VERSION ""

NS_ :

BS_:

BU_: AHLM ASBS CADM CBC DIAGNOST DPDM DTCM ECM EHPS ESC ESL ESM ETM EVCU2 GPF IC IRCM LTM OCM ORC PTS RF_HUB SCCM SGW TBM TCM

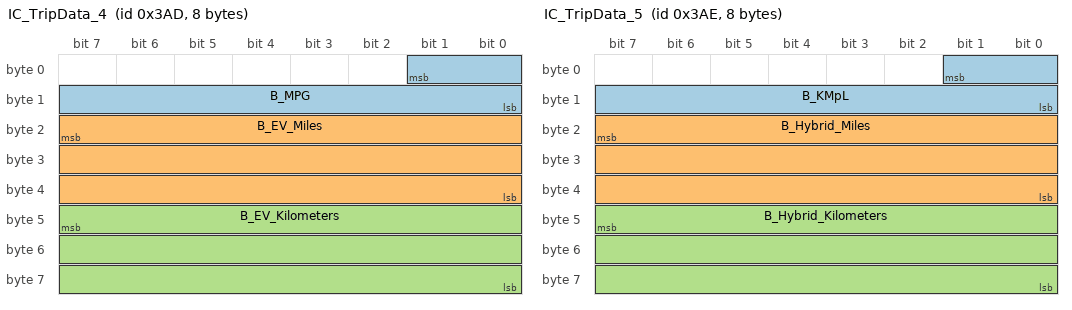
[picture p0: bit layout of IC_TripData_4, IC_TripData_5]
BO_ 941 IC_TripData_4: 8 IC
 SG_ B_MPG : 1|10@0+ (0.1,0) [0|99.9] "MPG"  ETM,SGW,TBM
 SG_ B_EV_Miles : 23|24@0+ (0.1,0) [0|9999.9] "Mile"  ETM,SGW,TBM
 SG_ B_EV_Kilometers : 47|24@0+ (0.1,0) [0|16093.3] "km"  ETM,SGW,TBM

BO_ 942 IC_TripData_5: 8 IC
 SG_ B_KMpL : 1|10@0+ (0.1,0) [0|99.9] "kmpl"  ETM,SGW,TBM
 SG_ B_Hybrid_Miles : 23|24@0+ (0.1,0) [0|9999.9] "Mile"  ETM,SGW,TBM
 SG_ B_Hybrid_Kilometers : 47|24@0+ (0.1,0) [0|16093.3] "km"  ETM,SGW,TBM

BO_ 943 IC_TripData_6: 8 IC
 SG_ B_Total_Dist_Miles : 23|24@0+ (0.1,0) [0|9999.9] "Mile"  ETM,SGW,TBM
 SG_ B_Total_Dist_Kilometers : 47|24@0+ (0.1,0) [0|16093.3] "km"  ETM,SGW,TBM

BO_ 944 TCM_APPL2: 8 DIAGNOST
 SG_ TCM_APPL2 : 7|64@0+ (1,0) [0|0] ""  TCM

BO_ 945 TCM_APPL1: 8 TCM
 SG_ TCM_APPL1 : 7|64@0+ (1,0) [0|0] ""  DIAGNOST,SGW

BO_ 946 TCM_APPL3: 8 TCM
 SG_ TCM_APPL3 : 7|64@0+ (1,0) [0|0] ""  DIAGNOST,SGW

BO_ 947 VehCfgCSM1: 8 CBC
 SG_ VC_PRK_AST_CSO : 2|2@1+ (1,0) [0|0] ""  RF_HUB,SGW
 SG_ VC_PRK_AST_BRK_CSO : 4|1@1+ (1,0) [0|0] ""  RF_HUB,SGW
 SG_ VC_PRK_FT_VOL_CSO : 5|1@1+ (1,0) [0|0] ""  RF_HUB,SGW
 SG_ VC_PRK_RR_VOL_CSO : 6|1@1+ (1,0) [0|0] ""  RF_HUB,SGW
 SG_ VC_EPS_CSO : 7|1@1+ (1,0) [0|0] ""  RF_HUB,SGW
 SG_ VC_FCW_CSO : 8|2@1+ (1,0) [0|0] ""  RF_HUB,SGW
 SG_ VC_FCW_BRK_CSO : 10|1@1+ (1,0) [0|0] ""  RF_HUB,SGW
 SG_ VC_HRN_RMT_LK_CSO : 11|2@1+ (1,0) [0|0] ""  RF_HUB,SGW
 SG_ VC_HRN_RMT_ST_CSO : 13|1@1+ (1,0) [0|0] ""  RF_HUB,SGW
 SG_ VC_HRN_RMT_LWR_CSO : 14|1@1+ (1,0) [0|0] ""  RF_HUB,SGW
 SG_ VC_CHMSL_LINE_CSO : 15|1@1+ (1,0) [0|0] ""  RF_HUB,SGW
 SG_ VC_DCS_CSO : 16|2@1+ (1,0) [0|0] ""  RF_HUB,SGW
 SG_ VC_AUX_SWS_CSO : 18|2@1+ (1,0) [0|0] ""  RF_HUB,SGW
 SG_ VC_CMRA_GRDLNS_CSO : 20|2@1+ (1,0) [0|0] ""  RF_HUB,SGW
 SG_ VC_UNIT_SET_CSO : 22|1@1+ (1,0) [0|0] ""  RF_HUB,SGW
 SG_ VC_POLICE_PE_CSO : 23|1@1+ (1,0) [0|0] ""  RF_HUB,SGW
 SG_ VC_ACC_DLY_CSO : 24|1@1+ (1,0) [0|0] ""  RF_HUB,SGW
 SG_ VC_AFLS_CSO : 25|1@1+ (1,0) [0|0] ""  RF_HUB,SGW
 SG_ VC_AMB_DMR_CSO : 26|1@1+ (1,0) [0|0] ""  RF_HUB,SGW
 SG_ VC_ASCM_TJ_CSO : 27|1@1+ (1,0) [0|0] ""  RF_HUB,SGW
 SG_ VC_ASCM_WRN_CSO : 28|1@1+ (1,0) [0|0] ""  RF_HUB,SGW
 SG_ VC_AUTO_AERO_CSO : 29|1@1+ (1,0) [0|0] ""  RF_HUB,SGW
 SG_ VC_AUTO_HB_CSO : 30|1@1+ (1,0) [0|0] ""  RF_HUB,SGW
 SG_ VC_AUTO_PRK_CSO : 31|1@1+ (1,0) [0|0] ""  RF_HUB,SGW
 SG_ VC_BLIND_SPOT_CSO : 32|1@1+ (1,0) [0|0] ""  RF_HUB,SGW
 SG_ VC_CAPACITY_CSO : 33|1@1+ (1,0) [0|0] ""  RF_HUB,SGW
 SG_ VC_CLK_DSP_CSO : 34|1@1+ (1,0) [0|0] ""  RF_HUB,SGW
 SG_ VC_CMP_CAL_CSO : 35|1@1+ (1,0) [0|0] ""  RF_HUB,SGW
 SG_ VC_CMP_VAR_CSO : 36|1@1+ (1,0) [0|0] ""  RF_HUB,SGW
 SG_ VC_CONS_CSO : 37|1@1+ (1,0) [0|0] ""  RF_HUB,SGW
 SG_ VC_DISTANCE_CSO : 38|1@1+ (1,0) [0|0] ""  RF_HUB,SGW
 SG_ VC_DR_LK_CSO : 39|1@1+ (1,0) [0|0] ""  RF_HUB,SGW
 SG_ VC_DR_UNLK_CSO : 40|1@1+ (1,0) [0|0] ""  RF_HUB,SGW
 SG_ VC_DRL_CSO : 41|1@1+ (1,0) [0|0] ""  RF_HUB,SGW
 SG_ VC_EASY_EXIT_CSO : 42|1@1+ (1,0) [0|0] ""  RF_HUB,SGW
 SG_ VC_ENTRY_EXIT_CSO : 43|1@1+ (1,0) [0|0] ""  RF_HUB,SGW
 SG_ VC_EPB_SERV_CSO : 44|1@1+ (1,0) [0|0] ""  RF_HUB,SGW
 SG_ VC_FLSH_LMP_LK_CSO : 45|1@1+ (1,0) [0|0] ""  RF_HUB,SGW
 SG_ VC_HL_DRP_CSO : 46|1@1+ (1,0) [0|0] ""  RF_HUB,SGW
 SG_ VC_HL_OFF_DLY_CSO : 47|1@1+ (1,0) [0|0] ""  RF_HUB,SGW
 SG_ VC_HL_WPR_CSO : 48|1@1+ (1,0) [0|0] ""  RF_HUB,SGW
 SG_ VC_HSA_CSO : 49|1@1+ (1,0) [0|0] ""  RF_HUB,SGW
 SG_ VC_ILL_APPRCH_CSO : 50|1@1+ (1,0) [0|0] ""  RF_HUB,SGW
 SG_ VC_LDW_TRQ_CSO : 51|1@1+ (1,0) [0|0] ""  RF_HUB,SGW
 SG_ VC_LDW_WRN_CSO : 52|1@1+ (1,0) [0|0] ""  RF_HUB,SGW
 SG_ VC_LGHT_RMT_LWR_CSO : 53|1@1+ (1,0) [0|0] ""  RF_HUB,SGW
 SG_ VC_NAV_TRN_CSO : 54|1@1+ (1,0) [0|0] ""  RF_HUB,SGW
 SG_ VC_PE_CSO : 55|1@1+ (1,0) [0|0] ""  RF_HUB,SGW
 SG_ VC_PER_SHFT_ENBL_CSO : 56|1@1+ (1,0) [0|0] ""  RF_HUB,SGW
 SG_ VC_PER_SHFT_RPM_CSO : 57|1@1+ (1,0) [0|0] ""  RF_HUB,SGW
 SG_ VC_PLG_CHM_CSO : 58|1@1+ (1,0) [0|0] ""  RF_HUB,SGW
 SG_ VC_POWER_CSO : 59|1@1+ (1,0) [0|0] ""  RF_HUB,SGW
 SG_ VC_PRESSURE_CSO : 60|1@1+ (1,0) [0|0] ""  RF_HUB,SGW
 SG_ VC_PTO_CSO : 61|1@1+ (1,0) [0|0] ""  RF_HUB,SGW
 SG_ VC_RAIN_WPR_CSO : 62|1@1+ (1,0) [0|0] ""  RF_HUB,SGW
 SG_ VC_REAR_CMRA_CSO : 63|1@1+ (1,0) [0|0] ""  RF_HUB,SGW
 SG_ VC_VehCfgCSO1_Stat : 0|2@1+ (1,0) [0|0] ""  EVCU2,IC,RF_HUB,SGW

BO_ 948 VehCfgCSM2: 8 CBC
 SG_ VC_TEEN_BLIND_SPOT_CSO : 31|1@1+ (1,0) [0|0] ""  RF_HUB,SGW
 SG_ VC_TEEN_RAIN_WPR_CSO : 32|1@1+ (1,0) [0|0] ""  RF_HUB,SGW
 SG_ VC_TEEN_AUTO_HB_CSO : 33|1@1+ (1,0) [0|0] ""  RF_HUB,SGW
 SG_ VC_TEEN_LGHT_WPR_CSO : 34|1@1+ (1,0) [0|0] ""  RF_HUB,SGW
 SG_ VC_TEEN_SLD_DR_ALRT_CSO : 35|1@1+ (1,0) [0|0] ""  RF_HUB,SGW
 SG_ VC_TEEN_PLG_CHIME_CSO : 36|1@1+ (1,0) [0|0] ""  RF_HUB,SGW
 SG_ VC_SLD_DR_CHM_CSO : 37|1@1+ (1,0) [0|0] ""  RF_HUB,SGW
 SG_ VC_TEEN_SLD_DR_CHM_CSO : 38|1@1+ (1,0) [0|0] ""  RF_HUB,SGW
 SG_ VC_PADDLE_SHIFT_CSO : 39|1@1+ (1,0) [0|0] ""  RF_HUB,SGW
 SG_ VC_FLSH_LMP_SLDR_CSO : 40|1@1+ (1,0) [0|0] ""  RF_HUB,SGW
 SG_ VC_SPEED_WARNING_CSO : 41|2@1+ (1,0) [0|0] ""  RF_HUB,SGW
 SG_ VC_LDW_ON_CSO : 43|1@1+ (1,0) [0|0] ""  RF_HUB,SGW
 SG_ VC_PRK_ASST_TYPE_CSO : 44|1@1+ (1,0) [0|0] ""  RF_HUB,SGW
 SG_ VC_SPEED_CSO : 5|1@1+ (1,0) [0|0] ""  RF_HUB,SGW
 SG_ VC_TLT_MRR_CSO : 6|1@1+ (1,0) [0|0] ""  RF_HUB,SGW
 SG_ VC_TORQUE_CSO : 7|1@1+ (1,0) [0|0] ""  RF_HUB,SGW
 SG_ VC_TRLR_CSO : 8|1@1+ (1,0) [0|0] ""  RF_HUB,SGW
 SG_ VC_TRLR_NAME_CSO : 9|1@1+ (1,0) [0|0] ""  RF_HUB,SGW
 SG_ VC_TRLR_TYPE_CSO : 10|1@1+ (1,0) [0|0] ""  RF_HUB,SGW
 SG_ VC_TRNS_MD_CSO : 11|1@1+ (1,0) [0|0] ""  RF_HUB,SGW
 SG_ VC_US_METRIC_CSO : 12|1@1+ (1,0) [0|0] ""  RF_HUB,SGW
 SG_ VC_EPB_ON_CSO : 45|1@1+ (1,0) [0|0] ""  RF_HUB,SGW
 SG_ VC_AIRBAG_ON_CSO : 46|1@1+ (1,0) [0|0] ""  IC,RF_HUB,SGW
 SG_ VC_FCW_SW_CSO : 47|1@1+ (1,0) [0|0] ""  RF_HUB,SGW
 SG_ VC_FCW_WARN_BRK_CSO : 49|1@1+ (1,0) [0|0] ""  RF_HUB,SGW
 SG_ VC_DOORS_OFF_ACC_DLY_CSO : 50|1@1+ (1,0) [0|0] ""  RF_HUB,SGW
 SG_ VC_TEEN_PRK_ASST_BRK_CSO : 51|1@1+ (1,0) [0|0] ""  RF_HUB,SGW
 SG_ VC_PCS_CSO : 52|1@1+ (1,0) [0|0] ""  RF_HUB,SGW
 SG_ VC_BSM_TRLR_CSO : 53|1@1+ (1,0) [0|0] ""  RF_HUB,SGW
 SG_ VC_AUTO_SS_CSO : 54|1@1+ (1,0) [0|0] ""  RF_HUB,SGW
 SG_ VC_RDY_DRV_CSO : 55|1@1+ (1,0) [0|0] ""  RF_HUB,SGW
 SG_ VC_VehCfgCSO2_Stat : 0|2@1+ (1,0) [0|0] ""  EVCU2,IC,RF_HUB,SGW
 SG_ VC_REAR_CMRA_DLY_CSO : 2|1@1+ (1,0) [0|0] ""  RF_HUB,SGW
 SG_ VC_RKE_MEM_CSO : 3|1@1+ (1,0) [0|0] ""  RF_HUB,SGW
 SG_ VC_RKE_UNLK_CSO : 4|1@1+ (1,0) [0|0] ""  RF_HUB,SGW
 SG_ VC_WHL_ALGN_CSO : 13|1@1+ (1,0) [0|0] ""  RF_HUB,SGW
 SG_ VC_FUEL_SAV_CSO : 14|1@1+ (1,0) [0|0] ""  RF_HUB,SGW
 SG_ VC_TEMP_CSO : 15|1@1+ (1,0) [0|0] ""  RF_HUB,SGW
 SG_ VC_HOLD_N_GO_CSO : 16|1@1+ (1,0) [0|0] ""  RF_HUB,SGW
 SG_ VC_PWR_FLD_MRR_CSO : 17|1@1+ (1,0) [0|0] ""  RF_HUB,SGW
 SG_ VC_HANDS_FREE_LFT_CSO : 18|1@1+ (1,0) [0|0] ""  RF_HUB,SGW
 SG_ VC_HANDS_FREE_SLDR_CSO : 19|1@1+ (1,0) [0|0] ""  RF_HUB,SGW
 SG_ VC_SVC_GRIDLINES_CSO : 20|1@1+ (1,0) [0|0] ""  RF_HUB,SGW
 SG_ VC_SVC_DELAY_CSO : 21|1@1+ (1,0) [0|0] ""  RF_HUB,SGW
 SG_ VC_SLD_DR_ALRT_CSO : 22|1@1+ (1,0) [0|0] ""  RF_HUB,SGW
 SG_ VC_TEEN_FCW_SENS_CSO : 23|1@1+ (1,0) [0|0] ""  RF_HUB,SGW
 SG_ VC_TEEN_FCW_BRK_CSO : 24|1@1+ (1,0) [0|0] ""  RF_HUB,SGW
 SG_ VC_TEEN_PRK_ASST_CSO : 25|1@1+ (1,0) [0|0] ""  RF_HUB,SGW
 SG_ VC_TEEN_FT_PRK_VOL_CSO : 26|1@1+ (1,0) [0|0] ""  RF_HUB,SGW
 SG_ VC_TEEN_RR_PRK_VOL_CSO : 27|1@1+ (1,0) [0|0] ""  RF_HUB,SGW
 SG_ VC_TEEN_MAX_SPEED_CSO : 28|1@1+ (1,0) [0|0] ""  RF_HUB,SGW
 SG_ VC_TEEN_FUEL_WRN_CSO : 29|1@1+ (1,0) [0|0] ""  RF_HUB,SGW
 SG_ VC_TEEN_FUEL_POPUP_CSO : 30|1@1+ (1,0) [0|0] ""  RF_HUB,SGW

BO_ 949 VehCfgCSM1_BU: 8 RF_HUB
 SG_ VC_BU_VehCfgCSO1_Stat : 0|2@1+ (1,0) [0|0] ""  CBC,SGW
 SG_ VC_BU_PRK_AST_CSO : 2|2@1+ (1,0) [0|0] ""  CBC,SGW
 SG_ VC_BU_PRK_AST_BRK_CSO : 4|1@1+ (1,0) [0|0] ""  CBC,SGW
 SG_ VC_BU_PRK_FT_VOL_CSO : 5|1@1+ (1,0) [0|0] ""  CBC,SGW
 SG_ VC_BU_PRK_RR_VOL_CSO : 6|1@1+ (1,0) [0|0] ""  CBC,SGW
 SG_ VC_BU_EPS_CSO : 7|1@1+ (1,0) [0|0] ""  CBC,SGW
 SG_ VC_BU_FCW_CSO : 8|2@1+ (1,0) [0|0] ""  CBC,SGW
 SG_ VC_BU_FCW_BRK_CSO : 10|1@1+ (1,0) [0|0] ""  CBC,SGW
 SG_ VC_BU_HRN_RMT_LK_CSO : 11|2@1+ (1,0) [0|0] ""  CBC,SGW
 SG_ VC_BU_HRN_RMT_ST_CSO : 13|1@1+ (1,0) [0|0] ""  CBC,SGW
 SG_ VC_BU_HRN_RMT_LWR_CSO : 14|1@1+ (1,0) [0|0] ""  CBC,SGW
 SG_ VC_BU_CHMSL_LINE_CSO : 15|1@1+ (1,0) [0|0] ""  CBC,SGW
 SG_ VC_BU_DCS_CSO : 16|2@1+ (1,0) [0|0] ""  CBC,SGW
 SG_ VC_BU_AUX_SWS_CSO : 18|2@1+ (1,0) [0|0] ""  CBC,SGW
 SG_ VC_BU_CMRA_GRDLNS_CSO : 20|2@1+ (1,0) [0|0] ""  CBC,SGW
 SG_ VC_BU_UNIT_SET_CSO : 22|1@1+ (1,0) [0|0] ""  CBC,SGW
 SG_ VC_BU_POLICE_PE_CSO : 23|1@1+ (1,0) [0|0] ""  CBC,SGW
 SG_ VC_BU_ACC_DLY_CSO : 24|1@1+ (1,0) [0|0] ""  CBC,SGW
 SG_ VC_BU_AFLS_CSO : 25|1@1+ (1,0) [0|0] ""  CBC,SGW
 SG_ VC_BU_AMB_DMR_CSO : 26|1@1+ (1,0) [0|0] ""  CBC,SGW
 SG_ VC_BU_ASCM_TJ_CSO : 27|1@1+ (1,0) [0|0] ""  CBC,SGW
 SG_ VC_BU_ASCM_WRN_CSO : 28|1@1+ (1,0) [0|0] ""  CBC,SGW
 SG_ VC_BU_AUTO_AERO_CSO : 29|1@1+ (1,0) [0|0] ""  CBC,SGW
 SG_ VC_BU_AUTO_HB_CSO : 30|1@1+ (1,0) [0|0] ""  CBC,SGW
 SG_ VC_BU_AUTO_PRK_CSO : 31|1@1+ (1,0) [0|0] ""  CBC,SGW
 SG_ VC_BU_BLIND_SPOT_CSO : 32|1@1+ (1,0) [0|0] ""  CBC,SGW
 SG_ VC_BU_CAPACITY_CSO : 33|1@1+ (1,0) [0|0] ""  CBC,SGW
 SG_ VC_BU_CLK_DSP_CSO : 34|1@1+ (1,0) [0|0] ""  CBC,SGW
 SG_ VC_BU_CMP_CAL_CSO : 35|1@1+ (1,0) [0|0] ""  CBC,SGW
 SG_ VC_BU_CMP_VAR_CSO : 36|1@1+ (1,0) [0|0] ""  CBC,SGW
 SG_ VC_BU_CONS_CSO : 37|1@1+ (1,0) [0|0] ""  CBC,SGW
 SG_ VC_BU_DISTANCE_CSO : 38|1@1+ (1,0) [0|0] ""  CBC,SGW
 SG_ VC_BU_DR_LK_CSO : 39|1@1+ (1,0) [0|0] ""  CBC,SGW
 SG_ VC_BU_DR_UNLK_CSO : 40|1@1+ (1,0) [0|0] ""  CBC,SGW
 SG_ VC_BU_DRL_CSO : 41|1@1+ (1,0) [0|0] ""  CBC,SGW
 SG_ VC_BU_EASY_EXIT_CSO : 42|1@1+ (1,0) [0|0] ""  CBC,SGW
 SG_ VC_BU_ENTRY_EXIT_CSO : 43|1@1+ (1,0) [0|0] ""  CBC,SGW
 SG_ VC_BU_EPB_SERV_CSO : 44|1@1+ (1,0) [0|0] ""  CBC,SGW
 SG_ VC_BU_FLSH_LMP_LK_CSO : 45|1@1+ (1,0) [0|0] ""  CBC,SGW
 SG_ VC_BU_HL_DRP_CSO : 46|1@1+ (1,0) [0|0] ""  CBC,SGW
 SG_ VC_BU_HL_OFF_DLY_CSO : 47|1@1+ (1,0) [0|0] ""  CBC,SGW
 SG_ VC_BU_HL_WPR_CSO : 48|1@1+ (1,0) [0|0] ""  CBC,SGW
 SG_ VC_BU_HSA_CSO : 49|1@1+ (1,0) [0|0] ""  CBC,SGW
 SG_ VC_BU_ILL_APPRCH_CSO : 50|1@1+ (1,0) [0|0] ""  CBC,SGW
 SG_ VC_BU_LDW_TRQ_CSO : 51|1@1+ (1,0) [0|0] ""  CBC,SGW
 SG_ VC_BU_LDW_WRN_CSO : 52|1@1+ (1,0) [0|0] ""  CBC,SGW
 SG_ VC_BU_LGHT_RMT_LWR_CSO : 53|1@1+ (1,0) [0|0] ""  CBC,SGW
 SG_ VC_BU_NAV_TRN_CSO : 54|1@1+ (1,0) [0|0] ""  CBC,SGW
 SG_ VC_BU_PE_CSO : 55|1@1+ (1,0) [0|0] ""  CBC,SGW
 SG_ VC_BU_PER_SHFT_ENBL_CSO : 56|1@1+ (1,0) [0|0] ""  CBC,SGW
 SG_ VC_BU_PER_SHFT_RPM_CSO : 57|1@1+ (1,0) [0|0] ""  CBC,SGW
 SG_ VC_BU_PLG_CHM_CSO : 58|1@1+ (1,0) [0|0] ""  CBC,SGW
 SG_ VC_BU_POWER_CSO : 59|1@1+ (1,0) [0|0] ""  CBC,SGW
 SG_ VC_BU_PRESSURE_CSO : 60|1@1+ (1,0) [0|0] ""  CBC,SGW
 SG_ VC_BU_PTO_CSO : 61|1@1+ (1,0) [0|0] ""  CBC,SGW
 SG_ VC_BU_RAIN_WPR_CSO : 62|1@1+ (1,0) [0|0] ""  CBC,SGW
 SG_ VC_BU_REAR_CMRA_CSO : 63|1@1+ (1,0) [0|0] ""  CBC,SGW

BO_ 950 VehCfgCSM2_BU: 8 RF_HUB
 SG_ VC_BU_HOLD_N_GO_CSO : 16|1@1+ (1,0) [0|0] ""  CBC,SGW
 SG_ VC_BU_PADDLE_SHIFT_CSO : 39|1@1+ (1,0) [0|0] ""  CBC,SGW
 SG_ VC_BU_FLSH_LMP_SLDR_CSO : 40|1@1+ (1,0) [0|0] ""  CBC,SGW
 SG_ VC_BU_SPEED_WARNING_CSO : 41|2@1+ (1,0) [0|0] ""  CBC,SGW
 SG_ VC_BU_LDW_ON_CSO : 43|1@1+ (1,0) [0|0] ""  CBC,SGW
 SG_ VC_BU_PRK_ASST_TYPE_CSO : 44|1@1+ (1,0) [0|0] ""  CBC,SGW
 SG_ VC_BU_EPB_ON_CSO : 45|1@1+ (1,0) [0|0] ""  CBC,SGW
 SG_ VC_BU_AIRBAG_ON_CSO : 46|1@1+ (1,0) [0|0] ""  CBC,SGW
 SG_ VC_BU_FCW_SW_CSO : 47|1@1+ (1,0) [0|0] ""  CBC,SGW
 SG_ VC_BU_FCW_WARN_BRK_CSO : 49|1@1+ (1,0) [0|0] ""  CBC,SGW
 SG_ VC_BU_DOORS_OFF_ACC_DLY_CSO : 50|1@1+ (1,0) [0|0] ""  CBC,SGW
 SG_ VC_BU_TEEN_PRK_ASST_BRK_CSO : 51|1@1+ (1,0) [0|0] ""  CBC,SGW
 SG_ VC_BU_PWR_FLD_MRR_CSO : 17|1@1+ (1,0) [0|0] ""  CBC,SGW
 SG_ VC_BU_HANDS_FREE_LFT_CSO : 18|1@1+ (1,0) [0|0] ""  CBC,SGW
 SG_ VC_BU_HANDS_FREE_SLDR_CSO : 19|1@1+ (1,0) [0|0] ""  CBC,SGW
 SG_ VC_BU_SVC_GRIDLINES_CSO : 20|1@1+ (1,0) [0|0] ""  CBC,SGW
 SG_ VC_BU_SVC_DELAY_CSO : 21|1@1+ (1,0) [0|0] ""  CBC,SGW
 SG_ VC_BU_SLD_DR_ALRT_CSO : 22|1@1+ (1,0) [0|0] ""  CBC,SGW
 SG_ VC_BU_TEEN_FCW_SENS_CSO : 23|1@1+ (1,0) [0|0] ""  CBC,SGW
 SG_ VC_BU_TEEN_FCW_BRK_CSO : 24|1@1+ (1,0) [0|0] ""  CBC,SGW
 SG_ VC_BU_TEEN_PRK_ASST_CSO : 25|1@1+ (1,0) [0|0] ""  CBC,SGW
 SG_ VC_BU_TEEN_FT_PRK_VOL_CSO : 26|1@1+ (1,0) [0|0] ""  CBC,SGW
 SG_ VC_BU_TEEN_RR_PRK_VOL_CSO : 27|1@1+ (1,0) [0|0] ""  CBC,SGW
 SG_ VC_BU_TEEN_MAX_SPEED_CSO : 28|1@1+ (1,0) [0|0] ""  CBC,SGW
 SG_ VC_BU_TEEN_FUEL_WRN_CSO : 29|1@1+ (1,0) [0|0] ""  CBC,SGW
 SG_ VC_BU_TEEN_FUEL_POPUP_CSO : 30|1@1+ (1,0) [0|0] ""  CBC,SGW
 SG_ VC_BU_TEEN_BLIND_SPOT_CSO : 31|1@1+ (1,0) [0|0] ""  CBC,SGW
 SG_ VC_BU_TEEN_RAIN_WPR_CSO : 32|1@1+ (1,0) [0|0] ""  CBC,SGW
 SG_ VC_BU_TEEN_AUTO_HB_CSO : 33|1@1+ (1,0) [0|0] ""  CBC,SGW
 SG_ VC_BU_TEEN_LGHT_WPR_CSO : 34|1@1+ (1,0) [0|0] ""  CBC,SGW
 SG_ VC_BU_TEEN_SLD_DR_ALRT_CSO : 35|1@1+ (1,0) [0|0] ""  CBC,SGW
 SG_ VC_BU_TEEN_PLG_CHIME_CSO : 36|1@1+ (1,0) [0|0] ""  CBC,SGW
 SG_ VC_BU_SLD_DR_CHM_CSO : 37|1@1+ (1,0) [0|0] ""  CBC,SGW
 SG_ VC_BU_TEEN_SLD_DR_CHM_CSO : 38|1@1+ (1,0) [0|0] ""  CBC,SGW
 SG_ VC_BU_PCS_CSO : 52|1@1+ (1,0) [0|0] ""  CBC,SGW
 SG_ VC_BU_BSM_TRLR_CSO : 53|1@1+ (1,0) [0|0] ""  CBC,SGW
 SG_ VC_BU_AUTO_SS_CSO : 54|1@1+ (1,0) [0|0] ""  CBC,SGW
 SG_ VC_BU_RDY_DRV_CSO : 55|1@1+ (1,0) [0|0] ""  CBC,SGW
 SG_ VC_BU_VehCfgCSO2_Stat : 0|2@1+ (1,0) [0|0] ""  CBC,SGW
 SG_ VC_BU_REAR_CMRA_DLY_CSO : 2|1@1+ (1,0) [0|0] ""  CBC,SGW
 SG_ VC_BU_RKE_MEM_CSO : 3|1@1+ (1,0) [0|0] ""  CBC,SGW
 SG_ VC_BU_RKE_UNLK_CSO : 4|1@1+ (1,0) [0|0] ""  CBC,SGW
 SG_ VC_BU_SPEED_CSO : 5|1@1+ (1,0) [0|0] ""  CBC,SGW
 SG_ VC_BU_TLT_MRR_CSO : 6|1@1+ (1,0) [0|0] ""  CBC,SGW
 SG_ VC_BU_TORQUE_CSO : 7|1@1+ (1,0) [0|0] ""  CBC,SGW
 SG_ VC_BU_TRLR_CSO : 8|1@1+ (1,0) [0|0] ""  CBC,SGW
 SG_ VC_BU_TRLR_NAME_CSO : 9|1@1+ (1,0) [0|0] ""  CBC,SGW
 SG_ VC_BU_TRLR_TYPE_CSO : 10|1@1+ (1,0) [0|0] ""  CBC,SGW
 SG_ VC_BU_TRNS_MD_CSO : 11|1@1+ (1,0) [0|0] ""  CBC,SGW
 SG_ VC_BU_US_METRIC_CSO : 12|1@1+ (1,0) [0|0] ""  CBC,SGW
 SG_ VC_BU_WHL_ALGN_CSO : 13|1@1+ (1,0) [0|0] ""  CBC,SGW
 SG_ VC_BU_FUEL_SAV_CSO : 14|1@1+ (1,0) [0|0] ""  CBC,SGW
 SG_ VC_BU_TEMP_CSO : 15|1@1+ (1,0) [0|0] ""  CBC,SGW

BO_TX_BU_ 944 : DIAGNOST,SGW;
CM_ SG_ 941 B_MPG "Trip B Combined fuel economy in US MPG";
CM_ SG_ 941 B_EV_Miles "Trip B EV distance in US miles";
CM_ SG_ 941 B_EV_Kilometers "Trip B EV distance in kilometers";
CM_ SG_ 942 B_KMpL "Trip B Combined fuel economy in Km/L";
CM_ SG_ 942 B_Hybrid_Miles "Trip B hybrid distance in US miles";
CM_ SG_ 942 B_Hybrid_Kilometers "Trip B hybrid distance in kilometers";
CM_ SG_ 943 B_Total_Dist_Miles "Trip B total distance in US miles";
CM_ SG_ 943 B_Total_Dist_Kilometers "Trip B total distance in kilometers";
CM_ SG_ 944 TCM_APPL2 "CCP to transmission";
CM_ SG_ 945 TCM_APPL1 "CCP from transmission";
CM_ SG_ 946 TCM_APPL3 "CCP from transmission";
CM_ SG_ 947 VC_PRK_AST_CSO "Park assist customer settings menu";
CM_ SG_ 947 VC_PRK_AST_BRK_CSO "Park assist brake customer settings menu; Present = [1]";
CM_ SG_ 947 VC_PRK_FT_VOL_CSO "Park assist front volume customer settings menu; Present = [1]";
CM_ SG_ 947 VC_PRK_RR_VOL_CSO "Park assist rear volume customer settings menu; Present = [1]";
CM_ SG_ 947 VC_EPS_CSO "Electric power steering customer settings menu; Present = [1]";
CM_ SG_ 947 VC_FCW_CSO "Forward collision warning customer settings menu";
CM_ SG_ 947 VC_FCW_BRK_CSO "Forward collision mitigation braking customer settings menu; Present = [1]";
CM_ SG_ 947 VC_HRN_RMT_LK_CSO "Sound horn with remote lock customer settings menu";
CM_ SG_ 947 VC_HRN_RMT_ST_CSO "Sound horn with remote start customer settings menu; Present = [1]";
CM_ SG_ 947 VC_HRN_RMT_LWR_CSO "Sound horn with remote lower customer settings menu; Present = [1]";
CM_ SG_ 947 VC_CHMSL_LINE_CSO "CHMSL line menu; Present = [1]";
CM_ SG_ 947 VC_DCS_CSO "Auto on driver comfort customer settings menu";
CM_ SG_ 947 VC_AUX_SWS_CSO "Auxiliary switches customer settings menu";
CM_ SG_ 947 VC_CMRA_GRDLNS_CSO "Rear view camera gridlines customer settings menu";
CM_ SG_ 947 VC_UNIT_SET_CSO "Unit set customer settings menu; Present = [1]";
CM_ SG_ 947 VC_POLICE_PE_CSO "Police passive entry settings menu; Present = [1]";
CM_ SG_ 947 VC_ACC_DLY_CSO "Power accessory delay customer settings menu; Present = [1]";
CM_ SG_ 947 VC_AFLS_CSO "Adaptive front light system customer settings menu; Present = [1]";
CM_ SG_ 947 VC_AMB_DMR_CSO "Ambient dimmer customer settings menu; Present = [1]";
CM_ SG_ 947 VC_ASCM_TJ_CSO "Tire jack mode customer settings menu; Present = [1]";
CM_ SG_ 947 VC_ASCM_WRN_CSO "Air suspension warning customer settings menu; Present = [1]";
CM_ SG_ 947 VC_AUTO_AERO_CSO "Automatic aero mode customer settings menu; Present = [1]";
CM_ SG_ 947 VC_AUTO_HB_CSO "Auto high beam customer settings menu; Present = [1]";
CM_ SG_ 947 VC_AUTO_PRK_CSO "Auto park customer settings menu; Present = [1]";
CM_ SG_ 947 VC_BLIND_SPOT_CSO "Blind spot alert customer settings menu; Present = [1]";
CM_ SG_ 947 VC_CAPACITY_CSO "Capacity unit customer settings menu; Present = [1]";
CM_ SG_ 947 VC_CLK_DSP_CSO "Clock display customer settings menu; Present = [1]";
CM_ SG_ 947 VC_CMP_CAL_CSO "Compass calibration customer settings menu; Present = [1]";
CM_ SG_ 947 VC_CMP_VAR_CSO "Compass variance customer settings menu; Present = [1]";
CM_ SG_ 947 VC_CONS_CSO "Consumption unit customer settings menu; Present = [1]";
CM_ SG_ 947 VC_DISTANCE_CSO "Distance unit customer settings menu; Present = [1]";
CM_ SG_ 947 VC_DR_LK_CSO "Auto door lock customer settings menu; Present = [1]";
CM_ SG_ 947 VC_DR_UNLK_CSO "Auto door unlock customer settings menu; Present = [1]";
CM_ SG_ 947 VC_DRL_CSO "Daytime running lights customer settings menu; Present = [1]";
CM_ SG_ 947 VC_EASY_EXIT_CSO "Easy exit seat customer settings menu; Present = [1]";
CM_ SG_ 947 VC_ENTRY_EXIT_CSO "Auto entry exit mode customer settings menu; Present = [1]";
CM_ SG_ 947 VC_EPB_SERV_CSO "EPB service mode customer settings menu; Present = [1]";
CM_ SG_ 947 VC_FLSH_LMP_LK_CSO "Flash lamps with lock customer settings menu; Present = [1]";
CM_ SG_ 947 VC_HL_DRP_CSO "Headlamp drop customer settings menu; Present = [1]";
CM_ SG_ 947 VC_HL_OFF_DLY_CSO "Headlamp off delay customer settings menu; Present = [1]";
CM_ SG_ 947 VC_HL_WPR_CSO "Headlamps on with wiper customer settings menu; Present = [1]";
CM_ SG_ 947 VC_HSA_CSO "Hill start assist customer settings menu; Present = [1]";
CM_ SG_ 947 VC_ILL_APPRCH_CSO "Illuminated approach customer settings menu; Present = [1]";
CM_ SG_ 947 VC_LDW_TRQ_CSO "Lane departure torque customer settings menu; Present = [1]";
CM_ SG_ 947 VC_LDW_WRN_CSO "Lane departure warning customer settings menu; Present = [1]";
CM_ SG_ 947 VC_LGHT_RMT_LWR_CSO "Flash lights with remote lower customer settings menu; Present = [1]";
CM_ SG_ 947 VC_NAV_TRN_CSO "Nav turn by turn customer settings menu; Present = [1]";
CM_ SG_ 947 VC_PE_CSO "Passive entry customer settings menu; Present = [1]";
CM_ SG_ 947 VC_PER_SHFT_ENBL_CSO "Performance shift enable customer settings menu; Present = [1]";
CM_ SG_ 947 VC_PER_SHFT_RPM_CSO "Performance shift rpm customer settings menu; Present = [1]";
CM_ SG_ 947 VC_PLG_CHM_CSO "Power liftgate chime customer settings menu; Present = [1]";
CM_ SG_ 947 VC_POWER_CSO "Power unit customer settings menu; Present = [1]";
CM_ SG_ 947 VC_PRESSURE_CSO "Pressure unit customer settings menu; Present = [1]";
CM_ SG_ 947 VC_PTO_CSO "Power take off customer settings menu; Present = [1]";
CM_ SG_ 947 VC_RAIN_WPR_CSO "Rain sensitive wipers customer settings menu; Present = [1]";
CM_ SG_ 947 VC_REAR_CMRA_CSO "Rear camera customer settings menu; Present = [1]";
CM_ SG_ 947 VC_VehCfgCSO1_Stat "Configuration message CSO1 status";
CM_ SG_ 948 VC_TEEN_BLIND_SPOT_CSO "Teen key blind spot customer setting menu: Present = 1";
CM_ SG_ 948 VC_TEEN_RAIN_WPR_CSO "Teen key rain sensitive wiper customer setting menu: Present = 1";
CM_ SG_ 948 VC_TEEN_AUTO_HB_CSO "Teen key automatic highbeam customer setting menu: Present = 1";
CM_ SG_ 948 VC_TEEN_LGHT_WPR_CSO "Teen key lights on with wipers customer setting menu: Present = 1";
CM_ SG_ 948 VC_TEEN_SLD_DR_ALRT_CSO "Teen key sliding door alert customer setting menu: Present = 1";
CM_ SG_ 948 VC_TEEN_PLG_CHIME_CSO "Teen key power lift gate chime customer setting menu: Present = 1";
CM_ SG_ 948 VC_SLD_DR_CHM_CSO "Sliding door chime customer setting menu present: Present = 1";
CM_ SG_ 948 VC_TEEN_SLD_DR_CHM_CSO "Teen key sliding door chime customer setting menu present: Present = 1";
CM_ SG_ 948 VC_PADDLE_SHIFT_CSO "Paddle shifter customer setting menu present.  Present = [1]";
CM_ SG_ 948 VC_FLSH_LMP_SLDR_CSO "Flash lamps with sliding door customer settings menu; Present = [1]";
CM_ SG_ 948 VC_SPEED_WARNING_CSO "Speed warning  customer setting";
CM_ SG_ 948 VC_LDW_ON_CSO "LDW on/off customer setting menu present.  Present = 1.";
CM_ SG_ 948 VC_PRK_ASST_TYPE_CSO "Park assist type customer setting menu present. Present = 1.";
CM_ SG_ 948 VC_SPEED_CSO "Speed unit customer settings menu; Present = [1]";
CM_ SG_ 948 VC_TLT_MRR_CSO "Tilt mirror in reverse customer settings menu; Present = [1]";
CM_ SG_ 948 VC_TORQUE_CSO "Torque unit customer settings menu; Present = [1]";
CM_ SG_ 948 VC_TRLR_CSO "Trailer selected customer settings menu; Present = [1]";
CM_ SG_ 948 VC_TRLR_NAME_CSO "Trailer name customer settings menu; Present = [1]";
CM_ SG_ 948 VC_TRLR_TYPE_CSO "Trailer type customer settings menu; Present = [1]";
CM_ SG_ 948 VC_TRNS_MD_CSO "Transport mode customer settings menu; Present = [1]";
CM_ SG_ 948 VC_US_METRIC_CSO "US metric customer settings menu; Present = [1]";
CM_ SG_ 948 VC_EPB_ON_CSO "EPB on/off customer setting menu present. Present = 1.";
CM_ SG_ 948 VC_AIRBAG_ON_CSO "Passenger airbag on/off customer setting menu present. Present = 1.";
CM_ SG_ 948 VC_FCW_SW_CSO "FCW Switch customer setting menu present.  Present = 1";
CM_ SG_ 948 VC_FCW_WARN_BRK_CSO "FCW single setting (warning and brake) customer setting menu.  Present = 1";
CM_ SG_ 948 VC_DOORS_OFF_ACC_DLY_CSO "Doors & engine off power delay customer settings menu backup. Present = 1";
CM_ SG_ 948 VC_TEEN_PRK_ASST_BRK_CSO "Teen key park assist brake customer settings menu.  Present = 1";
CM_ SG_ 948 VC_PCS_CSO "Auto on passenger comfort customer settings menu. Present = 1";
CM_ SG_ 948 VC_BSM_TRLR_CSO "Blind spot with trailer customer settings menu. Present = 1";
CM_ SG_ 948 VC_AUTO_SS_CSO "Automatic side step customer settings menu. Present = 1";
CM_ SG_ 948 VC_RDY_DRV_CSO "Disable ready to drive popup customer settings menu. Present = 1";
CM_ SG_ 948 VC_VehCfgCSO2_Stat "Configuration message CSO2 status";
CM_ SG_ 948 VC_REAR_CMRA_DLY_CSO "Rear view camera delay customer settings menu; Present = [1]";
CM_ SG_ 948 VC_RKE_MEM_CSO "RKE linked to memory customer settings menu; Present = [1]";
CM_ SG_ 948 VC_RKE_UNLK_CSO "RKE unlock customer settings menu; Present = [1]";
CM_ SG_ 948 VC_WHL_ALGN_CSO "Wheel alignment customer settings menu; Present = [1]";
CM_ SG_ 948 VC_FUEL_SAV_CSO "Fuel Saver settings menu; Present = [1]";
CM_ SG_ 948 VC_TEMP_CSO "Temperature Unit settings menu; Present = [1]";
CM_ SG_ 948 VC_HOLD_N_GO_CSO "Hold and go customer setting menu: Present = 1";
CM_ SG_ 948 VC_PWR_FLD_MRR_CSO "Power folding mirror customer setting menu: Present = 1";
CM_ SG_ 948 VC_HANDS_FREE_LFT_CSO "Hands free liftgate customer setting menu: Present = 1";
CM_ SG_ 948 VC_HANDS_FREE_SLDR_CSO "Hands free sliding door customer setting menu: Present = 1";
CM_ SG_ 948 VC_SVC_GRIDLINES_CSO "Surround view camera gridlines customer setting menu: Present = 1";
CM_ SG_ 948 VC_SVC_DELAY_CSO "Surround view camera delay customer setting menu: Present = 1";
CM_ SG_ 948 VC_SLD_DR_ALRT_CSO "Sliding door alert customer setting menu: Present = 1";
CM_ SG_ 948 VC_TEEN_FCW_SENS_CSO "Teen key FCW sensitivity customer setting menu: Present = 1";
CM_ SG_ 948 VC_TEEN_FCW_BRK_CSO "Teen key FCW braking customer setting menu: Present = 1";
CM_ SG_ 948 VC_TEEN_PRK_ASST_CSO "Teen key park assist customer setting menu: Present = 1";
CM_ SG_ 948 VC_TEEN_FT_PRK_VOL_CSO "Teen key front park assist chime volume customer setting menu: Present = 1";
CM_ SG_ 948 VC_TEEN_RR_PRK_VOL_CSO "Teen key rear park assist chime volume customer setting menu: Present = 1";
CM_ SG_ 948 VC_TEEN_MAX_SPEED_CSO "Teen key max speed customer setting menu: Present = 1";
CM_ SG_ 948 VC_TEEN_FUEL_WRN_CSO "Teen key early fuel warning customer setting menu: Present = 1";
CM_ SG_ 948 VC_TEEN_FUEL_POPUP_CSO "Teen key fuel pop-up customer setting menu: Present = 1";
CM_ SG_ 949 VC_BU_VehCfgCSO1_Stat "Backup for Configuration message CSO1 status";
CM_ SG_ 949 VC_BU_PRK_AST_CSO "Backup for park assist customer settings menu";
CM_ SG_ 949 VC_BU_PRK_AST_BRK_CSO "Backup for park assist brake customer settings menu";
CM_ SG_ 949 VC_BU_PRK_FT_VOL_CSO "Backup for park assist front volume customer settings menu";
CM_ SG_ 949 VC_BU_PRK_RR_VOL_CSO "Backup for park assist rear volume customer settings menu";
CM_ SG_ 949 VC_BU_EPS_CSO "Backup for electric power steering customer settings menu";
CM_ SG_ 949 VC_BU_FCW_CSO "Backup for Forward collision warning customer settings menu";
CM_ SG_ 949 VC_BU_FCW_BRK_CSO "Backup for Forward collision mitigation braking customer settings menu";
CM_ SG_ 949 VC_BU_HRN_RMT_LK_CSO "Backup for Sound horn with remote lock customer settings menu";
CM_ SG_ 949 VC_BU_HRN_RMT_ST_CSO "Backup for Sound horn with remote start customer settings menu";
CM_ SG_ 949 VC_BU_HRN_RMT_LWR_CSO "Backup for Sound horn with remote lower customer settings menu";
CM_ SG_ 949 VC_BU_CHMSL_LINE_CSO "Backup for CHMSL line customer settings menu";
CM_ SG_ 949 VC_BU_DCS_CSO "Backup for Auto on driver comfort customer settings menu";
CM_ SG_ 949 VC_BU_AUX_SWS_CSO "Backup for Auxiliary switches customer settings menu";
CM_ SG_ 949 VC_BU_CMRA_GRDLNS_CSO "Backup for Rear view camera gridlines customer settings menu";
CM_ SG_ 949 VC_BU_UNIT_SET_CSO "Backup for unit set customer settings menu; Present = [1]";
CM_ SG_ 949 VC_BU_POLICE_PE_CSO "Backup for police passive entry settings menu; Present = [1]";
CM_ SG_ 949 VC_BU_ACC_DLY_CSO "Backup for Power accessory delay customer settings menu";
CM_ SG_ 949 VC_BU_AFLS_CSO "Backup for Adaptive front light system customer settings menu";
CM_ SG_ 949 VC_BU_AMB_DMR_CSO "Backup for Ambient dimmer customer settings menu";
CM_ SG_ 949 VC_BU_ASCM_TJ_CSO "Backup for Tire jack mode customer settings menu";
CM_ SG_ 949 VC_BU_ASCM_WRN_CSO "Backup for Air suspension warning customer settings menu";
CM_ SG_ 949 VC_BU_AUTO_AERO_CSO "Backup for Automatic aero mode customer settings menu";
CM_ SG_ 949 VC_BU_AUTO_HB_CSO "Backup for Auto high beam customer settings menu";
CM_ SG_ 949 VC_BU_AUTO_PRK_CSO "Backup for Auto park customer settings menu";
CM_ SG_ 949 VC_BU_BLIND_SPOT_CSO "Backup for Blind spot alert customer settings menu";
CM_ SG_ 949 VC_BU_CAPACITY_CSO "Backup for Capacity unit customer settings menu";
CM_ SG_ 949 VC_BU_CLK_DSP_CSO "Backup for Clock display customer settings menu";
CM_ SG_ 949 VC_BU_CMP_CAL_CSO "Backup for Compass calibration customer settings menu";
CM_ SG_ 949 VC_BU_CMP_VAR_CSO "Backup for Compass variance customer settings menu";
CM_ SG_ 949 VC_BU_CONS_CSO "Backup for Consumption unit customer settings menu";
CM_ SG_ 949 VC_BU_DISTANCE_CSO "Backup for Distance unit customer settings menu";
CM_ SG_ 949 VC_BU_DR_LK_CSO "Backup for Auto door lock customer settings menu";
CM_ SG_ 949 VC_BU_DR_UNLK_CSO "Backup for Auto door unlock customer settings menu";
CM_ SG_ 949 VC_BU_DRL_CSO "Backup for Daytime running lights customer settings menu";
CM_ SG_ 949 VC_BU_EASY_EXIT_CSO "Backup for Easy exit seat customer settings menu";
CM_ SG_ 949 VC_BU_ENTRY_EXIT_CSO "Backup for Auto entry exit mode customer settings menu";
CM_ SG_ 949 VC_BU_EPB_SERV_CSO "Backup for EPB service mode customer settings menu";
CM_ SG_ 949 VC_BU_FLSH_LMP_LK_CSO "Backup for Flash lamps with lock customer settings menu";
CM_ SG_ 949 VC_BU_HL_DRP_CSO "Backup for Headlamp drop customer settings menu";
CM_ SG_ 949 VC_BU_HL_OFF_DLY_CSO "Backup for Headlamp off delay customer settings menu";
CM_ SG_ 949 VC_BU_HL_WPR_CSO "Backup for Headlamps on with wiper customer settings menu";
CM_ SG_ 949 VC_BU_HSA_CSO "Backup for Hill start assist customer settings menu";
CM_ SG_ 949 VC_BU_ILL_APPRCH_CSO "Backup for Illuminated approach customer settings menu";
CM_ SG_ 949 VC_BU_LDW_TRQ_CSO "Backup for Lane departure torque customer settings menu";
CM_ SG_ 949 VC_BU_LDW_WRN_CSO "Backup for Lane departure warning customer settings menu";
CM_ SG_ 949 VC_BU_LGHT_RMT_LWR_CSO "Backup for Flash lights with remote lower customer settings menu";
CM_ SG_ 949 VC_BU_NAV_TRN_CSO "Backup for Nav turn by turn customer settings menu";
CM_ SG_ 949 VC_BU_PE_CSO "Backup for Passive entry customer settings menu";
CM_ SG_ 949 VC_BU_PER_SHFT_ENBL_CSO "Backup for Performance shift enable customer settings menu";
CM_ SG_ 949 VC_BU_PER_SHFT_RPM_CSO "Backup for Performance shift rpm customer settings menu";
CM_ SG_ 949 VC_BU_PLG_CHM_CSO "Backup for Power liftgate chime customer settings menu";
CM_ SG_ 949 VC_BU_POWER_CSO "Backup for Power unit customer settings menu";
CM_ SG_ 949 VC_BU_PRESSURE_CSO "Backup for Pressure unit customer settings menu";
CM_ SG_ 949 VC_BU_PTO_CSO "Backup for Power take off customer settings menu";
CM_ SG_ 949 VC_BU_RAIN_WPR_CSO "Backup for Rain sensitive wipers customer settings menu";
CM_ SG_ 949 VC_BU_REAR_CMRA_CSO "Backup for Rear camera customer settings menu";
CM_ SG_ 950 VC_BU_HOLD_N_GO_CSO "Backup for Hold and go customer setting menu: Present = 1";
CM_ SG_ 950 VC_BU_PADDLE_SHIFT_CSO "Backup for paddle shifter customer setting menu present.  Present = [1]";
CM_ SG_ 950 VC_BU_FLSH_LMP_SLDR_CSO "Backup for flash lamps with sliding door customer settings menu; Present = [1]";
CM_ SG_ 950 VC_BU_SPEED_WARNING_CSO "Backup for Speed warning  customer setting";
CM_ SG_ 950 VC_BU_LDW_ON_CSO "Backup for LDW on/off customer setting menu present.  Present = 1.";
CM_ SG_ 950 VC_BU_PRK_ASST_TYPE_CSO "Backup for Park assist type customer setting menu present. Present = 1.";
CM_ SG_ 950 VC_BU_EPB_ON_CSO "Backup for EPB on/off customer setting menu present. Present = 1.";
CM_ SG_ 950 VC_BU_AIRBAG_ON_CSO "Backup for Passenger airbag on/off customer setting menu present. Present = 1.";
CM_ SG_ 950 VC_BU_FCW_SW_CSO "Backup for FCW Switch customer setting menu present.  Present = 1";
CM_ SG_ 950 VC_BU_FCW_WARN_BRK_CSO "Backup for FCW single setting (warning and brake) customer setting menu.  Present = 1";
CM_ SG_ 950 VC_BU_DOORS_OFF_ACC_DLY_CSO "Backup for Doors & engine off power delay customer settings menu backup. Present = 1";
CM_ SG_ 950 VC_BU_TEEN_PRK_ASST_BRK_CSO "Backup teen key park assist brake customer settings menu.  Present = 1";
CM_ SG_ 950 VC_BU_PWR_FLD_MRR_CSO "Backup for Power folding mirror customer setting menu: Present = 1";
CM_ SG_ 950 VC_BU_HANDS_FREE_LFT_CSO "Backup for Hands free liftgate customer setting menu: Present = 1";
CM_ SG_ 950 VC_BU_HANDS_FREE_SLDR_CSO "Backup for Hands free sliding door customer setting menu: Present = 1";
CM_ SG_ 950 VC_BU_SVC_GRIDLINES_CSO "Backup for Surround view camera gridlines customer setting menu: Present = 1";
CM_ SG_ 950 VC_BU_SVC_DELAY_CSO "Backup for Surround view camera delay customer setting menu: Present = 1";
CM_ SG_ 950 VC_BU_SLD_DR_ALRT_CSO "Backup for Sliding door alert customer setting menu: Present = 1";
CM_ SG_ 950 VC_BU_TEEN_FCW_SENS_CSO "Backup for Teen key FCW sensitivity customer setting menu: Present = 1";
CM_ SG_ 950 VC_BU_TEEN_FCW_BRK_CSO "Backup for Teen key FCW braking customer setting menu: Present = 1";
CM_ SG_ 950 VC_BU_TEEN_PRK_ASST_CSO "Backup for Teen key park assist customer setting menu: Present = 1";
CM_ SG_ 950 VC_BU_TEEN_FT_PRK_VOL_CSO "Backup for Teen key front park assist chime volume customer setting menu: Present = 1";
CM_ SG_ 950 VC_BU_TEEN_RR_PRK_VOL_CSO "Backup for Teen key rear park assist chime volume customer setting menu: Present = 1";
CM_ SG_ 950 VC_BU_TEEN_MAX_SPEED_CSO "Backup for Teen key max speed customer setting menu: Present = 1";
CM_ SG_ 950 VC_BU_TEEN_FUEL_WRN_CSO "Backup for Teen key early fuel warning customer setting menu: Present = 1";
CM_ SG_ 950 VC_BU_TEEN_FUEL_POPUP_CSO "Backup for Teen key fuel pop-up customer setting menu: Present = 1";
CM_ SG_ 950 VC_BU_TEEN_BLIND_SPOT_CSO "Backup for Teen key blind spot customer setting menu: Present = 1";
CM_ SG_ 950 VC_BU_TEEN_RAIN_WPR_CSO "Backup for Teen key rain sensitive wiper customer setting menu: Present = 1";
CM_ SG_ 950 VC_BU_TEEN_AUTO_HB_CSO "Backup for Teen key automatic highbeam customer setting menu: Present = 1";
CM_ SG_ 950 VC_BU_TEEN_LGHT_WPR_CSO "Backup for Teen key lights on with wipers customer setting menu: Present = 1";
CM_ SG_ 950 VC_BU_TEEN_SLD_DR_ALRT_CSO "Backup for Teen key sliding door alert customer setting menu: Present = 1";
CM_ SG_ 950 VC_BU_TEEN_PLG_CHIME_CSO "Backup for Teen key power lift gate chime customer setting menu: Present = 1";
CM_ SG_ 950 VC_BU_SLD_DR_CHM_CSO "Backup for Sliding door chime customer setting menu present: Present = 1";
CM_ SG_ 950 VC_BU_TEEN_SLD_DR_CHM_CSO "Backup for Teen key sliding door chime customer setting menu present: Present = 1";
CM_ SG_ 950 VC_BU_PCS_CSO "Backup for Auto on passenger comfort customer settings menu. Present = 1";
CM_ SG_ 950 VC_BU_BSM_TRLR_CSO "Backup for Blind spot with trailer customer settings menu. Present = 1.";
CM_ SG_ 950 VC_BU_AUTO_SS_CSO "Backup for Automatic side step customer settings menu. Present = 1";
CM_ SG_ 950 VC_BU_RDY_DRV_CSO "Backup for disable ready to drive popup customer settings menu.  Present = 1";
CM_ SG_ 950 VC_BU_VehCfgCSO2_Stat "Backup for Configuration message CSO2 status";
CM_ SG_ 950 VC_BU_REAR_CMRA_DLY_CSO "Backup for Rear view camera delay customer settings menu";
CM_ SG_ 950 VC_BU_RKE_MEM_CSO "Backup for RKE linked to memory customer settings menu";
CM_ SG_ 950 VC_BU_RKE_UNLK_CSO "Backup for RKE unlock customer settings menu";
CM_ SG_ 950 VC_BU_SPEED_CSO "Backup for Speed unit customer settings menu";
CM_ SG_ 950 VC_BU_TLT_MRR_CSO "Backup for Tilt mirror in reverse customer settings menu";
CM_ SG_ 950 VC_BU_TORQUE_CSO "Backup for Torque unit customer settings menu";
CM_ SG_ 950 VC_BU_TRLR_CSO "Backup for Trailer selected customer settings menu";
CM_ SG_ 950 VC_BU_TRLR_NAME_CSO "Backup for Trailer name customer settings menu";
CM_ SG_ 950 VC_BU_TRLR_TYPE_CSO "Backup for Trailer type customer settings menu";
CM_ SG_ 950 VC_BU_TRNS_MD_CSO "Backup for Transport mode customer settings menu";
CM_ SG_ 950 VC_BU_US_METRIC_CSO "Backup for US metric customer settings menu";
CM_ SG_ 950 VC_BU_WHL_ALGN_CSO "Backup for Wheel alignment customer settings menu";
CM_ SG_ 950 VC_BU_FUEL_SAV_CSO "Backup for Fuel Saver settings menu; Present = [1]";
CM_ SG_ 950 VC_BU_TEMP_CSO "Backup for Temperature Unit settings menu; Present = [1]";
BA_DEF_ BO_  "App-Botschaft" ENUM  "nein","ja";
BA_DEF_ BO_  "CanMsgMinLen" INT 0 8;
BA_DEF_ BO_  "DiagRequest" ENUM  "nein","ja";
BA_DEF_ BO_  "DiagResponse" ENUM  "nein","ja";
BA_DEF_ BO_  "DiagState" ENUM  "nein","ja";
BA_DEF_ BO_  "GenMsgCycleTime" INT 0 65535;
BA_DEF_ BO_  "GenMsgCycleTimeActive" INT 0 65535;
BA_DEF_ BO_  "GenMsgDelayTime" INT 0 65535;
BA_DEF_ BO_  "GenMsgNrOfRepetitions" INT 0 65535;
BA_DEF_ BO_  "GenMsgSendType" ENUM  "cyclicX","spontanX","cyclicIfActiveX","spontanWithDelay","cyclicAndSpontanX","cyclicAndSpontanWithDelay","spontanWithRepitition","cyclicIfActiveAndSpontanWD","cyclicIfActiveFast","cyclicWithRepeatOnDemand","none";
BA_DEF_ BO_  "GenMsgStartDelayTime" INT 0 65535;
BA_DEF_ BO_  "GenMsgStartValue" STRING ;
BA_DEF_ BO_  "NWM-Botschaft" ENUM  "nein","ja";
BA_DEF_ BO_  "TpTxIndex" INT 0 99;
BA_DEF_ SG_  "FlexKomComment" STRING ;
BA_DEF_ SG_  "FlexKomIsMotorola" ENUM  "nein","ja";
BA_DEF_ SG_  "FlexKomSID" INT 0 2147483647;
BA_DEF_ SG_  "FlexKomSigLaenge" INT 0 64;
BA_DEF_ SG_  "FlexKomSigName" STRING ;
BA_DEF_ SG_  "FlexKomSigStartPos" INT 0 63;
BA_DEF_ SG_  "FlexKomSigStartValue" STRING ;
BA_DEF_ SG_  "GenSigCycleTime" INT 0 65535;
BA_DEF_ SG_  "GenSigCycleTimeActive" INT 0 65535;
BA_DEF_ SG_  "GenSigSendType" ENUM  "cyclicX","spontanX","cyclicIfActiveX","spontanWithDelay","cyclicAndSpontanX","cyclicAndSpontanWithDelay","spontanWithRepitition","cyclicIfActiveAndSpontanWD","cyclicIfActiveFast","cyclicWithRepeatOnDemand","none";
BA_DEF_ SG_  "GenSigSNA" STRING ;
BA_DEF_ SG_  "GenSigStartValue" HEX 0 2147483648;
BA_DEF_ SG_  "GenSigTimeout_AHLM" INT 0 65535;
BA_DEF_ SG_  "GenSigTimeout_ASBS" INT 0 65535;
BA_DEF_ SG_  "GenSigTimeout_CBC" INT 0 65535;
BA_DEF_ SG_  "GenSigTimeout_DPDM" INT 0 65535;
BA_DEF_ SG_  "GenSigTimeout_DTCM" INT 0 65535;
BA_DEF_ SG_  "GenSigTimeout_EHPS" INT 0 65535;
BA_DEF_ SG_  "GenSigTimeout_ESC" INT 0 65535;
BA_DEF_ SG_  "GenSigTimeout_ESL" INT 0 65535;
BA_DEF_ SG_  "GenSigTimeout_ESM" INT 0 65535;
BA_DEF_ SG_  "GenSigTimeout_ETM" INT 0 65535;
BA_DEF_ SG_  "GenSigTimeout_IC" INT 0 65535;
BA_DEF_ SG_  "GenSigTimeout_OCM" INT 0 65535;
BA_DEF_ SG_  "GenSigTimeout_ORC" INT 0 65535;
BA_DEF_ SG_  "GenSigTimeout_PTS" INT 0 65535;
BA_DEF_ SG_  "GenSigTimeout_RF_HUB" INT 0 65535;
BA_DEF_ SG_  "GenSigTimeout_SCCM" INT 0 65535;
BA_DEF_ SG_  "GenSigTimeout_TBM" INT 0 65535;
BA_DEF_ SG_  "GenSigTimeout_TCM" INT 0 65535;
BA_DEF_ SG_  "GenSigTimeout_TPM" INT 0 65535;
BA_DEF_ SG_  "RID" STRING ;
BA_DEF_ SG_  "SystemSignalLongSymbol" STRING ;
BA_DEF_DEF_  "App-Botschaft" "nein";
BA_DEF_DEF_  "CanMsgMinLen" 0;
BA_DEF_DEF_  "DiagRequest" "nein";
BA_DEF_DEF_  "DiagResponse" "nein";
BA_DEF_DEF_  "DiagState" "nein";
BA_DEF_DEF_  "GenMsgCycleTime" 0;
BA_DEF_DEF_  "GenMsgCycleTimeActive" 0;
BA_DEF_DEF_  "GenMsgDelayTime" 0;
BA_DEF_DEF_  "GenMsgNrOfRepetitions" 0;
BA_DEF_DEF_  "GenMsgSendType" "cyclicX";
BA_DEF_DEF_  "GenMsgStartDelayTime" 0;
BA_DEF_DEF_  "GenMsgStartValue" "";
BA_DEF_DEF_  "NWM-Botschaft" "nein";
BA_DEF_DEF_  "TpTxIndex" 0;
BA_DEF_DEF_  "FlexKomComment" "";
BA_DEF_DEF_  "FlexKomIsMotorola" "nein";
BA_DEF_DEF_  "FlexKomSID" 0;
BA_DEF_DEF_  "FlexKomSigLaenge" 0;
BA_DEF_DEF_  "FlexKomSigName" "";
BA_DEF_DEF_  "FlexKomSigStartPos" 0;
BA_DEF_DEF_  "FlexKomSigStartValue" "";
BA_DEF_DEF_  "GenSigCycleTime" 0;
BA_DEF_DEF_  "GenSigCycleTimeActive" 0;
BA_DEF_DEF_  "GenSigSendType" "cyclicX";
BA_DEF_DEF_  "GenSigSNA" "";
BA_DEF_DEF_  "GenSigStartValue" 0;
BA_DEF_DEF_  "GenSigTimeout_AHLM" 0;
BA_DEF_DEF_  "GenSigTimeout_ASBS" 0;
BA_DEF_DEF_  "GenSigTimeout_CBC" 0;
BA_DEF_DEF_  "GenSigTimeout_DPDM" 0;
BA_DEF_DEF_  "GenSigTimeout_DTCM" 0;
BA_DEF_DEF_  "GenSigTimeout_EHPS" 0;
BA_DEF_DEF_  "GenSigTimeout_ESC" 0;
BA_DEF_DEF_  "GenSigTimeout_ESL" 0;
BA_DEF_DEF_  "GenSigTimeout_ESM" 0;
BA_DEF_DEF_  "GenSigTimeout_ETM" 0;
BA_DEF_DEF_  "GenSigTimeout_IC" 0;
BA_DEF_DEF_  "GenSigTimeout_OCM" 0;
BA_DEF_DEF_  "GenSigTimeout_ORC" 0;
BA_DEF_DEF_  "GenSigTimeout_PTS" 0;
BA_DEF_DEF_  "GenSigTimeout_RF_HUB" 0;
BA_DEF_DEF_  "GenSigTimeout_SCCM" 0;
BA_DEF_DEF_  "GenSigTimeout_TBM" 0;
BA_DEF_DEF_  "GenSigTimeout_TCM" 0;
BA_DEF_DEF_  "GenSigTimeout_TPM" 0;
BA_DEF_DEF_  "RID" "";
BA_DEF_DEF_  "SystemSignalLongSymbol" "";
BA_ "GenMsgStartValue" BO_ 941 "0000000000000000h";
BA_ "GenMsgStartDelayTime" BO_ 941 150;
BA_ "GenMsgNrOfRepetitions" BO_ 941 2;
BA_ "GenMsgDelayTime" BO_ 941 20;
BA_ "GenMsgCycleTime" BO_ 941 1000;
BA_ "GenMsgStartValue" BO_ 942 "0000000000000000h";
BA_ "GenMsgStartDelayTime" BO_ 942 200;
BA_ "GenMsgNrOfRepetitions" BO_ 942 2;
BA_ "GenMsgDelayTime" BO_ 942 20;
BA_ "GenMsgCycleTime" BO_ 942 1000;
BA_ "GenMsgStartValue" BO_ 943 "0000000000000000h";
BA_ "GenMsgStartDelayTime" BO_ 943 250;
BA_ "GenMsgNrOfRepetitions" BO_ 943 2;
BA_ "GenMsgDelayTime" BO_ 943 20;
BA_ "GenMsgCycleTime" BO_ 943 1000;
BA_ "GenMsgStartValue" BO_ 944 "0000000000000000h";
BA_ "GenMsgSendType" BO_ 944 1;
BA_ "GenMsgNrOfRepetitions" BO_ 944 2;
BA_ "GenMsgDelayTime" BO_ 944 20;
BA_ "GenMsgStartValue" BO_ 945 "0000000000000000h";
BA_ "GenMsgSendType" BO_ 945 1;
BA_ "GenMsgNrOfRepetitions" BO_ 945 2;
BA_ "GenMsgDelayTime" BO_ 945 20;
BA_ "GenMsgStartValue" BO_ 946 "0000000000000000h";
BA_ "GenMsgSendType" BO_ 946 1;
BA_ "GenMsgNrOfRepetitions" BO_ 946 2;
BA_ "GenMsgDelayTime" BO_ 946 20;
BA_ "GenMsgStartValue" BO_ 947 "0300000000000000h";
BA_ "GenMsgStartDelayTime" BO_ 947 60;
BA_ "GenMsgSendType" BO_ 947 5;
BA_ "GenMsgNrOfRepetitions" BO_ 947 2;
BA_ "GenMsgDelayTime" BO_ 947 20;
BA_ "GenMsgCycleTime" BO_ 947 2000;
BA_ "GenMsgStartValue" BO_ 948 "0300000000000000h";
BA_ "GenMsgStartDelayTime" BO_ 948 70;
BA_ "GenMsgSendType" BO_ 948 5;
BA_ "GenMsgNrOfRepetitions" BO_ 948 2;
BA_ "GenMsgDelayTime" BO_ 948 20;
BA_ "GenMsgCycleTime" BO_ 948 2000;
BA_ "GenMsgStartValue" BO_ 949 "0300000000000000h";
BA_ "GenMsgSendType" BO_ 949 1;
BA_ "GenMsgNrOfRepetitions" BO_ 949 2;
BA_ "GenMsgDelayTime" BO_ 949 20;
BA_ "GenMsgStartValue" BO_ 950 "0300000000000000h";
BA_ "GenMsgSendType" BO_ 950 1;
BA_ "GenMsgNrOfRepetitions" BO_ 950 2;
BA_ "GenMsgDelayTime" BO_ 950 20;
BA_ "GenSigTimeout_ETM" SG_ 941 B_MPG 10500;
BA_ "GenSigSNA" SG_ 941 B_MPG "3FFh";
BA_ "GenSigCycleTime" SG_ 941 B_MPG 1000;
BA_ "FlexKomSigStartValue" SG_ 941 B_MPG "0000000000000000h";
BA_ "FlexKomSigStartPos" SG_ 941 B_MPG 7;
BA_ "FlexKomSigName" SG_ 941 B_MPG "IC_TripData_Pkt_4";
BA_ "FlexKomSigLaenge" SG_ 941 B_MPG 64;
BA_ "FlexKomSID" SG_ 941 B_MPG 2582;
BA_ "FlexKomIsMotorola" SG_ 941 B_MPG 1;
BA_ "FlexKomComment" SG_ 941 B_MPG "IC Trip data packet 4";
BA_ "GenSigTimeout_ETM" SG_ 941 B_EV_Miles 10500;
BA_ "GenSigSNA" SG_ 941 B_EV_Miles "FFFFFFh";
BA_ "GenSigCycleTime" SG_ 941 B_EV_Miles 1000;
BA_ "FlexKomSigStartValue" SG_ 941 B_EV_Miles "0000000000000000h";
BA_ "FlexKomSigStartPos" SG_ 941 B_EV_Miles 7;
BA_ "FlexKomSigName" SG_ 941 B_EV_Miles "IC_TripData_Pkt_4";
BA_ "FlexKomSigLaenge" SG_ 941 B_EV_Miles 64;
BA_ "FlexKomSID" SG_ 941 B_EV_Miles 2582;
BA_ "FlexKomIsMotorola" SG_ 941 B_EV_Miles 1;
BA_ "FlexKomComment" SG_ 941 B_EV_Miles "IC Trip data packet 4";
BA_ "GenSigTimeout_ETM" SG_ 941 B_EV_Kilometers 10500;
BA_ "GenSigSNA" SG_ 941 B_EV_Kilometers "FFFFFFh";
BA_ "GenSigCycleTime" SG_ 941 B_EV_Kilometers 1000;
BA_ "FlexKomSigStartValue" SG_ 941 B_EV_Kilometers "0000000000000000h";
BA_ "FlexKomSigStartPos" SG_ 941 B_EV_Kilometers 7;
BA_ "FlexKomSigName" SG_ 941 B_EV_Kilometers "IC_TripData_Pkt_4";
BA_ "FlexKomSigLaenge" SG_ 941 B_EV_Kilometers 64;
BA_ "FlexKomSID" SG_ 941 B_EV_Kilometers 2582;
BA_ "FlexKomIsMotorola" SG_ 941 B_EV_Kilometers 1;
BA_ "FlexKomComment" SG_ 941 B_EV_Kilometers "IC Trip data packet 4";
BA_ "GenSigTimeout_ETM" SG_ 942 B_KMpL 10500;
BA_ "GenSigSNA" SG_ 942 B_KMpL "3FFh";
BA_ "GenSigCycleTime" SG_ 942 B_KMpL 1000;
BA_ "FlexKomSigStartValue" SG_ 942 B_KMpL "0000000000000000h";
BA_ "FlexKomSigStartPos" SG_ 942 B_KMpL 7;
BA_ "FlexKomSigName" SG_ 942 B_KMpL "IC_TripData_Pkt_5";
BA_ "FlexKomSigLaenge" SG_ 942 B_KMpL 64;
BA_ "FlexKomSID" SG_ 942 B_KMpL 2581;
BA_ "FlexKomIsMotorola" SG_ 942 B_KMpL 1;
BA_ "FlexKomComment" SG_ 942 B_KMpL "IC Trip data packet 5";
BA_ "GenSigTimeout_ETM" SG_ 942 B_Hybrid_Miles 10500;
BA_ "GenSigSNA" SG_ 942 B_Hybrid_Miles "FFFFFFh";
BA_ "GenSigCycleTime" SG_ 942 B_Hybrid_Miles 1000;
BA_ "FlexKomSigStartValue" SG_ 942 B_Hybrid_Miles "0000000000000000h";
BA_ "FlexKomSigStartPos" SG_ 942 B_Hybrid_Miles 7;
BA_ "FlexKomSigName" SG_ 942 B_Hybrid_Miles "IC_TripData_Pkt_5";
BA_ "FlexKomSigLaenge" SG_ 942 B_Hybrid_Miles 64;
BA_ "FlexKomSID" SG_ 942 B_Hybrid_Miles 2581;
BA_ "FlexKomIsMotorola" SG_ 942 B_Hybrid_Miles 1;
BA_ "FlexKomComment" SG_ 942 B_Hybrid_Miles "IC Trip data packet 5";
BA_ "GenSigTimeout_ETM" SG_ 942 B_Hybrid_Kilometers 10500;
BA_ "GenSigSNA" SG_ 942 B_Hybrid_Kilometers "FFFFFFh";
BA_ "GenSigCycleTime" SG_ 942 B_Hybrid_Kilometers 1000;
BA_ "FlexKomSigStartValue" SG_ 942 B_Hybrid_Kilometers "0000000000000000h";
BA_ "FlexKomSigStartPos" SG_ 942 B_Hybrid_Kilometers 7;
BA_ "FlexKomSigName" SG_ 942 B_Hybrid_Kilometers "IC_TripData_Pkt_5";
BA_ "FlexKomSigLaenge" SG_ 942 B_Hybrid_Kilometers 64;
BA_ "FlexKomSID" SG_ 942 B_Hybrid_Kilometers 2581;
BA_ "FlexKomIsMotorola" SG_ 942 B_Hybrid_Kilometers 1;
BA_ "FlexKomComment" SG_ 942 B_Hybrid_Kilometers "IC Trip data packet 5";
BA_ "GenSigTimeout_ETM" SG_ 943 B_Total_Dist_Miles 10500;
BA_ "GenSigSNA" SG_ 943 B_Total_Dist_Miles "FFFFFFh";
BA_ "GenSigCycleTime" SG_ 943 B_Total_Dist_Miles 1000;
BA_ "FlexKomSigStartValue" SG_ 943 B_Total_Dist_Miles "0000000000000000h";
BA_ "FlexKomSigStartPos" SG_ 943 B_Total_Dist_Miles 7;
BA_ "FlexKomSigName" SG_ 943 B_Total_Dist_Miles "IC_TripData_Pkt_6";
BA_ "FlexKomSigLaenge" SG_ 943 B_Total_Dist_Miles 64;
BA_ "FlexKomSID" SG_ 943 B_Total_Dist_Miles 2580;
BA_ "FlexKomIsMotorola" SG_ 943 B_Total_Dist_Miles 1;
BA_ "FlexKomComment" SG_ 943 B_Total_Dist_Miles "IC Trip data packet 6";
BA_ "GenSigTimeout_ETM" SG_ 943 B_Total_Dist_Kilometers 10500;
BA_ "GenSigSNA" SG_ 943 B_Total_Dist_Kilometers "FFFFFFh";
BA_ "GenSigCycleTime" SG_ 943 B_Total_Dist_Kilometers 1000;
BA_ "FlexKomSigStartValue" SG_ 943 B_Total_Dist_Kilometers "0000000000000000h";
BA_ "FlexKomSigStartPos" SG_ 943 B_Total_Dist_Kilometers 7;
BA_ "FlexKomSigName" SG_ 943 B_Total_Dist_Kilometers "IC_TripData_Pkt_6";
BA_ "FlexKomSigLaenge" SG_ 943 B_Total_Dist_Kilometers 64;
BA_ "FlexKomSID" SG_ 943 B_Total_Dist_Kilometers 2580;
BA_ "FlexKomIsMotorola" SG_ 943 B_Total_Dist_Kilometers 1;
BA_ "FlexKomComment" SG_ 943 B_Total_Dist_Kilometers "IC Trip data packet 6";
BA_ "GenSigSNA" SG_ 944 TCM_APPL2 "0h";
BA_ "GenSigSendType" SG_ 944 TCM_APPL2 1;
BA_ "FlexKomSigStartValue" SG_ 944 TCM_APPL2 "0000000000000000h";
BA_ "FlexKomSigStartPos" SG_ 944 TCM_APPL2 7;
BA_ "FlexKomSigName" SG_ 944 TCM_APPL2 "TCM_APPL2";
BA_ "FlexKomSigLaenge" SG_ 944 TCM_APPL2 64;
BA_ "FlexKomSID" SG_ 944 TCM_APPL2 1178;
BA_ "FlexKomIsMotorola" SG_ 944 TCM_APPL2 1;
BA_ "FlexKomComment" SG_ 944 TCM_APPL2 "CCP to transmission";
BA_ "GenSigSNA" SG_ 945 TCM_APPL1 "0h";
BA_ "GenSigSendType" SG_ 945 TCM_APPL1 1;
BA_ "FlexKomSigStartValue" SG_ 945 TCM_APPL1 "0000000000000000h";
BA_ "FlexKomSigStartPos" SG_ 945 TCM_APPL1 7;
BA_ "FlexKomSigName" SG_ 945 TCM_APPL1 "TCM_APPL1";
BA_ "FlexKomSigLaenge" SG_ 945 TCM_APPL1 64;
BA_ "FlexKomSID" SG_ 945 TCM_APPL1 778;
BA_ "FlexKomIsMotorola" SG_ 945 TCM_APPL1 1;
BA_ "FlexKomComment" SG_ 945 TCM_APPL1 "CCP from transmission";
BA_ "GenSigSNA" SG_ 946 TCM_APPL3 "0h";
BA_ "GenSigSendType" SG_ 946 TCM_APPL3 1;
BA_ "FlexKomSigStartValue" SG_ 946 TCM_APPL3 "0000000000000000h";
BA_ "FlexKomSigStartPos" SG_ 946 TCM_APPL3 7;
BA_ "FlexKomSigName" SG_ 946 TCM_APPL3 "TCM_APPL3";
BA_ "FlexKomSigLaenge" SG_ 946 TCM_APPL3 64;
BA_ "FlexKomSID" SG_ 946 TCM_APPL3 1179;
BA_ "FlexKomIsMotorola" SG_ 946 TCM_APPL3 1;
BA_ "FlexKomComment" SG_ 946 TCM_APPL3 "CCP from transmission";
BA_ "GenSigTimeout_IC" SG_ 947 VC_PRK_AST_CSO 21000;
BA_ "GenSigSNA" SG_ 947 VC_PRK_AST_CSO "0h";
BA_ "GenSigSendType" SG_ 947 VC_PRK_AST_CSO 5;
BA_ "GenSigCycleTime" SG_ 947 VC_PRK_AST_CSO 2000;
BA_ "FlexKomSigStartValue" SG_ 947 VC_PRK_AST_CSO "0300000000000000h";
BA_ "FlexKomSigStartPos" SG_ 947 VC_PRK_AST_CSO 7;
BA_ "FlexKomSigName" SG_ 947 VC_PRK_AST_CSO "VehCfgCSM1_Pkt";
BA_ "FlexKomSigLaenge" SG_ 947 VC_PRK_AST_CSO 64;
BA_ "FlexKomSID" SG_ 947 VC_PRK_AST_CSO 2006;
BA_ "FlexKomIsMotorola" SG_ 947 VC_PRK_AST_CSO 1;
BA_ "FlexKomComment" SG_ 947 VC_PRK_AST_CSO "Vehicle configuration - customer settings menu 1 P";
BA_ "GenSigTimeout_IC" SG_ 947 VC_PRK_AST_BRK_CSO 21000;
BA_ "GenSigSNA" SG_ 947 VC_PRK_AST_BRK_CSO "0h";
BA_ "GenSigSendType" SG_ 947 VC_PRK_AST_BRK_CSO 5;
BA_ "GenSigCycleTime" SG_ 947 VC_PRK_AST_BRK_CSO 2000;
BA_ "FlexKomSigStartValue" SG_ 947 VC_PRK_AST_BRK_CSO "0300000000000000h";
BA_ "FlexKomSigStartPos" SG_ 947 VC_PRK_AST_BRK_CSO 7;
BA_ "FlexKomSigName" SG_ 947 VC_PRK_AST_BRK_CSO "VehCfgCSM1_Pkt";
BA_ "FlexKomSigLaenge" SG_ 947 VC_PRK_AST_BRK_CSO 64;
BA_ "FlexKomSID" SG_ 947 VC_PRK_AST_BRK_CSO 2006;
BA_ "FlexKomIsMotorola" SG_ 947 VC_PRK_AST_BRK_CSO 1;
BA_ "FlexKomComment" SG_ 947 VC_PRK_AST_BRK_CSO "Vehicle configuration - customer settings menu 1 P";
BA_ "GenSigTimeout_IC" SG_ 947 VC_PRK_FT_VOL_CSO 21000;
BA_ "GenSigSNA" SG_ 947 VC_PRK_FT_VOL_CSO "0h";
BA_ "GenSigSendType" SG_ 947 VC_PRK_FT_VOL_CSO 5;
BA_ "GenSigCycleTime" SG_ 947 VC_PRK_FT_VOL_CSO 2000;
BA_ "FlexKomSigStartValue" SG_ 947 VC_PRK_FT_VOL_CSO "0300000000000000h";
BA_ "FlexKomSigStartPos" SG_ 947 VC_PRK_FT_VOL_CSO 7;
BA_ "FlexKomSigName" SG_ 947 VC_PRK_FT_VOL_CSO "VehCfgCSM1_Pkt";
BA_ "FlexKomSigLaenge" SG_ 947 VC_PRK_FT_VOL_CSO 64;
BA_ "FlexKomSID" SG_ 947 VC_PRK_FT_VOL_CSO 2006;
BA_ "FlexKomIsMotorola" SG_ 947 VC_PRK_FT_VOL_CSO 1;
BA_ "FlexKomComment" SG_ 947 VC_PRK_FT_VOL_CSO "Vehicle configuration - customer settings menu 1 P";
BA_ "GenSigTimeout_IC" SG_ 947 VC_PRK_RR_VOL_CSO 21000;
BA_ "GenSigSNA" SG_ 947 VC_PRK_RR_VOL_CSO "0h";
BA_ "GenSigSendType" SG_ 947 VC_PRK_RR_VOL_CSO 5;
BA_ "GenSigCycleTime" SG_ 947 VC_PRK_RR_VOL_CSO 2000;
BA_ "FlexKomSigStartValue" SG_ 947 VC_PRK_RR_VOL_CSO "0300000000000000h";
BA_ "FlexKomSigStartPos" SG_ 947 VC_PRK_RR_VOL_CSO 7;
BA_ "FlexKomSigName" SG_ 947 VC_PRK_RR_VOL_CSO "VehCfgCSM1_Pkt";
BA_ "FlexKomSigLaenge" SG_ 947 VC_PRK_RR_VOL_CSO 64;
BA_ "FlexKomSID" SG_ 947 VC_PRK_RR_VOL_CSO 2006;
BA_ "FlexKomIsMotorola" SG_ 947 VC_PRK_RR_VOL_CSO 1;
BA_ "FlexKomComment" SG_ 947 VC_PRK_RR_VOL_CSO "Vehicle configuration - customer settings menu 1 P";
BA_ "GenSigTimeout_IC" SG_ 947 VC_EPS_CSO 21000;
BA_ "GenSigSNA" SG_ 947 VC_EPS_CSO "0h";
BA_ "GenSigSendType" SG_ 947 VC_EPS_CSO 5;
BA_ "GenSigCycleTime" SG_ 947 VC_EPS_CSO 2000;
BA_ "FlexKomSigStartValue" SG_ 947 VC_EPS_CSO "0300000000000000h";
BA_ "FlexKomSigStartPos" SG_ 947 VC_EPS_CSO 7;
BA_ "FlexKomSigName" SG_ 947 VC_EPS_CSO "VehCfgCSM1_Pkt";
BA_ "FlexKomSigLaenge" SG_ 947 VC_EPS_CSO 64;
BA_ "FlexKomSID" SG_ 947 VC_EPS_CSO 2006;
BA_ "FlexKomIsMotorola" SG_ 947 VC_EPS_CSO 1;
BA_ "FlexKomComment" SG_ 947 VC_EPS_CSO "Vehicle configuration - customer settings menu 1 P";
BA_ "GenSigTimeout_IC" SG_ 947 VC_FCW_CSO 21000;
BA_ "GenSigSNA" SG_ 947 VC_FCW_CSO "0h";
BA_ "GenSigSendType" SG_ 947 VC_FCW_CSO 5;
BA_ "GenSigCycleTime" SG_ 947 VC_FCW_CSO 2000;
BA_ "FlexKomSigStartValue" SG_ 947 VC_FCW_CSO "0300000000000000h";
BA_ "FlexKomSigStartPos" SG_ 947 VC_FCW_CSO 7;
BA_ "FlexKomSigName" SG_ 947 VC_FCW_CSO "VehCfgCSM1_Pkt";
BA_ "FlexKomSigLaenge" SG_ 947 VC_FCW_CSO 64;
BA_ "FlexKomSID" SG_ 947 VC_FCW_CSO 2006;
BA_ "FlexKomIsMotorola" SG_ 947 VC_FCW_CSO 1;
BA_ "FlexKomComment" SG_ 947 VC_FCW_CSO "Vehicle configuration - customer settings menu 1 P";
BA_ "GenSigTimeout_IC" SG_ 947 VC_FCW_BRK_CSO 21000;
BA_ "GenSigSNA" SG_ 947 VC_FCW_BRK_CSO "0h";
BA_ "GenSigSendType" SG_ 947 VC_FCW_BRK_CSO 5;
BA_ "GenSigCycleTime" SG_ 947 VC_FCW_BRK_CSO 2000;
BA_ "FlexKomSigStartValue" SG_ 947 VC_FCW_BRK_CSO "0300000000000000h";
BA_ "FlexKomSigStartPos" SG_ 947 VC_FCW_BRK_CSO 7;
BA_ "FlexKomSigName" SG_ 947 VC_FCW_BRK_CSO "VehCfgCSM1_Pkt";
BA_ "FlexKomSigLaenge" SG_ 947 VC_FCW_BRK_CSO 64;
BA_ "FlexKomSID" SG_ 947 VC_FCW_BRK_CSO 2006;
BA_ "FlexKomIsMotorola" SG_ 947 VC_FCW_BRK_CSO 1;
BA_ "FlexKomComment" SG_ 947 VC_FCW_BRK_CSO "Vehicle configuration - customer settings menu 1 P";
BA_ "GenSigTimeout_IC" SG_ 947 VC_HRN_RMT_LK_CSO 21000;
BA_ "GenSigSNA" SG_ 947 VC_HRN_RMT_LK_CSO "0h";
BA_ "GenSigSendType" SG_ 947 VC_HRN_RMT_LK_CSO 5;
BA_ "GenSigCycleTime" SG_ 947 VC_HRN_RMT_LK_CSO 2000;
BA_ "FlexKomSigStartValue" SG_ 947 VC_HRN_RMT_LK_CSO "0300000000000000h";
BA_ "FlexKomSigStartPos" SG_ 947 VC_HRN_RMT_LK_CSO 7;
BA_ "FlexKomSigName" SG_ 947 VC_HRN_RMT_LK_CSO "VehCfgCSM1_Pkt";
BA_ "FlexKomSigLaenge" SG_ 947 VC_HRN_RMT_LK_CSO 64;
BA_ "FlexKomSID" SG_ 947 VC_HRN_RMT_LK_CSO 2006;
BA_ "FlexKomIsMotorola" SG_ 947 VC_HRN_RMT_LK_CSO 1;
BA_ "FlexKomComment" SG_ 947 VC_HRN_RMT_LK_CSO "Vehicle configuration - customer settings menu 1 P";
BA_ "GenSigTimeout_IC" SG_ 947 VC_HRN_RMT_ST_CSO 21000;
BA_ "GenSigSNA" SG_ 947 VC_HRN_RMT_ST_CSO "0h";
BA_ "GenSigSendType" SG_ 947 VC_HRN_RMT_ST_CSO 5;
BA_ "GenSigCycleTime" SG_ 947 VC_HRN_RMT_ST_CSO 2000;
BA_ "FlexKomSigStartValue" SG_ 947 VC_HRN_RMT_ST_CSO "0300000000000000h";
BA_ "FlexKomSigStartPos" SG_ 947 VC_HRN_RMT_ST_CSO 7;
BA_ "FlexKomSigName" SG_ 947 VC_HRN_RMT_ST_CSO "VehCfgCSM1_Pkt";
BA_ "FlexKomSigLaenge" SG_ 947 VC_HRN_RMT_ST_CSO 64;
BA_ "FlexKomSID" SG_ 947 VC_HRN_RMT_ST_CSO 2006;
BA_ "FlexKomIsMotorola" SG_ 947 VC_HRN_RMT_ST_CSO 1;
BA_ "FlexKomComment" SG_ 947 VC_HRN_RMT_ST_CSO "Vehicle configuration - customer settings menu 1 P";
BA_ "GenSigTimeout_IC" SG_ 947 VC_HRN_RMT_LWR_CSO 21000;
BA_ "GenSigSNA" SG_ 947 VC_HRN_RMT_LWR_CSO "0h";
BA_ "GenSigSendType" SG_ 947 VC_HRN_RMT_LWR_CSO 5;
BA_ "GenSigCycleTime" SG_ 947 VC_HRN_RMT_LWR_CSO 2000;
BA_ "FlexKomSigStartValue" SG_ 947 VC_HRN_RMT_LWR_CSO "0300000000000000h";
BA_ "FlexKomSigStartPos" SG_ 947 VC_HRN_RMT_LWR_CSO 7;
BA_ "FlexKomSigName" SG_ 947 VC_HRN_RMT_LWR_CSO "VehCfgCSM1_Pkt";
BA_ "FlexKomSigLaenge" SG_ 947 VC_HRN_RMT_LWR_CSO 64;
BA_ "FlexKomSID" SG_ 947 VC_HRN_RMT_LWR_CSO 2006;
BA_ "FlexKomIsMotorola" SG_ 947 VC_HRN_RMT_LWR_CSO 1;
BA_ "FlexKomComment" SG_ 947 VC_HRN_RMT_LWR_CSO "Vehicle configuration - customer settings menu 1 P";
BA_ "GenSigTimeout_IC" SG_ 947 VC_CHMSL_LINE_CSO 21000;
BA_ "GenSigSNA" SG_ 947 VC_CHMSL_LINE_CSO "0h";
BA_ "GenSigSendType" SG_ 947 VC_CHMSL_LINE_CSO 5;
BA_ "GenSigCycleTime" SG_ 947 VC_CHMSL_LINE_CSO 2000;
BA_ "FlexKomSigStartValue" SG_ 947 VC_CHMSL_LINE_CSO "0300000000000000h";
BA_ "FlexKomSigStartPos" SG_ 947 VC_CHMSL_LINE_CSO 7;
BA_ "FlexKomSigName" SG_ 947 VC_CHMSL_LINE_CSO "VehCfgCSM1_Pkt";
BA_ "FlexKomSigLaenge" SG_ 947 VC_CHMSL_LINE_CSO 64;
BA_ "FlexKomSID" SG_ 947 VC_CHMSL_LINE_CSO 2006;
BA_ "FlexKomIsMotorola" SG_ 947 VC_CHMSL_LINE_CSO 1;
BA_ "FlexKomComment" SG_ 947 VC_CHMSL_LINE_CSO "Vehicle configuration - customer settings menu 1 P";
BA_ "GenSigTimeout_IC" SG_ 947 VC_DCS_CSO 21000;
BA_ "GenSigSNA" SG_ 947 VC_DCS_CSO "0h";
BA_ "GenSigSendType" SG_ 947 VC_DCS_CSO 5;
BA_ "GenSigCycleTime" SG_ 947 VC_DCS_CSO 2000;
BA_ "FlexKomSigStartValue" SG_ 947 VC_DCS_CSO "0300000000000000h";
BA_ "FlexKomSigStartPos" SG_ 947 VC_DCS_CSO 7;
BA_ "FlexKomSigName" SG_ 947 VC_DCS_CSO "VehCfgCSM1_Pkt";
BA_ "FlexKomSigLaenge" SG_ 947 VC_DCS_CSO 64;
BA_ "FlexKomSID" SG_ 947 VC_DCS_CSO 2006;
BA_ "FlexKomIsMotorola" SG_ 947 VC_DCS_CSO 1;
BA_ "FlexKomComment" SG_ 947 VC_DCS_CSO "Vehicle configuration - customer settings menu 1 P";
BA_ "GenSigTimeout_IC" SG_ 947 VC_AUX_SWS_CSO 21000;
BA_ "GenSigSNA" SG_ 947 VC_AUX_SWS_CSO "0h";
BA_ "GenSigSendType" SG_ 947 VC_AUX_SWS_CSO 5;
BA_ "GenSigCycleTime" SG_ 947 VC_AUX_SWS_CSO 2000;
BA_ "FlexKomSigStartValue" SG_ 947 VC_AUX_SWS_CSO "0300000000000000h";
BA_ "FlexKomSigStartPos" SG_ 947 VC_AUX_SWS_CSO 7;
BA_ "FlexKomSigName" SG_ 947 VC_AUX_SWS_CSO "VehCfgCSM1_Pkt";
BA_ "FlexKomSigLaenge" SG_ 947 VC_AUX_SWS_CSO 64;
BA_ "FlexKomSID" SG_ 947 VC_AUX_SWS_CSO 2006;
BA_ "FlexKomIsMotorola" SG_ 947 VC_AUX_SWS_CSO 1;
BA_ "FlexKomComment" SG_ 947 VC_AUX_SWS_CSO "Vehicle configuration - customer settings menu 1 P";
BA_ "GenSigTimeout_IC" SG_ 947 VC_CMRA_GRDLNS_CSO 21000;
BA_ "GenSigSNA" SG_ 947 VC_CMRA_GRDLNS_CSO "0h";
BA_ "GenSigSendType" SG_ 947 VC_CMRA_GRDLNS_CSO 5;
BA_ "GenSigCycleTime" SG_ 947 VC_CMRA_GRDLNS_CSO 2000;
BA_ "FlexKomSigStartValue" SG_ 947 VC_CMRA_GRDLNS_CSO "0300000000000000h";
BA_ "FlexKomSigStartPos" SG_ 947 VC_CMRA_GRDLNS_CSO 7;
BA_ "FlexKomSigName" SG_ 947 VC_CMRA_GRDLNS_CSO "VehCfgCSM1_Pkt";
BA_ "FlexKomSigLaenge" SG_ 947 VC_CMRA_GRDLNS_CSO 64;
BA_ "FlexKomSID" SG_ 947 VC_CMRA_GRDLNS_CSO 2006;
BA_ "FlexKomIsMotorola" SG_ 947 VC_CMRA_GRDLNS_CSO 1;
BA_ "FlexKomComment" SG_ 947 VC_CMRA_GRDLNS_CSO "Vehicle configuration - customer settings menu 1 P";
BA_ "GenSigSNA" SG_ 947 VC_UNIT_SET_CSO "0h";
BA_ "GenSigSendType" SG_ 947 VC_UNIT_SET_CSO 5;
BA_ "GenSigCycleTime" SG_ 947 VC_UNIT_SET_CSO 2000;
BA_ "FlexKomSigStartValue" SG_ 947 VC_UNIT_SET_CSO "0300000000000000h";
BA_ "FlexKomSigStartPos" SG_ 947 VC_UNIT_SET_CSO 7;
BA_ "FlexKomSigName" SG_ 947 VC_UNIT_SET_CSO "VehCfgCSM1_Pkt";
BA_ "FlexKomSigLaenge" SG_ 947 VC_UNIT_SET_CSO 64;
BA_ "FlexKomSID" SG_ 947 VC_UNIT_SET_CSO 2006;
BA_ "FlexKomIsMotorola" SG_ 947 VC_UNIT_SET_CSO 1;
BA_ "FlexKomComment" SG_ 947 VC_UNIT_SET_CSO "Vehicle configuration - customer settings menu 1 P";
BA_ "GenSigTimeout_IC" SG_ 947 VC_POLICE_PE_CSO 21000;
BA_ "GenSigSNA" SG_ 947 VC_POLICE_PE_CSO "0h";
BA_ "GenSigSendType" SG_ 947 VC_POLICE_PE_CSO 5;
BA_ "GenSigCycleTime" SG_ 947 VC_POLICE_PE_CSO 2000;
BA_ "FlexKomSigStartValue" SG_ 947 VC_POLICE_PE_CSO "0300000000000000h";
BA_ "FlexKomSigStartPos" SG_ 947 VC_POLICE_PE_CSO 7;
BA_ "FlexKomSigName" SG_ 947 VC_POLICE_PE_CSO "VehCfgCSM1_Pkt";
BA_ "FlexKomSigLaenge" SG_ 947 VC_POLICE_PE_CSO 64;
BA_ "FlexKomSID" SG_ 947 VC_POLICE_PE_CSO 2006;
BA_ "FlexKomIsMotorola" SG_ 947 VC_POLICE_PE_CSO 1;
BA_ "FlexKomComment" SG_ 947 VC_POLICE_PE_CSO "Vehicle configuration - customer settings menu 1 P";
BA_ "GenSigTimeout_IC" SG_ 947 VC_ACC_DLY_CSO 21000;
BA_ "GenSigSNA" SG_ 947 VC_ACC_DLY_CSO "0h";
BA_ "GenSigSendType" SG_ 947 VC_ACC_DLY_CSO 5;
BA_ "GenSigCycleTime" SG_ 947 VC_ACC_DLY_CSO 2000;
BA_ "FlexKomSigStartValue" SG_ 947 VC_ACC_DLY_CSO "0300000000000000h";
BA_ "FlexKomSigStartPos" SG_ 947 VC_ACC_DLY_CSO 7;
BA_ "FlexKomSigName" SG_ 947 VC_ACC_DLY_CSO "VehCfgCSM1_Pkt";
BA_ "FlexKomSigLaenge" SG_ 947 VC_ACC_DLY_CSO 64;
BA_ "FlexKomSID" SG_ 947 VC_ACC_DLY_CSO 2006;
BA_ "FlexKomIsMotorola" SG_ 947 VC_ACC_DLY_CSO 1;
BA_ "FlexKomComment" SG_ 947 VC_ACC_DLY_CSO "Vehicle configuration - customer settings menu 1 P";
BA_ "GenSigTimeout_IC" SG_ 947 VC_AFLS_CSO 21000;
BA_ "GenSigSNA" SG_ 947 VC_AFLS_CSO "0h";
BA_ "GenSigSendType" SG_ 947 VC_AFLS_CSO 5;
BA_ "GenSigCycleTime" SG_ 947 VC_AFLS_CSO 2000;
BA_ "FlexKomSigStartValue" SG_ 947 VC_AFLS_CSO "0300000000000000h";
BA_ "FlexKomSigStartPos" SG_ 947 VC_AFLS_CSO 7;
BA_ "FlexKomSigName" SG_ 947 VC_AFLS_CSO "VehCfgCSM1_Pkt";
BA_ "FlexKomSigLaenge" SG_ 947 VC_AFLS_CSO 64;
BA_ "FlexKomSID" SG_ 947 VC_AFLS_CSO 2006;
BA_ "FlexKomIsMotorola" SG_ 947 VC_AFLS_CSO 1;
BA_ "FlexKomComment" SG_ 947 VC_AFLS_CSO "Vehicle configuration - customer settings menu 1 P";
BA_ "GenSigTimeout_IC" SG_ 947 VC_AMB_DMR_CSO 21000;
BA_ "GenSigSNA" SG_ 947 VC_AMB_DMR_CSO "0h";
BA_ "GenSigSendType" SG_ 947 VC_AMB_DMR_CSO 5;
BA_ "GenSigCycleTime" SG_ 947 VC_AMB_DMR_CSO 2000;
BA_ "FlexKomSigStartValue" SG_ 947 VC_AMB_DMR_CSO "0300000000000000h";
BA_ "FlexKomSigStartPos" SG_ 947 VC_AMB_DMR_CSO 7;
BA_ "FlexKomSigName" SG_ 947 VC_AMB_DMR_CSO "VehCfgCSM1_Pkt";
BA_ "FlexKomSigLaenge" SG_ 947 VC_AMB_DMR_CSO 64;
BA_ "FlexKomSID" SG_ 947 VC_AMB_DMR_CSO 2006;
BA_ "FlexKomIsMotorola" SG_ 947 VC_AMB_DMR_CSO 1;
BA_ "FlexKomComment" SG_ 947 VC_AMB_DMR_CSO "Vehicle configuration - customer settings menu 1 P";
BA_ "GenSigTimeout_IC" SG_ 947 VC_ASCM_TJ_CSO 21000;
BA_ "GenSigSNA" SG_ 947 VC_ASCM_TJ_CSO "0h";
BA_ "GenSigSendType" SG_ 947 VC_ASCM_TJ_CSO 5;
BA_ "GenSigCycleTime" SG_ 947 VC_ASCM_TJ_CSO 2000;
BA_ "FlexKomSigStartValue" SG_ 947 VC_ASCM_TJ_CSO "0300000000000000h";
BA_ "FlexKomSigStartPos" SG_ 947 VC_ASCM_TJ_CSO 7;
BA_ "FlexKomSigName" SG_ 947 VC_ASCM_TJ_CSO "VehCfgCSM1_Pkt";
BA_ "FlexKomSigLaenge" SG_ 947 VC_ASCM_TJ_CSO 64;
BA_ "FlexKomSID" SG_ 947 VC_ASCM_TJ_CSO 2006;
BA_ "FlexKomIsMotorola" SG_ 947 VC_ASCM_TJ_CSO 1;
BA_ "FlexKomComment" SG_ 947 VC_ASCM_TJ_CSO "Vehicle configuration - customer settings menu 1 P";
BA_ "GenSigTimeout_IC" SG_ 947 VC_ASCM_WRN_CSO 21000;
BA_ "GenSigSNA" SG_ 947 VC_ASCM_WRN_CSO "0h";
BA_ "GenSigSendType" SG_ 947 VC_ASCM_WRN_CSO 5;
BA_ "GenSigCycleTime" SG_ 947 VC_ASCM_WRN_CSO 2000;
BA_ "FlexKomSigStartValue" SG_ 947 VC_ASCM_WRN_CSO "0300000000000000h";
BA_ "FlexKomSigStartPos" SG_ 947 VC_ASCM_WRN_CSO 7;
BA_ "FlexKomSigName" SG_ 947 VC_ASCM_WRN_CSO "VehCfgCSM1_Pkt";
BA_ "FlexKomSigLaenge" SG_ 947 VC_ASCM_WRN_CSO 64;
BA_ "FlexKomSID" SG_ 947 VC_ASCM_WRN_CSO 2006;
BA_ "FlexKomIsMotorola" SG_ 947 VC_ASCM_WRN_CSO 1;
BA_ "FlexKomComment" SG_ 947 VC_ASCM_WRN_CSO "Vehicle configuration - customer settings menu 1 P";
BA_ "GenSigTimeout_IC" SG_ 947 VC_AUTO_AERO_CSO 21000;
BA_ "GenSigSNA" SG_ 947 VC_AUTO_AERO_CSO "0h";
BA_ "GenSigSendType" SG_ 947 VC_AUTO_AERO_CSO 5;
BA_ "GenSigCycleTime" SG_ 947 VC_AUTO_AERO_CSO 2000;
BA_ "FlexKomSigStartValue" SG_ 947 VC_AUTO_AERO_CSO "0300000000000000h";
BA_ "FlexKomSigStartPos" SG_ 947 VC_AUTO_AERO_CSO 7;
BA_ "FlexKomSigName" SG_ 947 VC_AUTO_AERO_CSO "VehCfgCSM1_Pkt";
BA_ "FlexKomSigLaenge" SG_ 947 VC_AUTO_AERO_CSO 64;
BA_ "FlexKomSID" SG_ 947 VC_AUTO_AERO_CSO 2006;
BA_ "FlexKomIsMotorola" SG_ 947 VC_AUTO_AERO_CSO 1;
BA_ "FlexKomComment" SG_ 947 VC_AUTO_AERO_CSO "Vehicle configuration - customer settings menu 1 P";
BA_ "GenSigTimeout_IC" SG_ 947 VC_AUTO_HB_CSO 21000;
BA_ "GenSigSNA" SG_ 947 VC_AUTO_HB_CSO "0h";
BA_ "GenSigSendType" SG_ 947 VC_AUTO_HB_CSO 5;
BA_ "GenSigCycleTime" SG_ 947 VC_AUTO_HB_CSO 2000;
BA_ "FlexKomSigStartValue" SG_ 947 VC_AUTO_HB_CSO "0300000000000000h";
BA_ "FlexKomSigStartPos" SG_ 947 VC_AUTO_HB_CSO 7;
BA_ "FlexKomSigName" SG_ 947 VC_AUTO_HB_CSO "VehCfgCSM1_Pkt";
BA_ "FlexKomSigLaenge" SG_ 947 VC_AUTO_HB_CSO 64;
BA_ "FlexKomSID" SG_ 947 VC_AUTO_HB_CSO 2006;
BA_ "FlexKomIsMotorola" SG_ 947 VC_AUTO_HB_CSO 1;
BA_ "FlexKomComment" SG_ 947 VC_AUTO_HB_CSO "Vehicle configuration - customer settings menu 1 P";
BA_ "GenSigTimeout_IC" SG_ 947 VC_AUTO_PRK_CSO 21000;
BA_ "GenSigSNA" SG_ 947 VC_AUTO_PRK_CSO "0h";
BA_ "GenSigSendType" SG_ 947 VC_AUTO_PRK_CSO 5;
BA_ "GenSigCycleTime" SG_ 947 VC_AUTO_PRK_CSO 2000;
BA_ "FlexKomSigStartValue" SG_ 947 VC_AUTO_PRK_CSO "0300000000000000h";
BA_ "FlexKomSigStartPos" SG_ 947 VC_AUTO_PRK_CSO 7;
BA_ "FlexKomSigName" SG_ 947 VC_AUTO_PRK_CSO "VehCfgCSM1_Pkt";
BA_ "FlexKomSigLaenge" SG_ 947 VC_AUTO_PRK_CSO 64;
BA_ "FlexKomSID" SG_ 947 VC_AUTO_PRK_CSO 2006;
BA_ "FlexKomIsMotorola" SG_ 947 VC_AUTO_PRK_CSO 1;
BA_ "FlexKomComment" SG_ 947 VC_AUTO_PRK_CSO "Vehicle configuration - customer settings menu 1 P";
BA_ "GenSigTimeout_IC" SG_ 947 VC_BLIND_SPOT_CSO 21000;
BA_ "GenSigSNA" SG_ 947 VC_BLIND_SPOT_CSO "0h";
BA_ "GenSigSendType" SG_ 947 VC_BLIND_SPOT_CSO 5;
BA_ "GenSigCycleTime" SG_ 947 VC_BLIND_SPOT_CSO 2000;
BA_ "FlexKomSigStartValue" SG_ 947 VC_BLIND_SPOT_CSO "0300000000000000h";
BA_ "FlexKomSigStartPos" SG_ 947 VC_BLIND_SPOT_CSO 7;
BA_ "FlexKomSigName" SG_ 947 VC_BLIND_SPOT_CSO "VehCfgCSM1_Pkt";
BA_ "FlexKomSigLaenge" SG_ 947 VC_BLIND_SPOT_CSO 64;
BA_ "FlexKomSID" SG_ 947 VC_BLIND_SPOT_CSO 2006;
BA_ "FlexKomIsMotorola" SG_ 947 VC_BLIND_SPOT_CSO 1;
BA_ "FlexKomComment" SG_ 947 VC_BLIND_SPOT_CSO "Vehicle configuration - customer settings menu 1 P";
BA_ "GenSigTimeout_IC" SG_ 947 VC_CAPACITY_CSO 21000;
BA_ "GenSigSNA" SG_ 947 VC_CAPACITY_CSO "0h";
BA_ "GenSigSendType" SG_ 947 VC_CAPACITY_CSO 5;
BA_ "GenSigCycleTime" SG_ 947 VC_CAPACITY_CSO 2000;
BA_ "FlexKomSigStartValue" SG_ 947 VC_CAPACITY_CSO "0300000000000000h";
BA_ "FlexKomSigStartPos" SG_ 947 VC_CAPACITY_CSO 7;
BA_ "FlexKomSigName" SG_ 947 VC_CAPACITY_CSO "VehCfgCSM1_Pkt";
BA_ "FlexKomSigLaenge" SG_ 947 VC_CAPACITY_CSO 64;
BA_ "FlexKomSID" SG_ 947 VC_CAPACITY_CSO 2006;
BA_ "FlexKomIsMotorola" SG_ 947 VC_CAPACITY_CSO 1;
BA_ "FlexKomComment" SG_ 947 VC_CAPACITY_CSO "Vehicle configuration - customer settings menu 1 P";
BA_ "GenSigTimeout_IC" SG_ 947 VC_CLK_DSP_CSO 21000;
BA_ "GenSigSNA" SG_ 947 VC_CLK_DSP_CSO "0h";
BA_ "GenSigSendType" SG_ 947 VC_CLK_DSP_CSO 5;
BA_ "GenSigCycleTime" SG_ 947 VC_CLK_DSP_CSO 2000;
BA_ "FlexKomSigStartValue" SG_ 947 VC_CLK_DSP_CSO "0300000000000000h";
BA_ "FlexKomSigStartPos" SG_ 947 VC_CLK_DSP_CSO 7;
BA_ "FlexKomSigName" SG_ 947 VC_CLK_DSP_CSO "VehCfgCSM1_Pkt";
BA_ "FlexKomSigLaenge" SG_ 947 VC_CLK_DSP_CSO 64;
BA_ "FlexKomSID" SG_ 947 VC_CLK_DSP_CSO 2006;
BA_ "FlexKomIsMotorola" SG_ 947 VC_CLK_DSP_CSO 1;
BA_ "FlexKomComment" SG_ 947 VC_CLK_DSP_CSO "Vehicle configuration - customer settings menu 1 P";
BA_ "GenSigTimeout_IC" SG_ 947 VC_CMP_CAL_CSO 21000;
BA_ "GenSigSNA" SG_ 947 VC_CMP_CAL_CSO "0h";
BA_ "GenSigSendType" SG_ 947 VC_CMP_CAL_CSO 5;
BA_ "GenSigCycleTime" SG_ 947 VC_CMP_CAL_CSO 2000;
BA_ "FlexKomSigStartValue" SG_ 947 VC_CMP_CAL_CSO "0300000000000000h";
BA_ "FlexKomSigStartPos" SG_ 947 VC_CMP_CAL_CSO 7;
BA_ "FlexKomSigName" SG_ 947 VC_CMP_CAL_CSO "VehCfgCSM1_Pkt";
BA_ "FlexKomSigLaenge" SG_ 947 VC_CMP_CAL_CSO 64;
BA_ "FlexKomSID" SG_ 947 VC_CMP_CAL_CSO 2006;
BA_ "FlexKomIsMotorola" SG_ 947 VC_CMP_CAL_CSO 1;
BA_ "FlexKomComment" SG_ 947 VC_CMP_CAL_CSO "Vehicle configuration - customer settings menu 1 P";
BA_ "GenSigTimeout_IC" SG_ 947 VC_CMP_VAR_CSO 21000;
BA_ "GenSigSNA" SG_ 947 VC_CMP_VAR_CSO "0h";
BA_ "GenSigSendType" SG_ 947 VC_CMP_VAR_CSO 5;
BA_ "GenSigCycleTime" SG_ 947 VC_CMP_VAR_CSO 2000;
BA_ "FlexKomSigStartValue" SG_ 947 VC_CMP_VAR_CSO "0300000000000000h";
BA_ "FlexKomSigStartPos" SG_ 947 VC_CMP_VAR_CSO 7;
BA_ "FlexKomSigName" SG_ 947 VC_CMP_VAR_CSO "VehCfgCSM1_Pkt";
BA_ "FlexKomSigLaenge" SG_ 947 VC_CMP_VAR_CSO 64;
BA_ "FlexKomSID" SG_ 947 VC_CMP_VAR_CSO 2006;
BA_ "FlexKomIsMotorola" SG_ 947 VC_CMP_VAR_CSO 1;
BA_ "FlexKomComment" SG_ 947 VC_CMP_VAR_CSO "Vehicle configuration - customer settings menu 1 P";
BA_ "GenSigTimeout_IC" SG_ 947 VC_CONS_CSO 21000;
BA_ "GenSigSNA" SG_ 947 VC_CONS_CSO "0h";
BA_ "GenSigSendType" SG_ 947 VC_CONS_CSO 5;
BA_ "GenSigCycleTime" SG_ 947 VC_CONS_CSO 2000;
BA_ "FlexKomSigStartValue" SG_ 947 VC_CONS_CSO "0300000000000000h";
BA_ "FlexKomSigStartPos" SG_ 947 VC_CONS_CSO 7;
BA_ "FlexKomSigName" SG_ 947 VC_CONS_CSO "VehCfgCSM1_Pkt";
BA_ "FlexKomSigLaenge" SG_ 947 VC_CONS_CSO 64;
BA_ "FlexKomSID" SG_ 947 VC_CONS_CSO 2006;
BA_ "FlexKomIsMotorola" SG_ 947 VC_CONS_CSO 1;
BA_ "FlexKomComment" SG_ 947 VC_CONS_CSO "Vehicle configuration - customer settings menu 1 P";
BA_ "GenSigTimeout_IC" SG_ 947 VC_DISTANCE_CSO 21000;
BA_ "GenSigSNA" SG_ 947 VC_DISTANCE_CSO "0h";
BA_ "GenSigSendType" SG_ 947 VC_DISTANCE_CSO 5;
BA_ "GenSigCycleTime" SG_ 947 VC_DISTANCE_CSO 2000;
BA_ "FlexKomSigStartValue" SG_ 947 VC_DISTANCE_CSO "0300000000000000h";
BA_ "FlexKomSigStartPos" SG_ 947 VC_DISTANCE_CSO 7;
BA_ "FlexKomSigName" SG_ 947 VC_DISTANCE_CSO "VehCfgCSM1_Pkt";
BA_ "FlexKomSigLaenge" SG_ 947 VC_DISTANCE_CSO 64;
BA_ "FlexKomSID" SG_ 947 VC_DISTANCE_CSO 2006;
BA_ "FlexKomIsMotorola" SG_ 947 VC_DISTANCE_CSO 1;
BA_ "FlexKomComment" SG_ 947 VC_DISTANCE_CSO "Vehicle configuration - customer settings menu 1 P";
BA_ "GenSigTimeout_IC" SG_ 947 VC_DR_LK_CSO 21000;
BA_ "GenSigSNA" SG_ 947 VC_DR_LK_CSO "0h";
BA_ "GenSigSendType" SG_ 947 VC_DR_LK_CSO 5;
BA_ "GenSigCycleTime" SG_ 947 VC_DR_LK_CSO 2000;
BA_ "FlexKomSigStartValue" SG_ 947 VC_DR_LK_CSO "0300000000000000h";
BA_ "FlexKomSigStartPos" SG_ 947 VC_DR_LK_CSO 7;
BA_ "FlexKomSigName" SG_ 947 VC_DR_LK_CSO "VehCfgCSM1_Pkt";
BA_ "FlexKomSigLaenge" SG_ 947 VC_DR_LK_CSO 64;
BA_ "FlexKomSID" SG_ 947 VC_DR_LK_CSO 2006;
BA_ "FlexKomIsMotorola" SG_ 947 VC_DR_LK_CSO 1;
BA_ "FlexKomComment" SG_ 947 VC_DR_LK_CSO "Vehicle configuration - customer settings menu 1 P";
BA_ "GenSigTimeout_IC" SG_ 947 VC_DR_UNLK_CSO 21000;
BA_ "GenSigSNA" SG_ 947 VC_DR_UNLK_CSO "0h";
BA_ "GenSigSendType" SG_ 947 VC_DR_UNLK_CSO 5;
BA_ "GenSigCycleTime" SG_ 947 VC_DR_UNLK_CSO 2000;
BA_ "FlexKomSigStartValue" SG_ 947 VC_DR_UNLK_CSO "0300000000000000h";
BA_ "FlexKomSigStartPos" SG_ 947 VC_DR_UNLK_CSO 7;
BA_ "FlexKomSigName" SG_ 947 VC_DR_UNLK_CSO "VehCfgCSM1_Pkt";
BA_ "FlexKomSigLaenge" SG_ 947 VC_DR_UNLK_CSO 64;
BA_ "FlexKomSID" SG_ 947 VC_DR_UNLK_CSO 2006;
BA_ "FlexKomIsMotorola" SG_ 947 VC_DR_UNLK_CSO 1;
BA_ "FlexKomComment" SG_ 947 VC_DR_UNLK_CSO "Vehicle configuration - customer settings menu 1 P";
BA_ "GenSigTimeout_IC" SG_ 947 VC_DRL_CSO 21000;
BA_ "GenSigSNA" SG_ 947 VC_DRL_CSO "0h";
BA_ "GenSigSendType" SG_ 947 VC_DRL_CSO 5;
BA_ "GenSigCycleTime" SG_ 947 VC_DRL_CSO 2000;
BA_ "FlexKomSigStartValue" SG_ 947 VC_DRL_CSO "0300000000000000h";
BA_ "FlexKomSigStartPos" SG_ 947 VC_DRL_CSO 7;
BA_ "FlexKomSigName" SG_ 947 VC_DRL_CSO "VehCfgCSM1_Pkt";
BA_ "FlexKomSigLaenge" SG_ 947 VC_DRL_CSO 64;
BA_ "FlexKomSID" SG_ 947 VC_DRL_CSO 2006;
BA_ "FlexKomIsMotorola" SG_ 947 VC_DRL_CSO 1;
BA_ "FlexKomComment" SG_ 947 VC_DRL_CSO "Vehicle configuration - customer settings menu 1 P";
BA_ "GenSigTimeout_IC" SG_ 947 VC_EASY_EXIT_CSO 21000;
BA_ "GenSigSNA" SG_ 947 VC_EASY_EXIT_CSO "0h";
BA_ "GenSigSendType" SG_ 947 VC_EASY_EXIT_CSO 5;
BA_ "GenSigCycleTime" SG_ 947 VC_EASY_EXIT_CSO 2000;
BA_ "FlexKomSigStartValue" SG_ 947 VC_EASY_EXIT_CSO "0300000000000000h";
BA_ "FlexKomSigStartPos" SG_ 947 VC_EASY_EXIT_CSO 7;
BA_ "FlexKomSigName" SG_ 947 VC_EASY_EXIT_CSO "VehCfgCSM1_Pkt";
BA_ "FlexKomSigLaenge" SG_ 947 VC_EASY_EXIT_CSO 64;
BA_ "FlexKomSID" SG_ 947 VC_EASY_EXIT_CSO 2006;
BA_ "FlexKomIsMotorola" SG_ 947 VC_EASY_EXIT_CSO 1;
BA_ "FlexKomComment" SG_ 947 VC_EASY_EXIT_CSO "Vehicle configuration - customer settings menu 1 P";
BA_ "GenSigTimeout_IC" SG_ 947 VC_ENTRY_EXIT_CSO 21000;
BA_ "GenSigSNA" SG_ 947 VC_ENTRY_EXIT_CSO "0h";
BA_ "GenSigSendType" SG_ 947 VC_ENTRY_EXIT_CSO 5;
BA_ "GenSigCycleTime" SG_ 947 VC_ENTRY_EXIT_CSO 2000;
BA_ "FlexKomSigStartValue" SG_ 947 VC_ENTRY_EXIT_CSO "0300000000000000h";
BA_ "FlexKomSigStartPos" SG_ 947 VC_ENTRY_EXIT_CSO 7;
BA_ "FlexKomSigName" SG_ 947 VC_ENTRY_EXIT_CSO "VehCfgCSM1_Pkt";
BA_ "FlexKomSigLaenge" SG_ 947 VC_ENTRY_EXIT_CSO 64;
BA_ "FlexKomSID" SG_ 947 VC_ENTRY_EXIT_CSO 2006;
BA_ "FlexKomIsMotorola" SG_ 947 VC_ENTRY_EXIT_CSO 1;
BA_ "FlexKomComment" SG_ 947 VC_ENTRY_EXIT_CSO "Vehicle configuration - customer settings menu 1 P";
BA_ "GenSigTimeout_IC" SG_ 947 VC_EPB_SERV_CSO 21000;
BA_ "GenSigSNA" SG_ 947 VC_EPB_SERV_CSO "0h";
BA_ "GenSigSendType" SG_ 947 VC_EPB_SERV_CSO 5;
BA_ "GenSigCycleTime" SG_ 947 VC_EPB_SERV_CSO 2000;
BA_ "FlexKomSigStartValue" SG_ 947 VC_EPB_SERV_CSO "0300000000000000h";
BA_ "FlexKomSigStartPos" SG_ 947 VC_EPB_SERV_CSO 7;
BA_ "FlexKomSigName" SG_ 947 VC_EPB_SERV_CSO "VehCfgCSM1_Pkt";
BA_ "FlexKomSigLaenge" SG_ 947 VC_EPB_SERV_CSO 64;
BA_ "FlexKomSID" SG_ 947 VC_EPB_SERV_CSO 2006;
BA_ "FlexKomIsMotorola" SG_ 947 VC_EPB_SERV_CSO 1;
BA_ "FlexKomComment" SG_ 947 VC_EPB_SERV_CSO "Vehicle configuration - customer settings menu 1 P";
BA_ "GenSigTimeout_IC" SG_ 947 VC_FLSH_LMP_LK_CSO 21000;
BA_ "GenSigSNA" SG_ 947 VC_FLSH_LMP_LK_CSO "0h";
BA_ "GenSigSendType" SG_ 947 VC_FLSH_LMP_LK_CSO 5;
BA_ "GenSigCycleTime" SG_ 947 VC_FLSH_LMP_LK_CSO 2000;
BA_ "FlexKomSigStartValue" SG_ 947 VC_FLSH_LMP_LK_CSO "0300000000000000h";
BA_ "FlexKomSigStartPos" SG_ 947 VC_FLSH_LMP_LK_CSO 7;
BA_ "FlexKomSigName" SG_ 947 VC_FLSH_LMP_LK_CSO "VehCfgCSM1_Pkt";
BA_ "FlexKomSigLaenge" SG_ 947 VC_FLSH_LMP_LK_CSO 64;
BA_ "FlexKomSID" SG_ 947 VC_FLSH_LMP_LK_CSO 2006;
BA_ "FlexKomIsMotorola" SG_ 947 VC_FLSH_LMP_LK_CSO 1;
BA_ "FlexKomComment" SG_ 947 VC_FLSH_LMP_LK_CSO "Vehicle configuration - customer settings menu 1 P";
BA_ "GenSigTimeout_IC" SG_ 947 VC_HL_DRP_CSO 21000;
BA_ "GenSigSNA" SG_ 947 VC_HL_DRP_CSO "0h";
BA_ "GenSigSendType" SG_ 947 VC_HL_DRP_CSO 5;
BA_ "GenSigCycleTime" SG_ 947 VC_HL_DRP_CSO 2000;
BA_ "FlexKomSigStartValue" SG_ 947 VC_HL_DRP_CSO "0300000000000000h";
BA_ "FlexKomSigStartPos" SG_ 947 VC_HL_DRP_CSO 7;
BA_ "FlexKomSigName" SG_ 947 VC_HL_DRP_CSO "VehCfgCSM1_Pkt";
BA_ "FlexKomSigLaenge" SG_ 947 VC_HL_DRP_CSO 64;
BA_ "FlexKomSID" SG_ 947 VC_HL_DRP_CSO 2006;
BA_ "FlexKomIsMotorola" SG_ 947 VC_HL_DRP_CSO 1;
BA_ "FlexKomComment" SG_ 947 VC_HL_DRP_CSO "Vehicle configuration - customer settings menu 1 P";
BA_ "GenSigTimeout_IC" SG_ 947 VC_HL_OFF_DLY_CSO 21000;
BA_ "GenSigSNA" SG_ 947 VC_HL_OFF_DLY_CSO "0h";
BA_ "GenSigSendType" SG_ 947 VC_HL_OFF_DLY_CSO 5;
BA_ "GenSigCycleTime" SG_ 947 VC_HL_OFF_DLY_CSO 2000;
BA_ "FlexKomSigStartValue" SG_ 947 VC_HL_OFF_DLY_CSO "0300000000000000h";
BA_ "FlexKomSigStartPos" SG_ 947 VC_HL_OFF_DLY_CSO 7;
BA_ "FlexKomSigName" SG_ 947 VC_HL_OFF_DLY_CSO "VehCfgCSM1_Pkt";
BA_ "FlexKomSigLaenge" SG_ 947 VC_HL_OFF_DLY_CSO 64;
BA_ "FlexKomSID" SG_ 947 VC_HL_OFF_DLY_CSO 2006;
BA_ "FlexKomIsMotorola" SG_ 947 VC_HL_OFF_DLY_CSO 1;
BA_ "FlexKomComment" SG_ 947 VC_HL_OFF_DLY_CSO "Vehicle configuration - customer settings menu 1 P";
BA_ "GenSigTimeout_IC" SG_ 947 VC_HL_WPR_CSO 21000;
BA_ "GenSigSNA" SG_ 947 VC_HL_WPR_CSO "0h";
BA_ "GenSigSendType" SG_ 947 VC_HL_WPR_CSO 5;
BA_ "GenSigCycleTime" SG_ 947 VC_HL_WPR_CSO 2000;
BA_ "FlexKomSigStartValue" SG_ 947 VC_HL_WPR_CSO "0300000000000000h";
BA_ "FlexKomSigStartPos" SG_ 947 VC_HL_WPR_CSO 7;
BA_ "FlexKomSigName" SG_ 947 VC_HL_WPR_CSO "VehCfgCSM1_Pkt";
BA_ "FlexKomSigLaenge" SG_ 947 VC_HL_WPR_CSO 64;
BA_ "FlexKomSID" SG_ 947 VC_HL_WPR_CSO 2006;
BA_ "FlexKomIsMotorola" SG_ 947 VC_HL_WPR_CSO 1;
BA_ "FlexKomComment" SG_ 947 VC_HL_WPR_CSO "Vehicle configuration - customer settings menu 1 P";
BA_ "GenSigTimeout_IC" SG_ 947 VC_HSA_CSO 21000;
BA_ "GenSigSNA" SG_ 947 VC_HSA_CSO "0h";
BA_ "GenSigSendType" SG_ 947 VC_HSA_CSO 5;
BA_ "GenSigCycleTime" SG_ 947 VC_HSA_CSO 2000;
BA_ "FlexKomSigStartValue" SG_ 947 VC_HSA_CSO "0300000000000000h";
BA_ "FlexKomSigStartPos" SG_ 947 VC_HSA_CSO 7;
BA_ "FlexKomSigName" SG_ 947 VC_HSA_CSO "VehCfgCSM1_Pkt";
BA_ "FlexKomSigLaenge" SG_ 947 VC_HSA_CSO 64;
BA_ "FlexKomSID" SG_ 947 VC_HSA_CSO 2006;
BA_ "FlexKomIsMotorola" SG_ 947 VC_HSA_CSO 1;
BA_ "FlexKomComment" SG_ 947 VC_HSA_CSO "Vehicle configuration - customer settings menu 1 P";
BA_ "GenSigTimeout_IC" SG_ 947 VC_ILL_APPRCH_CSO 21000;
BA_ "GenSigSNA" SG_ 947 VC_ILL_APPRCH_CSO "0h";
BA_ "GenSigSendType" SG_ 947 VC_ILL_APPRCH_CSO 5;
BA_ "GenSigCycleTime" SG_ 947 VC_ILL_APPRCH_CSO 2000;
BA_ "FlexKomSigStartValue" SG_ 947 VC_ILL_APPRCH_CSO "0300000000000000h";
BA_ "FlexKomSigStartPos" SG_ 947 VC_ILL_APPRCH_CSO 7;
BA_ "FlexKomSigName" SG_ 947 VC_ILL_APPRCH_CSO "VehCfgCSM1_Pkt";
BA_ "FlexKomSigLaenge" SG_ 947 VC_ILL_APPRCH_CSO 64;
BA_ "FlexKomSID" SG_ 947 VC_ILL_APPRCH_CSO 2006;
BA_ "FlexKomIsMotorola" SG_ 947 VC_ILL_APPRCH_CSO 1;
BA_ "FlexKomComment" SG_ 947 VC_ILL_APPRCH_CSO "Vehicle configuration - customer settings menu 1 P";
BA_ "GenSigTimeout_IC" SG_ 947 VC_LDW_TRQ_CSO 21000;
BA_ "GenSigSNA" SG_ 947 VC_LDW_TRQ_CSO "0h";
BA_ "GenSigSendType" SG_ 947 VC_LDW_TRQ_CSO 5;
BA_ "GenSigCycleTime" SG_ 947 VC_LDW_TRQ_CSO 2000;
BA_ "FlexKomSigStartValue" SG_ 947 VC_LDW_TRQ_CSO "0300000000000000h";
BA_ "FlexKomSigStartPos" SG_ 947 VC_LDW_TRQ_CSO 7;
BA_ "FlexKomSigName" SG_ 947 VC_LDW_TRQ_CSO "VehCfgCSM1_Pkt";
BA_ "FlexKomSigLaenge" SG_ 947 VC_LDW_TRQ_CSO 64;
BA_ "FlexKomSID" SG_ 947 VC_LDW_TRQ_CSO 2006;
BA_ "FlexKomIsMotorola" SG_ 947 VC_LDW_TRQ_CSO 1;
BA_ "FlexKomComment" SG_ 947 VC_LDW_TRQ_CSO "Vehicle configuration - customer settings menu 1 P";
BA_ "GenSigTimeout_IC" SG_ 947 VC_LDW_WRN_CSO 21000;
BA_ "GenSigSNA" SG_ 947 VC_LDW_WRN_CSO "0h";
BA_ "GenSigSendType" SG_ 947 VC_LDW_WRN_CSO 5;
BA_ "GenSigCycleTime" SG_ 947 VC_LDW_WRN_CSO 2000;
BA_ "FlexKomSigStartValue" SG_ 947 VC_LDW_WRN_CSO "0300000000000000h";
BA_ "FlexKomSigStartPos" SG_ 947 VC_LDW_WRN_CSO 7;
BA_ "FlexKomSigName" SG_ 947 VC_LDW_WRN_CSO "VehCfgCSM1_Pkt";
BA_ "FlexKomSigLaenge" SG_ 947 VC_LDW_WRN_CSO 64;
BA_ "FlexKomSID" SG_ 947 VC_LDW_WRN_CSO 2006;
BA_ "FlexKomIsMotorola" SG_ 947 VC_LDW_WRN_CSO 1;
BA_ "FlexKomComment" SG_ 947 VC_LDW_WRN_CSO "Vehicle configuration - customer settings menu 1 P";
BA_ "GenSigTimeout_IC" SG_ 947 VC_LGHT_RMT_LWR_CSO 21000;
BA_ "GenSigSNA" SG_ 947 VC_LGHT_RMT_LWR_CSO "0h";
BA_ "GenSigSendType" SG_ 947 VC_LGHT_RMT_LWR_CSO 5;
BA_ "GenSigCycleTime" SG_ 947 VC_LGHT_RMT_LWR_CSO 2000;
BA_ "FlexKomSigStartValue" SG_ 947 VC_LGHT_RMT_LWR_CSO "0300000000000000h";
BA_ "FlexKomSigStartPos" SG_ 947 VC_LGHT_RMT_LWR_CSO 7;
BA_ "FlexKomSigName" SG_ 947 VC_LGHT_RMT_LWR_CSO "VehCfgCSM1_Pkt";
BA_ "FlexKomSigLaenge" SG_ 947 VC_LGHT_RMT_LWR_CSO 64;
BA_ "FlexKomSID" SG_ 947 VC_LGHT_RMT_LWR_CSO 2006;
BA_ "FlexKomIsMotorola" SG_ 947 VC_LGHT_RMT_LWR_CSO 1;
BA_ "FlexKomComment" SG_ 947 VC_LGHT_RMT_LWR_CSO "Vehicle configuration - customer settings menu 1 P";
BA_ "GenSigTimeout_IC" SG_ 947 VC_NAV_TRN_CSO 21000;
BA_ "GenSigSNA" SG_ 947 VC_NAV_TRN_CSO "0h";
BA_ "GenSigSendType" SG_ 947 VC_NAV_TRN_CSO 5;
BA_ "GenSigCycleTime" SG_ 947 VC_NAV_TRN_CSO 2000;
BA_ "FlexKomSigStartValue" SG_ 947 VC_NAV_TRN_CSO "0300000000000000h";
BA_ "FlexKomSigStartPos" SG_ 947 VC_NAV_TRN_CSO 7;
BA_ "FlexKomSigName" SG_ 947 VC_NAV_TRN_CSO "VehCfgCSM1_Pkt";
BA_ "FlexKomSigLaenge" SG_ 947 VC_NAV_TRN_CSO 64;
BA_ "FlexKomSID" SG_ 947 VC_NAV_TRN_CSO 2006;
BA_ "FlexKomIsMotorola" SG_ 947 VC_NAV_TRN_CSO 1;
BA_ "FlexKomComment" SG_ 947 VC_NAV_TRN_CSO "Vehicle configuration - customer settings menu 1 P";
BA_ "GenSigTimeout_IC" SG_ 947 VC_PE_CSO 21000;
BA_ "GenSigSNA" SG_ 947 VC_PE_CSO "0h";
BA_ "GenSigSendType" SG_ 947 VC_PE_CSO 5;
BA_ "GenSigCycleTime" SG_ 947 VC_PE_CSO 2000;
BA_ "FlexKomSigStartValue" SG_ 947 VC_PE_CSO "0300000000000000h";
BA_ "FlexKomSigStartPos" SG_ 947 VC_PE_CSO 7;
BA_ "FlexKomSigName" SG_ 947 VC_PE_CSO "VehCfgCSM1_Pkt";
BA_ "FlexKomSigLaenge" SG_ 947 VC_PE_CSO 64;
BA_ "FlexKomSID" SG_ 947 VC_PE_CSO 2006;
BA_ "FlexKomIsMotorola" SG_ 947 VC_PE_CSO 1;
BA_ "FlexKomComment" SG_ 947 VC_PE_CSO "Vehicle configuration - customer settings menu 1 P";
BA_ "GenSigTimeout_IC" SG_ 947 VC_PER_SHFT_ENBL_CSO 21000;
BA_ "GenSigSNA" SG_ 947 VC_PER_SHFT_ENBL_CSO "0h";
BA_ "GenSigSendType" SG_ 947 VC_PER_SHFT_ENBL_CSO 5;
BA_ "GenSigCycleTime" SG_ 947 VC_PER_SHFT_ENBL_CSO 2000;
BA_ "FlexKomSigStartValue" SG_ 947 VC_PER_SHFT_ENBL_CSO "0300000000000000h";
BA_ "FlexKomSigStartPos" SG_ 947 VC_PER_SHFT_ENBL_CSO 7;
BA_ "FlexKomSigName" SG_ 947 VC_PER_SHFT_ENBL_CSO "VehCfgCSM1_Pkt";
BA_ "FlexKomSigLaenge" SG_ 947 VC_PER_SHFT_ENBL_CSO 64;
BA_ "FlexKomSID" SG_ 947 VC_PER_SHFT_ENBL_CSO 2006;
BA_ "FlexKomIsMotorola" SG_ 947 VC_PER_SHFT_ENBL_CSO 1;
BA_ "FlexKomComment" SG_ 947 VC_PER_SHFT_ENBL_CSO "Vehicle configuration - customer settings menu 1 P";
BA_ "GenSigTimeout_IC" SG_ 947 VC_PER_SHFT_RPM_CSO 21000;
BA_ "GenSigSNA" SG_ 947 VC_PER_SHFT_RPM_CSO "0h";
BA_ "GenSigSendType" SG_ 947 VC_PER_SHFT_RPM_CSO 5;
BA_ "GenSigCycleTime" SG_ 947 VC_PER_SHFT_RPM_CSO 2000;
BA_ "FlexKomSigStartValue" SG_ 947 VC_PER_SHFT_RPM_CSO "0300000000000000h";
BA_ "FlexKomSigStartPos" SG_ 947 VC_PER_SHFT_RPM_CSO 7;
BA_ "FlexKomSigName" SG_ 947 VC_PER_SHFT_RPM_CSO "VehCfgCSM1_Pkt";
BA_ "FlexKomSigLaenge" SG_ 947 VC_PER_SHFT_RPM_CSO 64;
BA_ "FlexKomSID" SG_ 947 VC_PER_SHFT_RPM_CSO 2006;
BA_ "FlexKomIsMotorola" SG_ 947 VC_PER_SHFT_RPM_CSO 1;
BA_ "FlexKomComment" SG_ 947 VC_PER_SHFT_RPM_CSO "Vehicle configuration - customer settings menu 1 P";
BA_ "GenSigTimeout_IC" SG_ 947 VC_PLG_CHM_CSO 21000;
BA_ "GenSigSNA" SG_ 947 VC_PLG_CHM_CSO "0h";
BA_ "GenSigSendType" SG_ 947 VC_PLG_CHM_CSO 5;
BA_ "GenSigCycleTime" SG_ 947 VC_PLG_CHM_CSO 2000;
BA_ "FlexKomSigStartValue" SG_ 947 VC_PLG_CHM_CSO "0300000000000000h";
BA_ "FlexKomSigStartPos" SG_ 947 VC_PLG_CHM_CSO 7;
BA_ "FlexKomSigName" SG_ 947 VC_PLG_CHM_CSO "VehCfgCSM1_Pkt";
BA_ "FlexKomSigLaenge" SG_ 947 VC_PLG_CHM_CSO 64;
BA_ "FlexKomSID" SG_ 947 VC_PLG_CHM_CSO 2006;
BA_ "FlexKomIsMotorola" SG_ 947 VC_PLG_CHM_CSO 1;
BA_ "FlexKomComment" SG_ 947 VC_PLG_CHM_CSO "Vehicle configuration - customer settings menu 1 P";
BA_ "GenSigTimeout_IC" SG_ 947 VC_POWER_CSO 21000;
BA_ "GenSigSNA" SG_ 947 VC_POWER_CSO "0h";
BA_ "GenSigSendType" SG_ 947 VC_POWER_CSO 5;
BA_ "GenSigCycleTime" SG_ 947 VC_POWER_CSO 2000;
BA_ "FlexKomSigStartValue" SG_ 947 VC_POWER_CSO "0300000000000000h";
BA_ "FlexKomSigStartPos" SG_ 947 VC_POWER_CSO 7;
BA_ "FlexKomSigName" SG_ 947 VC_POWER_CSO "VehCfgCSM1_Pkt";
BA_ "FlexKomSigLaenge" SG_ 947 VC_POWER_CSO 64;
BA_ "FlexKomSID" SG_ 947 VC_POWER_CSO 2006;
BA_ "FlexKomIsMotorola" SG_ 947 VC_POWER_CSO 1;
BA_ "FlexKomComment" SG_ 947 VC_POWER_CSO "Vehicle configuration - customer settings menu 1 P";
BA_ "GenSigTimeout_IC" SG_ 947 VC_PRESSURE_CSO 21000;
BA_ "GenSigSNA" SG_ 947 VC_PRESSURE_CSO "0h";
BA_ "GenSigSendType" SG_ 947 VC_PRESSURE_CSO 5;
BA_ "GenSigCycleTime" SG_ 947 VC_PRESSURE_CSO 2000;
BA_ "FlexKomSigStartValue" SG_ 947 VC_PRESSURE_CSO "0300000000000000h";
BA_ "FlexKomSigStartPos" SG_ 947 VC_PRESSURE_CSO 7;
BA_ "FlexKomSigName" SG_ 947 VC_PRESSURE_CSO "VehCfgCSM1_Pkt";
BA_ "FlexKomSigLaenge" SG_ 947 VC_PRESSURE_CSO 64;
BA_ "FlexKomSID" SG_ 947 VC_PRESSURE_CSO 2006;
BA_ "FlexKomIsMotorola" SG_ 947 VC_PRESSURE_CSO 1;
BA_ "FlexKomComment" SG_ 947 VC_PRESSURE_CSO "Vehicle configuration - customer settings menu 1 P";
BA_ "GenSigTimeout_IC" SG_ 947 VC_PTO_CSO 21000;
BA_ "GenSigSNA" SG_ 947 VC_PTO_CSO "0h";
BA_ "GenSigSendType" SG_ 947 VC_PTO_CSO 5;
BA_ "GenSigCycleTime" SG_ 947 VC_PTO_CSO 2000;
BA_ "FlexKomSigStartValue" SG_ 947 VC_PTO_CSO "0300000000000000h";
BA_ "FlexKomSigStartPos" SG_ 947 VC_PTO_CSO 7;
BA_ "FlexKomSigName" SG_ 947 VC_PTO_CSO "VehCfgCSM1_Pkt";
BA_ "FlexKomSigLaenge" SG_ 947 VC_PTO_CSO 64;
BA_ "FlexKomSID" SG_ 947 VC_PTO_CSO 2006;
BA_ "FlexKomIsMotorola" SG_ 947 VC_PTO_CSO 1;
BA_ "FlexKomComment" SG_ 947 VC_PTO_CSO "Vehicle configuration - customer settings menu 1 P";
BA_ "GenSigTimeout_IC" SG_ 947 VC_RAIN_WPR_CSO 21000;
BA_ "GenSigSNA" SG_ 947 VC_RAIN_WPR_CSO "0h";
BA_ "GenSigSendType" SG_ 947 VC_RAIN_WPR_CSO 5;
BA_ "GenSigCycleTime" SG_ 947 VC_RAIN_WPR_CSO 2000;
BA_ "FlexKomSigStartValue" SG_ 947 VC_RAIN_WPR_CSO "0300000000000000h";
BA_ "FlexKomSigStartPos" SG_ 947 VC_RAIN_WPR_CSO 7;
BA_ "FlexKomSigName" SG_ 947 VC_RAIN_WPR_CSO "VehCfgCSM1_Pkt";
BA_ "FlexKomSigLaenge" SG_ 947 VC_RAIN_WPR_CSO 64;
BA_ "FlexKomSID" SG_ 947 VC_RAIN_WPR_CSO 2006;
BA_ "FlexKomIsMotorola" SG_ 947 VC_RAIN_WPR_CSO 1;
BA_ "FlexKomComment" SG_ 947 VC_RAIN_WPR_CSO "Vehicle configuration - customer settings menu 1 P";
BA_ "GenSigTimeout_IC" SG_ 947 VC_REAR_CMRA_CSO 21000;
BA_ "GenSigSNA" SG_ 947 VC_REAR_CMRA_CSO "0h";
BA_ "GenSigSendType" SG_ 947 VC_REAR_CMRA_CSO 5;
BA_ "GenSigCycleTime" SG_ 947 VC_REAR_CMRA_CSO 2000;
BA_ "FlexKomSigStartValue" SG_ 947 VC_REAR_CMRA_CSO "0300000000000000h";
BA_ "FlexKomSigStartPos" SG_ 947 VC_REAR_CMRA_CSO 7;
BA_ "FlexKomSigName" SG_ 947 VC_REAR_CMRA_CSO "VehCfgCSM1_Pkt";
BA_ "FlexKomSigLaenge" SG_ 947 VC_REAR_CMRA_CSO 64;
BA_ "FlexKomSID" SG_ 947 VC_REAR_CMRA_CSO 2006;
BA_ "FlexKomIsMotorola" SG_ 947 VC_REAR_CMRA_CSO 1;
BA_ "FlexKomComment" SG_ 947 VC_REAR_CMRA_CSO "Vehicle configuration - customer settings menu 1 P";
BA_ "GenSigTimeout_IC" SG_ 947 VC_VehCfgCSO1_Stat 21000;
BA_ "GenSigStartValue" SG_ 947 VC_VehCfgCSO1_Stat 3;
BA_ "GenSigSNA" SG_ 947 VC_VehCfgCSO1_Stat "3h";
BA_ "GenSigSendType" SG_ 947 VC_VehCfgCSO1_Stat 5;
BA_ "GenSigCycleTime" SG_ 947 VC_VehCfgCSO1_Stat 2000;
BA_ "FlexKomSigStartValue" SG_ 947 VC_VehCfgCSO1_Stat "0300000000000000h";
BA_ "FlexKomSigStartPos" SG_ 947 VC_VehCfgCSO1_Stat 7;
BA_ "FlexKomSigName" SG_ 947 VC_VehCfgCSO1_Stat "VehCfgCSM1_Pkt";
BA_ "FlexKomSigLaenge" SG_ 947 VC_VehCfgCSO1_Stat 64;
BA_ "FlexKomSID" SG_ 947 VC_VehCfgCSO1_Stat 2006;
BA_ "FlexKomIsMotorola" SG_ 947 VC_VehCfgCSO1_Stat 1;
BA_ "FlexKomComment" SG_ 947 VC_VehCfgCSO1_Stat "Vehicle configuration - customer settings menu 1 P";
BA_ "GenSigTimeout_IC" SG_ 948 VC_TEEN_BLIND_SPOT_CSO 21000;
BA_ "GenSigSNA" SG_ 948 VC_TEEN_BLIND_SPOT_CSO "0h";
BA_ "GenSigSendType" SG_ 948 VC_TEEN_BLIND_SPOT_CSO 5;
BA_ "GenSigCycleTime" SG_ 948 VC_TEEN_BLIND_SPOT_CSO 2000;
BA_ "FlexKomSigStartValue" SG_ 948 VC_TEEN_BLIND_SPOT_CSO "0300000000000000h";
BA_ "FlexKomSigStartPos" SG_ 948 VC_TEEN_BLIND_SPOT_CSO 7;
BA_ "FlexKomSigName" SG_ 948 VC_TEEN_BLIND_SPOT_CSO "VehCfgCSM2_Pkt";
BA_ "FlexKomSigLaenge" SG_ 948 VC_TEEN_BLIND_SPOT_CSO 64;
BA_ "FlexKomSID" SG_ 948 VC_TEEN_BLIND_SPOT_CSO 2007;
BA_ "FlexKomIsMotorola" SG_ 948 VC_TEEN_BLIND_SPOT_CSO 1;
BA_ "FlexKomComment" SG_ 948 VC_TEEN_BLIND_SPOT_CSO "Vehicle configuration - customer settings menu 2 P";
BA_ "GenSigTimeout_IC" SG_ 948 VC_TEEN_RAIN_WPR_CSO 21000;
BA_ "GenSigSNA" SG_ 948 VC_TEEN_RAIN_WPR_CSO "0h";
BA_ "GenSigSendType" SG_ 948 VC_TEEN_RAIN_WPR_CSO 5;
BA_ "GenSigCycleTime" SG_ 948 VC_TEEN_RAIN_WPR_CSO 2000;
BA_ "FlexKomSigStartValue" SG_ 948 VC_TEEN_RAIN_WPR_CSO "0300000000000000h";
BA_ "FlexKomSigStartPos" SG_ 948 VC_TEEN_RAIN_WPR_CSO 7;
BA_ "FlexKomSigName" SG_ 948 VC_TEEN_RAIN_WPR_CSO "VehCfgCSM2_Pkt";
BA_ "FlexKomSigLaenge" SG_ 948 VC_TEEN_RAIN_WPR_CSO 64;
BA_ "FlexKomSID" SG_ 948 VC_TEEN_RAIN_WPR_CSO 2007;
BA_ "FlexKomIsMotorola" SG_ 948 VC_TEEN_RAIN_WPR_CSO 1;
BA_ "FlexKomComment" SG_ 948 VC_TEEN_RAIN_WPR_CSO "Vehicle configuration - customer settings menu 2 P";
BA_ "GenSigTimeout_IC" SG_ 948 VC_TEEN_AUTO_HB_CSO 21000;
BA_ "GenSigSNA" SG_ 948 VC_TEEN_AUTO_HB_CSO "0h";
BA_ "GenSigSendType" SG_ 948 VC_TEEN_AUTO_HB_CSO 5;
BA_ "GenSigCycleTime" SG_ 948 VC_TEEN_AUTO_HB_CSO 2000;
BA_ "FlexKomSigStartValue" SG_ 948 VC_TEEN_AUTO_HB_CSO "0300000000000000h";
BA_ "FlexKomSigStartPos" SG_ 948 VC_TEEN_AUTO_HB_CSO 7;
BA_ "FlexKomSigName" SG_ 948 VC_TEEN_AUTO_HB_CSO "VehCfgCSM2_Pkt";
BA_ "FlexKomSigLaenge" SG_ 948 VC_TEEN_AUTO_HB_CSO 64;
BA_ "FlexKomSID" SG_ 948 VC_TEEN_AUTO_HB_CSO 2007;
BA_ "FlexKomIsMotorola" SG_ 948 VC_TEEN_AUTO_HB_CSO 1;
BA_ "FlexKomComment" SG_ 948 VC_TEEN_AUTO_HB_CSO "Vehicle configuration - customer settings menu 2 P";
BA_ "GenSigTimeout_IC" SG_ 948 VC_TEEN_LGHT_WPR_CSO 21000;
BA_ "GenSigSNA" SG_ 948 VC_TEEN_LGHT_WPR_CSO "0h";
BA_ "GenSigSendType" SG_ 948 VC_TEEN_LGHT_WPR_CSO 5;
BA_ "GenSigCycleTime" SG_ 948 VC_TEEN_LGHT_WPR_CSO 2000;
BA_ "FlexKomSigStartValue" SG_ 948 VC_TEEN_LGHT_WPR_CSO "0300000000000000h";
BA_ "FlexKomSigStartPos" SG_ 948 VC_TEEN_LGHT_WPR_CSO 7;
BA_ "FlexKomSigName" SG_ 948 VC_TEEN_LGHT_WPR_CSO "VehCfgCSM2_Pkt";
BA_ "FlexKomSigLaenge" SG_ 948 VC_TEEN_LGHT_WPR_CSO 64;
BA_ "FlexKomSID" SG_ 948 VC_TEEN_LGHT_WPR_CSO 2007;
BA_ "FlexKomIsMotorola" SG_ 948 VC_TEEN_LGHT_WPR_CSO 1;
BA_ "FlexKomComment" SG_ 948 VC_TEEN_LGHT_WPR_CSO "Vehicle configuration - customer settings menu 2 P";
BA_ "GenSigTimeout_IC" SG_ 948 VC_TEEN_SLD_DR_ALRT_CSO 21000;
BA_ "GenSigSNA" SG_ 948 VC_TEEN_SLD_DR_ALRT_CSO "0h";
BA_ "GenSigSendType" SG_ 948 VC_TEEN_SLD_DR_ALRT_CSO 5;
BA_ "GenSigCycleTime" SG_ 948 VC_TEEN_SLD_DR_ALRT_CSO 2000;
BA_ "FlexKomSigStartValue" SG_ 948 VC_TEEN_SLD_DR_ALRT_CSO "0300000000000000h";
BA_ "FlexKomSigStartPos" SG_ 948 VC_TEEN_SLD_DR_ALRT_CSO 7;
BA_ "FlexKomSigName" SG_ 948 VC_TEEN_SLD_DR_ALRT_CSO "VehCfgCSM2_Pkt";
BA_ "FlexKomSigLaenge" SG_ 948 VC_TEEN_SLD_DR_ALRT_CSO 64;
BA_ "FlexKomSID" SG_ 948 VC_TEEN_SLD_DR_ALRT_CSO 2007;
BA_ "FlexKomIsMotorola" SG_ 948 VC_TEEN_SLD_DR_ALRT_CSO 1;
BA_ "FlexKomComment" SG_ 948 VC_TEEN_SLD_DR_ALRT_CSO "Vehicle configuration - customer settings menu 2 P";
BA_ "GenSigTimeout_IC" SG_ 948 VC_TEEN_PLG_CHIME_CSO 21000;
BA_ "GenSigSNA" SG_ 948 VC_TEEN_PLG_CHIME_CSO "0h";
BA_ "GenSigSendType" SG_ 948 VC_TEEN_PLG_CHIME_CSO 5;
BA_ "GenSigCycleTime" SG_ 948 VC_TEEN_PLG_CHIME_CSO 2000;
BA_ "FlexKomSigStartValue" SG_ 948 VC_TEEN_PLG_CHIME_CSO "0300000000000000h";
BA_ "FlexKomSigStartPos" SG_ 948 VC_TEEN_PLG_CHIME_CSO 7;
BA_ "FlexKomSigName" SG_ 948 VC_TEEN_PLG_CHIME_CSO "VehCfgCSM2_Pkt";
BA_ "FlexKomSigLaenge" SG_ 948 VC_TEEN_PLG_CHIME_CSO 64;
BA_ "FlexKomSID" SG_ 948 VC_TEEN_PLG_CHIME_CSO 2007;
BA_ "FlexKomIsMotorola" SG_ 948 VC_TEEN_PLG_CHIME_CSO 1;
BA_ "FlexKomComment" SG_ 948 VC_TEEN_PLG_CHIME_CSO "Vehicle configuration - customer settings menu 2 P";
BA_ "GenSigTimeout_IC" SG_ 948 VC_SLD_DR_CHM_CSO 21000;
BA_ "GenSigSNA" SG_ 948 VC_SLD_DR_CHM_CSO "0h";
BA_ "GenSigSendType" SG_ 948 VC_SLD_DR_CHM_CSO 5;
BA_ "GenSigCycleTime" SG_ 948 VC_SLD_DR_CHM_CSO 2000;
BA_ "FlexKomSigStartValue" SG_ 948 VC_SLD_DR_CHM_CSO "0300000000000000h";
BA_ "FlexKomSigStartPos" SG_ 948 VC_SLD_DR_CHM_CSO 7;
BA_ "FlexKomSigName" SG_ 948 VC_SLD_DR_CHM_CSO "VehCfgCSM2_Pkt";
BA_ "FlexKomSigLaenge" SG_ 948 VC_SLD_DR_CHM_CSO 64;
BA_ "FlexKomSID" SG_ 948 VC_SLD_DR_CHM_CSO 2007;
BA_ "FlexKomIsMotorola" SG_ 948 VC_SLD_DR_CHM_CSO 1;
BA_ "FlexKomComment" SG_ 948 VC_SLD_DR_CHM_CSO "Vehicle configuration - customer settings menu 2 P";
BA_ "GenSigTimeout_IC" SG_ 948 VC_TEEN_SLD_DR_CHM_CSO 21000;
BA_ "GenSigSNA" SG_ 948 VC_TEEN_SLD_DR_CHM_CSO "0h";
BA_ "GenSigSendType" SG_ 948 VC_TEEN_SLD_DR_CHM_CSO 5;
BA_ "GenSigCycleTime" SG_ 948 VC_TEEN_SLD_DR_CHM_CSO 2000;
BA_ "FlexKomSigStartValue" SG_ 948 VC_TEEN_SLD_DR_CHM_CSO "0300000000000000h";
BA_ "FlexKomSigStartPos" SG_ 948 VC_TEEN_SLD_DR_CHM_CSO 7;
BA_ "FlexKomSigName" SG_ 948 VC_TEEN_SLD_DR_CHM_CSO "VehCfgCSM2_Pkt";
BA_ "FlexKomSigLaenge" SG_ 948 VC_TEEN_SLD_DR_CHM_CSO 64;
BA_ "FlexKomSID" SG_ 948 VC_TEEN_SLD_DR_CHM_CSO 2007;
BA_ "FlexKomIsMotorola" SG_ 948 VC_TEEN_SLD_DR_CHM_CSO 1;
BA_ "FlexKomComment" SG_ 948 VC_TEEN_SLD_DR_CHM_CSO "Vehicle configuration - customer settings menu 2 P";
BA_ "GenSigTimeout_IC" SG_ 948 VC_PADDLE_SHIFT_CSO 21000;
BA_ "GenSigSNA" SG_ 948 VC_PADDLE_SHIFT_CSO "0h";
BA_ "GenSigSendType" SG_ 948 VC_PADDLE_SHIFT_CSO 5;
BA_ "GenSigCycleTime" SG_ 948 VC_PADDLE_SHIFT_CSO 2000;
BA_ "FlexKomSigStartValue" SG_ 948 VC_PADDLE_SHIFT_CSO "0300000000000000h";
BA_ "FlexKomSigStartPos" SG_ 948 VC_PADDLE_SHIFT_CSO 7;
BA_ "FlexKomSigName" SG_ 948 VC_PADDLE_SHIFT_CSO "VehCfgCSM2_Pkt";
BA_ "FlexKomSigLaenge" SG_ 948 VC_PADDLE_SHIFT_CSO 64;
BA_ "FlexKomSID" SG_ 948 VC_PADDLE_SHIFT_CSO 2007;
BA_ "FlexKomIsMotorola" SG_ 948 VC_PADDLE_SHIFT_CSO 1;
BA_ "FlexKomComment" SG_ 948 VC_PADDLE_SHIFT_CSO "Vehicle configuration - customer settings menu 2 P";
BA_ "GenSigSNA" SG_ 948 VC_FLSH_LMP_SLDR_CSO "0h";
BA_ "GenSigSendType" SG_ 948 VC_FLSH_LMP_SLDR_CSO 5;
BA_ "GenSigCycleTime" SG_ 948 VC_FLSH_LMP_SLDR_CSO 2000;
BA_ "FlexKomSigStartValue" SG_ 948 VC_FLSH_LMP_SLDR_CSO "0300000000000000h";
BA_ "FlexKomSigStartPos" SG_ 948 VC_FLSH_LMP_SLDR_CSO 7;
BA_ "FlexKomSigName" SG_ 948 VC_FLSH_LMP_SLDR_CSO "VehCfgCSM2_Pkt";
BA_ "FlexKomSigLaenge" SG_ 948 VC_FLSH_LMP_SLDR_CSO 64;
BA_ "FlexKomSID" SG_ 948 VC_FLSH_LMP_SLDR_CSO 2007;
BA_ "FlexKomIsMotorola" SG_ 948 VC_FLSH_LMP_SLDR_CSO 1;
BA_ "FlexKomComment" SG_ 948 VC_FLSH_LMP_SLDR_CSO "Vehicle configuration - customer settings menu 2 P";
BA_ "GenSigTimeout_IC" SG_ 948 VC_SPEED_WARNING_CSO 21000;
BA_ "GenSigSNA" SG_ 948 VC_SPEED_WARNING_CSO "0h";
BA_ "GenSigSendType" SG_ 948 VC_SPEED_WARNING_CSO 5;
BA_ "GenSigCycleTime" SG_ 948 VC_SPEED_WARNING_CSO 2000;
BA_ "FlexKomSigStartValue" SG_ 948 VC_SPEED_WARNING_CSO "0300000000000000h";
BA_ "FlexKomSigStartPos" SG_ 948 VC_SPEED_WARNING_CSO 7;
BA_ "FlexKomSigName" SG_ 948 VC_SPEED_WARNING_CSO "VehCfgCSM2_Pkt";
BA_ "FlexKomSigLaenge" SG_ 948 VC_SPEED_WARNING_CSO 64;
BA_ "FlexKomSID" SG_ 948 VC_SPEED_WARNING_CSO 2007;
BA_ "FlexKomIsMotorola" SG_ 948 VC_SPEED_WARNING_CSO 1;
BA_ "FlexKomComment" SG_ 948 VC_SPEED_WARNING_CSO "Vehicle configuration - customer settings menu 2 P";
BA_ "GenSigTimeout_IC" SG_ 948 VC_LDW_ON_CSO 21000;
BA_ "GenSigSNA" SG_ 948 VC_LDW_ON_CSO "0h";
BA_ "GenSigSendType" SG_ 948 VC_LDW_ON_CSO 5;
BA_ "GenSigCycleTime" SG_ 948 VC_LDW_ON_CSO 2000;
BA_ "FlexKomSigStartValue" SG_ 948 VC_LDW_ON_CSO "0300000000000000h";
BA_ "FlexKomSigStartPos" SG_ 948 VC_LDW_ON_CSO 7;
BA_ "FlexKomSigName" SG_ 948 VC_LDW_ON_CSO "VehCfgCSM2_Pkt";
BA_ "FlexKomSigLaenge" SG_ 948 VC_LDW_ON_CSO 64;
BA_ "FlexKomSID" SG_ 948 VC_LDW_ON_CSO 2007;
BA_ "FlexKomIsMotorola" SG_ 948 VC_LDW_ON_CSO 1;
BA_ "FlexKomComment" SG_ 948 VC_LDW_ON_CSO "Vehicle configuration - customer settings menu 2 P";
BA_ "GenSigTimeout_IC" SG_ 948 VC_PRK_ASST_TYPE_CSO 21000;
BA_ "GenSigSNA" SG_ 948 VC_PRK_ASST_TYPE_CSO "0h";
BA_ "GenSigSendType" SG_ 948 VC_PRK_ASST_TYPE_CSO 5;
BA_ "GenSigCycleTime" SG_ 948 VC_PRK_ASST_TYPE_CSO 2000;
BA_ "FlexKomSigStartValue" SG_ 948 VC_PRK_ASST_TYPE_CSO "0300000000000000h";
BA_ "FlexKomSigStartPos" SG_ 948 VC_PRK_ASST_TYPE_CSO 7;
BA_ "FlexKomSigName" SG_ 948 VC_PRK_ASST_TYPE_CSO "VehCfgCSM2_Pkt";
BA_ "FlexKomSigLaenge" SG_ 948 VC_PRK_ASST_TYPE_CSO 64;
BA_ "FlexKomSID" SG_ 948 VC_PRK_ASST_TYPE_CSO 2007;
BA_ "FlexKomIsMotorola" SG_ 948 VC_PRK_ASST_TYPE_CSO 1;
BA_ "FlexKomComment" SG_ 948 VC_PRK_ASST_TYPE_CSO "Vehicle configuration - customer settings menu 2 P";
BA_ "GenSigTimeout_IC" SG_ 948 VC_SPEED_CSO 21000;
BA_ "GenSigSNA" SG_ 948 VC_SPEED_CSO "0h";
BA_ "GenSigSendType" SG_ 948 VC_SPEED_CSO 5;
BA_ "GenSigCycleTime" SG_ 948 VC_SPEED_CSO 2000;
BA_ "FlexKomSigStartValue" SG_ 948 VC_SPEED_CSO "0300000000000000h";
BA_ "FlexKomSigStartPos" SG_ 948 VC_SPEED_CSO 7;
BA_ "FlexKomSigName" SG_ 948 VC_SPEED_CSO "VehCfgCSM2_Pkt";
BA_ "FlexKomSigLaenge" SG_ 948 VC_SPEED_CSO 64;
BA_ "FlexKomSID" SG_ 948 VC_SPEED_CSO 2007;
BA_ "FlexKomIsMotorola" SG_ 948 VC_SPEED_CSO 1;
BA_ "FlexKomComment" SG_ 948 VC_SPEED_CSO "Vehicle configuration - customer settings menu 2 P";
BA_ "GenSigTimeout_IC" SG_ 948 VC_TLT_MRR_CSO 21000;
BA_ "GenSigSNA" SG_ 948 VC_TLT_MRR_CSO "0h";
BA_ "GenSigSendType" SG_ 948 VC_TLT_MRR_CSO 5;
BA_ "GenSigCycleTime" SG_ 948 VC_TLT_MRR_CSO 2000;
BA_ "FlexKomSigStartValue" SG_ 948 VC_TLT_MRR_CSO "0300000000000000h";
BA_ "FlexKomSigStartPos" SG_ 948 VC_TLT_MRR_CSO 7;
BA_ "FlexKomSigName" SG_ 948 VC_TLT_MRR_CSO "VehCfgCSM2_Pkt";
BA_ "FlexKomSigLaenge" SG_ 948 VC_TLT_MRR_CSO 64;
BA_ "FlexKomSID" SG_ 948 VC_TLT_MRR_CSO 2007;
BA_ "FlexKomIsMotorola" SG_ 948 VC_TLT_MRR_CSO 1;
BA_ "FlexKomComment" SG_ 948 VC_TLT_MRR_CSO "Vehicle configuration - customer settings menu 2 P";
BA_ "GenSigTimeout_IC" SG_ 948 VC_TORQUE_CSO 21000;
BA_ "GenSigSNA" SG_ 948 VC_TORQUE_CSO "0h";
BA_ "GenSigSendType" SG_ 948 VC_TORQUE_CSO 5;
BA_ "GenSigCycleTime" SG_ 948 VC_TORQUE_CSO 2000;
BA_ "FlexKomSigStartValue" SG_ 948 VC_TORQUE_CSO "0300000000000000h";
BA_ "FlexKomSigStartPos" SG_ 948 VC_TORQUE_CSO 7;
BA_ "FlexKomSigName" SG_ 948 VC_TORQUE_CSO "VehCfgCSM2_Pkt";
BA_ "FlexKomSigLaenge" SG_ 948 VC_TORQUE_CSO 64;
BA_ "FlexKomSID" SG_ 948 VC_TORQUE_CSO 2007;
BA_ "FlexKomIsMotorola" SG_ 948 VC_TORQUE_CSO 1;
BA_ "FlexKomComment" SG_ 948 VC_TORQUE_CSO "Vehicle configuration - customer settings menu 2 P";
BA_ "GenSigTimeout_IC" SG_ 948 VC_TRLR_CSO 21000;
BA_ "GenSigSNA" SG_ 948 VC_TRLR_CSO "0h";
BA_ "GenSigSendType" SG_ 948 VC_TRLR_CSO 5;
BA_ "GenSigCycleTime" SG_ 948 VC_TRLR_CSO 2000;
BA_ "FlexKomSigStartValue" SG_ 948 VC_TRLR_CSO "0300000000000000h";
BA_ "FlexKomSigStartPos" SG_ 948 VC_TRLR_CSO 7;
BA_ "FlexKomSigName" SG_ 948 VC_TRLR_CSO "VehCfgCSM2_Pkt";
BA_ "FlexKomSigLaenge" SG_ 948 VC_TRLR_CSO 64;
BA_ "FlexKomSID" SG_ 948 VC_TRLR_CSO 2007;
BA_ "FlexKomIsMotorola" SG_ 948 VC_TRLR_CSO 1;
BA_ "FlexKomComment" SG_ 948 VC_TRLR_CSO "Vehicle configuration - customer settings menu 2 P";
BA_ "GenSigTimeout_IC" SG_ 948 VC_TRLR_NAME_CSO 21000;
BA_ "GenSigSNA" SG_ 948 VC_TRLR_NAME_CSO "0h";
BA_ "GenSigSendType" SG_ 948 VC_TRLR_NAME_CSO 5;
BA_ "GenSigCycleTime" SG_ 948 VC_TRLR_NAME_CSO 2000;
BA_ "FlexKomSigStartValue" SG_ 948 VC_TRLR_NAME_CSO "0300000000000000h";
BA_ "FlexKomSigStartPos" SG_ 948 VC_TRLR_NAME_CSO 7;
BA_ "FlexKomSigName" SG_ 948 VC_TRLR_NAME_CSO "VehCfgCSM2_Pkt";
BA_ "FlexKomSigLaenge" SG_ 948 VC_TRLR_NAME_CSO 64;
BA_ "FlexKomSID" SG_ 948 VC_TRLR_NAME_CSO 2007;
BA_ "FlexKomIsMotorola" SG_ 948 VC_TRLR_NAME_CSO 1;
BA_ "FlexKomComment" SG_ 948 VC_TRLR_NAME_CSO "Vehicle configuration - customer settings menu 2 P";
BA_ "GenSigTimeout_IC" SG_ 948 VC_TRLR_TYPE_CSO 21000;
BA_ "GenSigSNA" SG_ 948 VC_TRLR_TYPE_CSO "0h";
BA_ "GenSigSendType" SG_ 948 VC_TRLR_TYPE_CSO 5;
BA_ "GenSigCycleTime" SG_ 948 VC_TRLR_TYPE_CSO 2000;
BA_ "FlexKomSigStartValue" SG_ 948 VC_TRLR_TYPE_CSO "0300000000000000h";
BA_ "FlexKomSigStartPos" SG_ 948 VC_TRLR_TYPE_CSO 7;
BA_ "FlexKomSigName" SG_ 948 VC_TRLR_TYPE_CSO "VehCfgCSM2_Pkt";
BA_ "FlexKomSigLaenge" SG_ 948 VC_TRLR_TYPE_CSO 64;
BA_ "FlexKomSID" SG_ 948 VC_TRLR_TYPE_CSO 2007;
BA_ "FlexKomIsMotorola" SG_ 948 VC_TRLR_TYPE_CSO 1;
BA_ "FlexKomComment" SG_ 948 VC_TRLR_TYPE_CSO "Vehicle configuration - customer settings menu 2 P";
BA_ "GenSigTimeout_IC" SG_ 948 VC_TRNS_MD_CSO 21000;
BA_ "GenSigSNA" SG_ 948 VC_TRNS_MD_CSO "0h";
BA_ "GenSigSendType" SG_ 948 VC_TRNS_MD_CSO 5;
BA_ "GenSigCycleTime" SG_ 948 VC_TRNS_MD_CSO 2000;
BA_ "FlexKomSigStartValue" SG_ 948 VC_TRNS_MD_CSO "0300000000000000h";
BA_ "FlexKomSigStartPos" SG_ 948 VC_TRNS_MD_CSO 7;
BA_ "FlexKomSigName" SG_ 948 VC_TRNS_MD_CSO "VehCfgCSM2_Pkt";
BA_ "FlexKomSigLaenge" SG_ 948 VC_TRNS_MD_CSO 64;
BA_ "FlexKomSID" SG_ 948 VC_TRNS_MD_CSO 2007;
BA_ "FlexKomIsMotorola" SG_ 948 VC_TRNS_MD_CSO 1;
BA_ "FlexKomComment" SG_ 948 VC_TRNS_MD_CSO "Vehicle configuration - customer settings menu 2 P";
BA_ "GenSigTimeout_IC" SG_ 948 VC_US_METRIC_CSO 21000;
BA_ "GenSigSNA" SG_ 948 VC_US_METRIC_CSO "0h";
BA_ "GenSigSendType" SG_ 948 VC_US_METRIC_CSO 5;
BA_ "GenSigCycleTime" SG_ 948 VC_US_METRIC_CSO 2000;
BA_ "FlexKomSigStartValue" SG_ 948 VC_US_METRIC_CSO "0300000000000000h";
BA_ "FlexKomSigStartPos" SG_ 948 VC_US_METRIC_CSO 7;
BA_ "FlexKomSigName" SG_ 948 VC_US_METRIC_CSO "VehCfgCSM2_Pkt";
BA_ "FlexKomSigLaenge" SG_ 948 VC_US_METRIC_CSO 64;
BA_ "FlexKomSID" SG_ 948 VC_US_METRIC_CSO 2007;
BA_ "FlexKomIsMotorola" SG_ 948 VC_US_METRIC_CSO 1;
BA_ "FlexKomComment" SG_ 948 VC_US_METRIC_CSO "Vehicle configuration - customer settings menu 2 P";
BA_ "GenSigTimeout_IC" SG_ 948 VC_EPB_ON_CSO 21000;
BA_ "GenSigSNA" SG_ 948 VC_EPB_ON_CSO "0h";
BA_ "GenSigSendType" SG_ 948 VC_EPB_ON_CSO 5;
BA_ "GenSigCycleTime" SG_ 948 VC_EPB_ON_CSO 2000;
BA_ "FlexKomSigStartValue" SG_ 948 VC_EPB_ON_CSO "0300000000000000h";
BA_ "FlexKomSigStartPos" SG_ 948 VC_EPB_ON_CSO 7;
BA_ "FlexKomSigName" SG_ 948 VC_EPB_ON_CSO "VehCfgCSM2_Pkt";
BA_ "FlexKomSigLaenge" SG_ 948 VC_EPB_ON_CSO 64;
BA_ "FlexKomSID" SG_ 948 VC_EPB_ON_CSO 2007;
BA_ "FlexKomIsMotorola" SG_ 948 VC_EPB_ON_CSO 1;
BA_ "FlexKomComment" SG_ 948 VC_EPB_ON_CSO "Vehicle configuration - customer settings menu 2 P";
BA_ "GenSigTimeout_IC" SG_ 948 VC_AIRBAG_ON_CSO 21000;
BA_ "GenSigSNA" SG_ 948 VC_AIRBAG_ON_CSO "0h";
BA_ "GenSigSendType" SG_ 948 VC_AIRBAG_ON_CSO 5;
BA_ "GenSigCycleTime" SG_ 948 VC_AIRBAG_ON_CSO 2000;
BA_ "FlexKomSigStartValue" SG_ 948 VC_AIRBAG_ON_CSO "0300000000000000h";
BA_ "FlexKomSigStartPos" SG_ 948 VC_AIRBAG_ON_CSO 7;
BA_ "FlexKomSigName" SG_ 948 VC_AIRBAG_ON_CSO "VehCfgCSM2_Pkt";
BA_ "FlexKomSigLaenge" SG_ 948 VC_AIRBAG_ON_CSO 64;
BA_ "FlexKomSID" SG_ 948 VC_AIRBAG_ON_CSO 2007;
BA_ "FlexKomIsMotorola" SG_ 948 VC_AIRBAG_ON_CSO 1;
BA_ "FlexKomComment" SG_ 948 VC_AIRBAG_ON_CSO "Vehicle configuration - customer settings menu 2 P";
BA_ "GenSigTimeout_IC" SG_ 948 VC_FCW_SW_CSO 21000;
BA_ "GenSigSNA" SG_ 948 VC_FCW_SW_CSO "0h";
BA_ "GenSigSendType" SG_ 948 VC_FCW_SW_CSO 5;
BA_ "GenSigCycleTime" SG_ 948 VC_FCW_SW_CSO 2000;
BA_ "FlexKomSigStartValue" SG_ 948 VC_FCW_SW_CSO "0300000000000000h";
BA_ "FlexKomSigStartPos" SG_ 948 VC_FCW_SW_CSO 7;
BA_ "FlexKomSigName" SG_ 948 VC_FCW_SW_CSO "VehCfgCSM2_Pkt";
BA_ "FlexKomSigLaenge" SG_ 948 VC_FCW_SW_CSO 64;
BA_ "FlexKomSID" SG_ 948 VC_FCW_SW_CSO 2007;
BA_ "FlexKomIsMotorola" SG_ 948 VC_FCW_SW_CSO 1;
BA_ "FlexKomComment" SG_ 948 VC_FCW_SW_CSO "Vehicle configuration - customer settings menu 2 P";
BA_ "GenSigTimeout_IC" SG_ 948 VC_FCW_WARN_BRK_CSO 21000;
BA_ "GenSigSNA" SG_ 948 VC_FCW_WARN_BRK_CSO "0h";
BA_ "GenSigSendType" SG_ 948 VC_FCW_WARN_BRK_CSO 5;
BA_ "GenSigCycleTime" SG_ 948 VC_FCW_WARN_BRK_CSO 2000;
BA_ "FlexKomSigStartValue" SG_ 948 VC_FCW_WARN_BRK_CSO "0300000000000000h";
BA_ "FlexKomSigStartPos" SG_ 948 VC_FCW_WARN_BRK_CSO 7;
BA_ "FlexKomSigName" SG_ 948 VC_FCW_WARN_BRK_CSO "VehCfgCSM2_Pkt";
BA_ "FlexKomSigLaenge" SG_ 948 VC_FCW_WARN_BRK_CSO 64;
BA_ "FlexKomSID" SG_ 948 VC_FCW_WARN_BRK_CSO 2007;
BA_ "FlexKomIsMotorola" SG_ 948 VC_FCW_WARN_BRK_CSO 1;
BA_ "FlexKomComment" SG_ 948 VC_FCW_WARN_BRK_CSO "Vehicle configuration - customer settings menu 2 P";
BA_ "GenSigSNA" SG_ 948 VC_DOORS_OFF_ACC_DLY_CSO "0h";
BA_ "GenSigSendType" SG_ 948 VC_DOORS_OFF_ACC_DLY_CSO 5;
BA_ "GenSigCycleTime" SG_ 948 VC_DOORS_OFF_ACC_DLY_CSO 2000;
BA_ "FlexKomSigStartValue" SG_ 948 VC_DOORS_OFF_ACC_DLY_CSO "0300000000000000h";
BA_ "FlexKomSigStartPos" SG_ 948 VC_DOORS_OFF_ACC_DLY_CSO 7;
BA_ "FlexKomSigName" SG_ 948 VC_DOORS_OFF_ACC_DLY_CSO "VehCfgCSM2_Pkt";
BA_ "FlexKomSigLaenge" SG_ 948 VC_DOORS_OFF_ACC_DLY_CSO 64;
BA_ "FlexKomSID" SG_ 948 VC_DOORS_OFF_ACC_DLY_CSO 2007;
BA_ "FlexKomIsMotorola" SG_ 948 VC_DOORS_OFF_ACC_DLY_CSO 1;
BA_ "FlexKomComment" SG_ 948 VC_DOORS_OFF_ACC_DLY_CSO "Vehicle configuration - customer settings menu 2 P";
BA_ "GenSigTimeout_IC" SG_ 948 VC_TEEN_PRK_ASST_BRK_CSO 21000;
BA_ "GenSigSNA" SG_ 948 VC_TEEN_PRK_ASST_BRK_CSO "0h";
BA_ "GenSigSendType" SG_ 948 VC_TEEN_PRK_ASST_BRK_CSO 5;
BA_ "GenSigCycleTime" SG_ 948 VC_TEEN_PRK_ASST_BRK_CSO 2000;
BA_ "FlexKomSigStartValue" SG_ 948 VC_TEEN_PRK_ASST_BRK_CSO "0300000000000000h";
BA_ "FlexKomSigStartPos" SG_ 948 VC_TEEN_PRK_ASST_BRK_CSO 7;
BA_ "FlexKomSigName" SG_ 948 VC_TEEN_PRK_ASST_BRK_CSO "VehCfgCSM2_Pkt";
BA_ "FlexKomSigLaenge" SG_ 948 VC_TEEN_PRK_ASST_BRK_CSO 64;
BA_ "FlexKomSID" SG_ 948 VC_TEEN_PRK_ASST_BRK_CSO 2007;
BA_ "FlexKomIsMotorola" SG_ 948 VC_TEEN_PRK_ASST_BRK_CSO 1;
BA_ "FlexKomComment" SG_ 948 VC_TEEN_PRK_ASST_BRK_CSO "Vehicle configuration - customer settings menu 2 P";
BA_ "GenSigTimeout_IC" SG_ 948 VC_PCS_CSO 21000;
BA_ "GenSigSNA" SG_ 948 VC_PCS_CSO "0h";
BA_ "GenSigSendType" SG_ 948 VC_PCS_CSO 5;
BA_ "GenSigCycleTime" SG_ 948 VC_PCS_CSO 2000;
BA_ "FlexKomSigStartValue" SG_ 948 VC_PCS_CSO "0300000000000000h";
BA_ "FlexKomSigStartPos" SG_ 948 VC_PCS_CSO 7;
BA_ "FlexKomSigName" SG_ 948 VC_PCS_CSO "VehCfgCSM2_Pkt";
BA_ "FlexKomSigLaenge" SG_ 948 VC_PCS_CSO 64;
BA_ "FlexKomSID" SG_ 948 VC_PCS_CSO 2007;
BA_ "FlexKomIsMotorola" SG_ 948 VC_PCS_CSO 1;
BA_ "FlexKomComment" SG_ 948 VC_PCS_CSO "Vehicle configuration - customer settings menu 2 P";
BA_ "GenSigTimeout_IC" SG_ 948 VC_BSM_TRLR_CSO 21000;
BA_ "GenSigSNA" SG_ 948 VC_BSM_TRLR_CSO "0h";
BA_ "GenSigSendType" SG_ 948 VC_BSM_TRLR_CSO 5;
BA_ "GenSigCycleTime" SG_ 948 VC_BSM_TRLR_CSO 2000;
BA_ "FlexKomSigStartValue" SG_ 948 VC_BSM_TRLR_CSO "0300000000000000h";
BA_ "FlexKomSigStartPos" SG_ 948 VC_BSM_TRLR_CSO 7;
BA_ "FlexKomSigName" SG_ 948 VC_BSM_TRLR_CSO "VehCfgCSM2_Pkt";
BA_ "FlexKomSigLaenge" SG_ 948 VC_BSM_TRLR_CSO 64;
BA_ "FlexKomSID" SG_ 948 VC_BSM_TRLR_CSO 2007;
BA_ "FlexKomIsMotorola" SG_ 948 VC_BSM_TRLR_CSO 1;
BA_ "FlexKomComment" SG_ 948 VC_BSM_TRLR_CSO "Vehicle configuration - customer settings menu 2 P";
BA_ "GenSigTimeout_IC" SG_ 948 VC_AUTO_SS_CSO 21000;
BA_ "GenSigSNA" SG_ 948 VC_AUTO_SS_CSO "0h";
BA_ "GenSigSendType" SG_ 948 VC_AUTO_SS_CSO 5;
BA_ "GenSigCycleTime" SG_ 948 VC_AUTO_SS_CSO 2000;
BA_ "FlexKomSigStartValue" SG_ 948 VC_AUTO_SS_CSO "0300000000000000h";
BA_ "FlexKomSigStartPos" SG_ 948 VC_AUTO_SS_CSO 7;
BA_ "FlexKomSigName" SG_ 948 VC_AUTO_SS_CSO "VehCfgCSM2_Pkt";
BA_ "FlexKomSigLaenge" SG_ 948 VC_AUTO_SS_CSO 64;
BA_ "FlexKomSID" SG_ 948 VC_AUTO_SS_CSO 2007;
BA_ "FlexKomIsMotorola" SG_ 948 VC_AUTO_SS_CSO 1;
BA_ "FlexKomComment" SG_ 948 VC_AUTO_SS_CSO "Vehicle configuration - customer settings menu 2 P";
BA_ "GenSigTimeout_IC" SG_ 948 VC_RDY_DRV_CSO 21000;
BA_ "GenSigSNA" SG_ 948 VC_RDY_DRV_CSO "0h";
BA_ "GenSigSendType" SG_ 948 VC_RDY_DRV_CSO 5;
BA_ "GenSigCycleTime" SG_ 948 VC_RDY_DRV_CSO 2000;
BA_ "FlexKomSigStartValue" SG_ 948 VC_RDY_DRV_CSO "0300000000000000h";
BA_ "FlexKomSigStartPos" SG_ 948 VC_RDY_DRV_CSO 7;
BA_ "FlexKomSigName" SG_ 948 VC_RDY_DRV_CSO "VehCfgCSM2_Pkt";
BA_ "FlexKomSigLaenge" SG_ 948 VC_RDY_DRV_CSO 64;
BA_ "FlexKomSID" SG_ 948 VC_RDY_DRV_CSO 2007;
BA_ "FlexKomIsMotorola" SG_ 948 VC_RDY_DRV_CSO 1;
BA_ "FlexKomComment" SG_ 948 VC_RDY_DRV_CSO "Vehicle configuration - customer settings menu 2 P";
BA_ "GenSigTimeout_IC" SG_ 948 VC_VehCfgCSO2_Stat 21000;
BA_ "GenSigStartValue" SG_ 948 VC_VehCfgCSO2_Stat 3;
BA_ "GenSigSNA" SG_ 948 VC_VehCfgCSO2_Stat "3h";
BA_ "GenSigSendType" SG_ 948 VC_VehCfgCSO2_Stat 5;
BA_ "GenSigCycleTime" SG_ 948 VC_VehCfgCSO2_Stat 2000;
BA_ "FlexKomSigStartValue" SG_ 948 VC_VehCfgCSO2_Stat "0300000000000000h";
BA_ "FlexKomSigStartPos" SG_ 948 VC_VehCfgCSO2_Stat 7;
BA_ "FlexKomSigName" SG_ 948 VC_VehCfgCSO2_Stat "VehCfgCSM2_Pkt";
BA_ "FlexKomSigLaenge" SG_ 948 VC_VehCfgCSO2_Stat 64;
BA_ "FlexKomSID" SG_ 948 VC_VehCfgCSO2_Stat 2007;
BA_ "FlexKomIsMotorola" SG_ 948 VC_VehCfgCSO2_Stat 1;
BA_ "FlexKomComment" SG_ 948 VC_VehCfgCSO2_Stat "Vehicle configuration - customer settings menu 2 P";
BA_ "GenSigTimeout_IC" SG_ 948 VC_REAR_CMRA_DLY_CSO 21000;
BA_ "GenSigSNA" SG_ 948 VC_REAR_CMRA_DLY_CSO "0h";
BA_ "GenSigSendType" SG_ 948 VC_REAR_CMRA_DLY_CSO 5;
BA_ "GenSigCycleTime" SG_ 948 VC_REAR_CMRA_DLY_CSO 2000;
BA_ "FlexKomSigStartValue" SG_ 948 VC_REAR_CMRA_DLY_CSO "0300000000000000h";
BA_ "FlexKomSigStartPos" SG_ 948 VC_REAR_CMRA_DLY_CSO 7;
BA_ "FlexKomSigName" SG_ 948 VC_REAR_CMRA_DLY_CSO "VehCfgCSM2_Pkt";
BA_ "FlexKomSigLaenge" SG_ 948 VC_REAR_CMRA_DLY_CSO 64;
BA_ "FlexKomSID" SG_ 948 VC_REAR_CMRA_DLY_CSO 2007;
BA_ "FlexKomIsMotorola" SG_ 948 VC_REAR_CMRA_DLY_CSO 1;
BA_ "FlexKomComment" SG_ 948 VC_REAR_CMRA_DLY_CSO "Vehicle configuration - customer settings menu 2 P";
BA_ "GenSigTimeout_IC" SG_ 948 VC_RKE_MEM_CSO 21000;
BA_ "GenSigSNA" SG_ 948 VC_RKE_MEM_CSO "0h";
BA_ "GenSigSendType" SG_ 948 VC_RKE_MEM_CSO 5;
BA_ "GenSigCycleTime" SG_ 948 VC_RKE_MEM_CSO 2000;
BA_ "FlexKomSigStartValue" SG_ 948 VC_RKE_MEM_CSO "0300000000000000h";
BA_ "FlexKomSigStartPos" SG_ 948 VC_RKE_MEM_CSO 7;
BA_ "FlexKomSigName" SG_ 948 VC_RKE_MEM_CSO "VehCfgCSM2_Pkt";
BA_ "FlexKomSigLaenge" SG_ 948 VC_RKE_MEM_CSO 64;
BA_ "FlexKomSID" SG_ 948 VC_RKE_MEM_CSO 2007;
BA_ "FlexKomIsMotorola" SG_ 948 VC_RKE_MEM_CSO 1;
BA_ "FlexKomComment" SG_ 948 VC_RKE_MEM_CSO "Vehicle configuration - customer settings menu 2 P";
BA_ "GenSigTimeout_IC" SG_ 948 VC_RKE_UNLK_CSO 21000;
BA_ "GenSigSNA" SG_ 948 VC_RKE_UNLK_CSO "0h";
BA_ "GenSigSendType" SG_ 948 VC_RKE_UNLK_CSO 5;
BA_ "GenSigCycleTime" SG_ 948 VC_RKE_UNLK_CSO 2000;
BA_ "FlexKomSigStartValue" SG_ 948 VC_RKE_UNLK_CSO "0300000000000000h";
BA_ "FlexKomSigStartPos" SG_ 948 VC_RKE_UNLK_CSO 7;
BA_ "FlexKomSigName" SG_ 948 VC_RKE_UNLK_CSO "VehCfgCSM2_Pkt";
BA_ "FlexKomSigLaenge" SG_ 948 VC_RKE_UNLK_CSO 64;
BA_ "FlexKomSID" SG_ 948 VC_RKE_UNLK_CSO 2007;
BA_ "FlexKomIsMotorola" SG_ 948 VC_RKE_UNLK_CSO 1;
BA_ "FlexKomComment" SG_ 948 VC_RKE_UNLK_CSO "Vehicle configuration - customer settings menu 2 P";
BA_ "GenSigTimeout_IC" SG_ 948 VC_WHL_ALGN_CSO 21000;
BA_ "GenSigSNA" SG_ 948 VC_WHL_ALGN_CSO "0h";
BA_ "GenSigSendType" SG_ 948 VC_WHL_ALGN_CSO 5;
BA_ "GenSigCycleTime" SG_ 948 VC_WHL_ALGN_CSO 2000;
BA_ "FlexKomSigStartValue" SG_ 948 VC_WHL_ALGN_CSO "0300000000000000h";
BA_ "FlexKomSigStartPos" SG_ 948 VC_WHL_ALGN_CSO 7;
BA_ "FlexKomSigName" SG_ 948 VC_WHL_ALGN_CSO "VehCfgCSM2_Pkt";
BA_ "FlexKomSigLaenge" SG_ 948 VC_WHL_ALGN_CSO 64;
BA_ "FlexKomSID" SG_ 948 VC_WHL_ALGN_CSO 2007;
BA_ "FlexKomIsMotorola" SG_ 948 VC_WHL_ALGN_CSO 1;
BA_ "FlexKomComment" SG_ 948 VC_WHL_ALGN_CSO "Vehicle configuration - customer settings menu 2 P";
BA_ "GenSigTimeout_IC" SG_ 948 VC_FUEL_SAV_CSO 21000;
BA_ "GenSigSNA" SG_ 948 VC_FUEL_SAV_CSO "0h";
BA_ "GenSigSendType" SG_ 948 VC_FUEL_SAV_CSO 5;
BA_ "GenSigCycleTime" SG_ 948 VC_FUEL_SAV_CSO 2000;
BA_ "FlexKomSigStartValue" SG_ 948 VC_FUEL_SAV_CSO "0300000000000000h";
BA_ "FlexKomSigStartPos" SG_ 948 VC_FUEL_SAV_CSO 7;
BA_ "FlexKomSigName" SG_ 948 VC_FUEL_SAV_CSO "VehCfgCSM2_Pkt";
BA_ "FlexKomSigLaenge" SG_ 948 VC_FUEL_SAV_CSO 64;
BA_ "FlexKomSID" SG_ 948 VC_FUEL_SAV_CSO 2007;
BA_ "FlexKomIsMotorola" SG_ 948 VC_FUEL_SAV_CSO 1;
BA_ "FlexKomComment" SG_ 948 VC_FUEL_SAV_CSO "Vehicle configuration - customer settings menu 2 P";
BA_ "GenSigSNA" SG_ 948 VC_TEMP_CSO "0h";
BA_ "GenSigSendType" SG_ 948 VC_TEMP_CSO 5;
BA_ "GenSigCycleTime" SG_ 948 VC_TEMP_CSO 2000;
BA_ "FlexKomSigStartValue" SG_ 948 VC_TEMP_CSO "0300000000000000h";
BA_ "FlexKomSigStartPos" SG_ 948 VC_TEMP_CSO 7;
BA_ "FlexKomSigName" SG_ 948 VC_TEMP_CSO "VehCfgCSM2_Pkt";
BA_ "FlexKomSigLaenge" SG_ 948 VC_TEMP_CSO 64;
BA_ "FlexKomSID" SG_ 948 VC_TEMP_CSO 2007;
BA_ "FlexKomIsMotorola" SG_ 948 VC_TEMP_CSO 1;
BA_ "FlexKomComment" SG_ 948 VC_TEMP_CSO "Vehicle configuration - customer settings menu 2 P";
BA_ "GenSigTimeout_IC" SG_ 948 VC_HOLD_N_GO_CSO 21000;
BA_ "GenSigSNA" SG_ 948 VC_HOLD_N_GO_CSO "0h";
BA_ "GenSigSendType" SG_ 948 VC_HOLD_N_GO_CSO 5;
BA_ "GenSigCycleTime" SG_ 948 VC_HOLD_N_GO_CSO 2000;
BA_ "FlexKomSigStartValue" SG_ 948 VC_HOLD_N_GO_CSO "0300000000000000h";
BA_ "FlexKomSigStartPos" SG_ 948 VC_HOLD_N_GO_CSO 7;
BA_ "FlexKomSigName" SG_ 948 VC_HOLD_N_GO_CSO "VehCfgCSM2_Pkt";
BA_ "FlexKomSigLaenge" SG_ 948 VC_HOLD_N_GO_CSO 64;
BA_ "FlexKomSID" SG_ 948 VC_HOLD_N_GO_CSO 2007;
BA_ "FlexKomIsMotorola" SG_ 948 VC_HOLD_N_GO_CSO 1;
BA_ "FlexKomComment" SG_ 948 VC_HOLD_N_GO_CSO "Vehicle configuration - customer settings menu 2 P";
BA_ "GenSigTimeout_IC" SG_ 948 VC_PWR_FLD_MRR_CSO 21000;
BA_ "GenSigSNA" SG_ 948 VC_PWR_FLD_MRR_CSO "0h";
BA_ "GenSigSendType" SG_ 948 VC_PWR_FLD_MRR_CSO 5;
BA_ "GenSigCycleTime" SG_ 948 VC_PWR_FLD_MRR_CSO 2000;
BA_ "FlexKomSigStartValue" SG_ 948 VC_PWR_FLD_MRR_CSO "0300000000000000h";
BA_ "FlexKomSigStartPos" SG_ 948 VC_PWR_FLD_MRR_CSO 7;
BA_ "FlexKomSigName" SG_ 948 VC_PWR_FLD_MRR_CSO "VehCfgCSM2_Pkt";
BA_ "FlexKomSigLaenge" SG_ 948 VC_PWR_FLD_MRR_CSO 64;
BA_ "FlexKomSID" SG_ 948 VC_PWR_FLD_MRR_CSO 2007;
BA_ "FlexKomIsMotorola" SG_ 948 VC_PWR_FLD_MRR_CSO 1;
BA_ "FlexKomComment" SG_ 948 VC_PWR_FLD_MRR_CSO "Vehicle configuration - customer settings menu 2 P";
BA_ "GenSigTimeout_IC" SG_ 948 VC_HANDS_FREE_LFT_CSO 21000;
BA_ "GenSigSNA" SG_ 948 VC_HANDS_FREE_LFT_CSO "0h";
BA_ "GenSigSendType" SG_ 948 VC_HANDS_FREE_LFT_CSO 5;
BA_ "GenSigCycleTime" SG_ 948 VC_HANDS_FREE_LFT_CSO 2000;
BA_ "FlexKomSigStartValue" SG_ 948 VC_HANDS_FREE_LFT_CSO "0300000000000000h";
BA_ "FlexKomSigStartPos" SG_ 948 VC_HANDS_FREE_LFT_CSO 7;
BA_ "FlexKomSigName" SG_ 948 VC_HANDS_FREE_LFT_CSO "VehCfgCSM2_Pkt";
BA_ "FlexKomSigLaenge" SG_ 948 VC_HANDS_FREE_LFT_CSO 64;
BA_ "FlexKomSID" SG_ 948 VC_HANDS_FREE_LFT_CSO 2007;
BA_ "FlexKomIsMotorola" SG_ 948 VC_HANDS_FREE_LFT_CSO 1;
BA_ "FlexKomComment" SG_ 948 VC_HANDS_FREE_LFT_CSO "Vehicle configuration - customer settings menu 2 P";
BA_ "GenSigTimeout_IC" SG_ 948 VC_HANDS_FREE_SLDR_CSO 21000;
BA_ "GenSigSNA" SG_ 948 VC_HANDS_FREE_SLDR_CSO "0h";
BA_ "GenSigSendType" SG_ 948 VC_HANDS_FREE_SLDR_CSO 5;
BA_ "GenSigCycleTime" SG_ 948 VC_HANDS_FREE_SLDR_CSO 2000;
BA_ "FlexKomSigStartValue" SG_ 948 VC_HANDS_FREE_SLDR_CSO "0300000000000000h";
BA_ "FlexKomSigStartPos" SG_ 948 VC_HANDS_FREE_SLDR_CSO 7;
BA_ "FlexKomSigName" SG_ 948 VC_HANDS_FREE_SLDR_CSO "VehCfgCSM2_Pkt";
BA_ "FlexKomSigLaenge" SG_ 948 VC_HANDS_FREE_SLDR_CSO 64;
BA_ "FlexKomSID" SG_ 948 VC_HANDS_FREE_SLDR_CSO 2007;
BA_ "FlexKomIsMotorola" SG_ 948 VC_HANDS_FREE_SLDR_CSO 1;
BA_ "FlexKomComment" SG_ 948 VC_HANDS_FREE_SLDR_CSO "Vehicle configuration - customer settings menu 2 P";
BA_ "GenSigTimeout_IC" SG_ 948 VC_SVC_GRIDLINES_CSO 21000;
BA_ "GenSigSNA" SG_ 948 VC_SVC_GRIDLINES_CSO "0h";
BA_ "GenSigSendType" SG_ 948 VC_SVC_GRIDLINES_CSO 5;
BA_ "GenSigCycleTime" SG_ 948 VC_SVC_GRIDLINES_CSO 2000;
BA_ "FlexKomSigStartValue" SG_ 948 VC_SVC_GRIDLINES_CSO "0300000000000000h";
BA_ "FlexKomSigStartPos" SG_ 948 VC_SVC_GRIDLINES_CSO 7;
BA_ "FlexKomSigName" SG_ 948 VC_SVC_GRIDLINES_CSO "VehCfgCSM2_Pkt";
BA_ "FlexKomSigLaenge" SG_ 948 VC_SVC_GRIDLINES_CSO 64;
BA_ "FlexKomSID" SG_ 948 VC_SVC_GRIDLINES_CSO 2007;
BA_ "FlexKomIsMotorola" SG_ 948 VC_SVC_GRIDLINES_CSO 1;
BA_ "FlexKomComment" SG_ 948 VC_SVC_GRIDLINES_CSO "Vehicle configuration - customer settings menu 2 P";
BA_ "GenSigTimeout_IC" SG_ 948 VC_SVC_DELAY_CSO 21000;
BA_ "GenSigSNA" SG_ 948 VC_SVC_DELAY_CSO "0h";
BA_ "GenSigSendType" SG_ 948 VC_SVC_DELAY_CSO 5;
BA_ "GenSigCycleTime" SG_ 948 VC_SVC_DELAY_CSO 2000;
BA_ "FlexKomSigStartValue" SG_ 948 VC_SVC_DELAY_CSO "0300000000000000h";
BA_ "FlexKomSigStartPos" SG_ 948 VC_SVC_DELAY_CSO 7;
BA_ "FlexKomSigName" SG_ 948 VC_SVC_DELAY_CSO "VehCfgCSM2_Pkt";
BA_ "FlexKomSigLaenge" SG_ 948 VC_SVC_DELAY_CSO 64;
BA_ "FlexKomSID" SG_ 948 VC_SVC_DELAY_CSO 2007;
BA_ "FlexKomIsMotorola" SG_ 948 VC_SVC_DELAY_CSO 1;
BA_ "FlexKomComment" SG_ 948 VC_SVC_DELAY_CSO "Vehicle configuration - customer settings menu 2 P";
BA_ "GenSigTimeout_IC" SG_ 948 VC_SLD_DR_ALRT_CSO 21000;
BA_ "GenSigSNA" SG_ 948 VC_SLD_DR_ALRT_CSO "0h";
BA_ "GenSigSendType" SG_ 948 VC_SLD_DR_ALRT_CSO 5;
BA_ "GenSigCycleTime" SG_ 948 VC_SLD_DR_ALRT_CSO 2000;
BA_ "FlexKomSigStartValue" SG_ 948 VC_SLD_DR_ALRT_CSO "0300000000000000h";
BA_ "FlexKomSigStartPos" SG_ 948 VC_SLD_DR_ALRT_CSO 7;
BA_ "FlexKomSigName" SG_ 948 VC_SLD_DR_ALRT_CSO "VehCfgCSM2_Pkt";
BA_ "FlexKomSigLaenge" SG_ 948 VC_SLD_DR_ALRT_CSO 64;
BA_ "FlexKomSID" SG_ 948 VC_SLD_DR_ALRT_CSO 2007;
BA_ "FlexKomIsMotorola" SG_ 948 VC_SLD_DR_ALRT_CSO 1;
BA_ "FlexKomComment" SG_ 948 VC_SLD_DR_ALRT_CSO "Vehicle configuration - customer settings menu 2 P";
BA_ "GenSigTimeout_IC" SG_ 948 VC_TEEN_FCW_SENS_CSO 21000;
BA_ "GenSigSNA" SG_ 948 VC_TEEN_FCW_SENS_CSO "0h";
BA_ "GenSigSendType" SG_ 948 VC_TEEN_FCW_SENS_CSO 5;
BA_ "GenSigCycleTime" SG_ 948 VC_TEEN_FCW_SENS_CSO 2000;
BA_ "FlexKomSigStartValue" SG_ 948 VC_TEEN_FCW_SENS_CSO "0300000000000000h";
BA_ "FlexKomSigStartPos" SG_ 948 VC_TEEN_FCW_SENS_CSO 7;
BA_ "FlexKomSigName" SG_ 948 VC_TEEN_FCW_SENS_CSO "VehCfgCSM2_Pkt";
BA_ "FlexKomSigLaenge" SG_ 948 VC_TEEN_FCW_SENS_CSO 64;
BA_ "FlexKomSID" SG_ 948 VC_TEEN_FCW_SENS_CSO 2007;
BA_ "FlexKomIsMotorola" SG_ 948 VC_TEEN_FCW_SENS_CSO 1;
BA_ "FlexKomComment" SG_ 948 VC_TEEN_FCW_SENS_CSO "Vehicle configuration - customer settings menu 2 P";
BA_ "GenSigTimeout_IC" SG_ 948 VC_TEEN_FCW_BRK_CSO 21000;
BA_ "GenSigSNA" SG_ 948 VC_TEEN_FCW_BRK_CSO "0h";
BA_ "GenSigSendType" SG_ 948 VC_TEEN_FCW_BRK_CSO 5;
BA_ "GenSigCycleTime" SG_ 948 VC_TEEN_FCW_BRK_CSO 2000;
BA_ "FlexKomSigStartValue" SG_ 948 VC_TEEN_FCW_BRK_CSO "0300000000000000h";
BA_ "FlexKomSigStartPos" SG_ 948 VC_TEEN_FCW_BRK_CSO 7;
BA_ "FlexKomSigName" SG_ 948 VC_TEEN_FCW_BRK_CSO "VehCfgCSM2_Pkt";
BA_ "FlexKomSigLaenge" SG_ 948 VC_TEEN_FCW_BRK_CSO 64;
BA_ "FlexKomSID" SG_ 948 VC_TEEN_FCW_BRK_CSO 2007;
BA_ "FlexKomIsMotorola" SG_ 948 VC_TEEN_FCW_BRK_CSO 1;
BA_ "FlexKomComment" SG_ 948 VC_TEEN_FCW_BRK_CSO "Vehicle configuration - customer settings menu 2 P";
BA_ "GenSigTimeout_IC" SG_ 948 VC_TEEN_PRK_ASST_CSO 21000;
BA_ "GenSigSNA" SG_ 948 VC_TEEN_PRK_ASST_CSO "0h";
BA_ "GenSigSendType" SG_ 948 VC_TEEN_PRK_ASST_CSO 5;
BA_ "GenSigCycleTime" SG_ 948 VC_TEEN_PRK_ASST_CSO 2000;
BA_ "FlexKomSigStartValue" SG_ 948 VC_TEEN_PRK_ASST_CSO "0300000000000000h";
BA_ "FlexKomSigStartPos" SG_ 948 VC_TEEN_PRK_ASST_CSO 7;
BA_ "FlexKomSigName" SG_ 948 VC_TEEN_PRK_ASST_CSO "VehCfgCSM2_Pkt";
BA_ "FlexKomSigLaenge" SG_ 948 VC_TEEN_PRK_ASST_CSO 64;
BA_ "FlexKomSID" SG_ 948 VC_TEEN_PRK_ASST_CSO 2007;
BA_ "FlexKomIsMotorola" SG_ 948 VC_TEEN_PRK_ASST_CSO 1;
BA_ "FlexKomComment" SG_ 948 VC_TEEN_PRK_ASST_CSO "Vehicle configuration - customer settings menu 2 P";
BA_ "GenSigTimeout_IC" SG_ 948 VC_TEEN_FT_PRK_VOL_CSO 21000;
BA_ "GenSigSNA" SG_ 948 VC_TEEN_FT_PRK_VOL_CSO "0h";
BA_ "GenSigSendType" SG_ 948 VC_TEEN_FT_PRK_VOL_CSO 5;
BA_ "GenSigCycleTime" SG_ 948 VC_TEEN_FT_PRK_VOL_CSO 2000;
BA_ "FlexKomSigStartValue" SG_ 948 VC_TEEN_FT_PRK_VOL_CSO "0300000000000000h";
BA_ "FlexKomSigStartPos" SG_ 948 VC_TEEN_FT_PRK_VOL_CSO 7;
BA_ "FlexKomSigName" SG_ 948 VC_TEEN_FT_PRK_VOL_CSO "VehCfgCSM2_Pkt";
BA_ "FlexKomSigLaenge" SG_ 948 VC_TEEN_FT_PRK_VOL_CSO 64;
BA_ "FlexKomSID" SG_ 948 VC_TEEN_FT_PRK_VOL_CSO 2007;
BA_ "FlexKomIsMotorola" SG_ 948 VC_TEEN_FT_PRK_VOL_CSO 1;
BA_ "FlexKomComment" SG_ 948 VC_TEEN_FT_PRK_VOL_CSO "Vehicle configuration - customer settings menu 2 P";
BA_ "GenSigTimeout_IC" SG_ 948 VC_TEEN_RR_PRK_VOL_CSO 21000;
BA_ "GenSigSNA" SG_ 948 VC_TEEN_RR_PRK_VOL_CSO "0h";
BA_ "GenSigSendType" SG_ 948 VC_TEEN_RR_PRK_VOL_CSO 5;
BA_ "GenSigCycleTime" SG_ 948 VC_TEEN_RR_PRK_VOL_CSO 2000;
BA_ "FlexKomSigStartValue" SG_ 948 VC_TEEN_RR_PRK_VOL_CSO "0300000000000000h";
BA_ "FlexKomSigStartPos" SG_ 948 VC_TEEN_RR_PRK_VOL_CSO 7;
BA_ "FlexKomSigName" SG_ 948 VC_TEEN_RR_PRK_VOL_CSO "VehCfgCSM2_Pkt";
BA_ "FlexKomSigLaenge" SG_ 948 VC_TEEN_RR_PRK_VOL_CSO 64;
BA_ "FlexKomSID" SG_ 948 VC_TEEN_RR_PRK_VOL_CSO 2007;
BA_ "FlexKomIsMotorola" SG_ 948 VC_TEEN_RR_PRK_VOL_CSO 1;
BA_ "FlexKomComment" SG_ 948 VC_TEEN_RR_PRK_VOL_CSO "Vehicle configuration - customer settings menu 2 P";
BA_ "GenSigTimeout_IC" SG_ 948 VC_TEEN_MAX_SPEED_CSO 21000;
BA_ "GenSigSNA" SG_ 948 VC_TEEN_MAX_SPEED_CSO "0h";
BA_ "GenSigSendType" SG_ 948 VC_TEEN_MAX_SPEED_CSO 5;
BA_ "GenSigCycleTime" SG_ 948 VC_TEEN_MAX_SPEED_CSO 2000;
BA_ "FlexKomSigStartValue" SG_ 948 VC_TEEN_MAX_SPEED_CSO "0300000000000000h";
BA_ "FlexKomSigStartPos" SG_ 948 VC_TEEN_MAX_SPEED_CSO 7;
BA_ "FlexKomSigName" SG_ 948 VC_TEEN_MAX_SPEED_CSO "VehCfgCSM2_Pkt";
BA_ "FlexKomSigLaenge" SG_ 948 VC_TEEN_MAX_SPEED_CSO 64;
BA_ "FlexKomSID" SG_ 948 VC_TEEN_MAX_SPEED_CSO 2007;
BA_ "FlexKomIsMotorola" SG_ 948 VC_TEEN_MAX_SPEED_CSO 1;
BA_ "FlexKomComment" SG_ 948 VC_TEEN_MAX_SPEED_CSO "Vehicle configuration - customer settings menu 2 P";
BA_ "GenSigTimeout_IC" SG_ 948 VC_TEEN_FUEL_WRN_CSO 21000;
BA_ "GenSigSNA" SG_ 948 VC_TEEN_FUEL_WRN_CSO "0h";
BA_ "GenSigSendType" SG_ 948 VC_TEEN_FUEL_WRN_CSO 5;
BA_ "GenSigCycleTime" SG_ 948 VC_TEEN_FUEL_WRN_CSO 2000;
BA_ "FlexKomSigStartValue" SG_ 948 VC_TEEN_FUEL_WRN_CSO "0300000000000000h";
BA_ "FlexKomSigStartPos" SG_ 948 VC_TEEN_FUEL_WRN_CSO 7;
BA_ "FlexKomSigName" SG_ 948 VC_TEEN_FUEL_WRN_CSO "VehCfgCSM2_Pkt";
BA_ "FlexKomSigLaenge" SG_ 948 VC_TEEN_FUEL_WRN_CSO 64;
BA_ "FlexKomSID" SG_ 948 VC_TEEN_FUEL_WRN_CSO 2007;
BA_ "FlexKomIsMotorola" SG_ 948 VC_TEEN_FUEL_WRN_CSO 1;
BA_ "FlexKomComment" SG_ 948 VC_TEEN_FUEL_WRN_CSO "Vehicle configuration - customer settings menu 2 P";
BA_ "GenSigTimeout_IC" SG_ 948 VC_TEEN_FUEL_POPUP_CSO 21000;
BA_ "GenSigSNA" SG_ 948 VC_TEEN_FUEL_POPUP_CSO "0h";
BA_ "GenSigSendType" SG_ 948 VC_TEEN_FUEL_POPUP_CSO 5;
BA_ "GenSigCycleTime" SG_ 948 VC_TEEN_FUEL_POPUP_CSO 2000;
BA_ "FlexKomSigStartValue" SG_ 948 VC_TEEN_FUEL_POPUP_CSO "0300000000000000h";
BA_ "FlexKomSigStartPos" SG_ 948 VC_TEEN_FUEL_POPUP_CSO 7;
BA_ "FlexKomSigName" SG_ 948 VC_TEEN_FUEL_POPUP_CSO "VehCfgCSM2_Pkt";
BA_ "FlexKomSigLaenge" SG_ 948 VC_TEEN_FUEL_POPUP_CSO 64;
BA_ "FlexKomSID" SG_ 948 VC_TEEN_FUEL_POPUP_CSO 2007;
BA_ "FlexKomIsMotorola" SG_ 948 VC_TEEN_FUEL_POPUP_CSO 1;
BA_ "FlexKomComment" SG_ 948 VC_TEEN_FUEL_POPUP_CSO "Vehicle configuration - customer settings menu 2 P";
BA_ "GenSigStartValue" SG_ 949 VC_BU_VehCfgCSO1_Stat 3;
BA_ "GenSigSNA" SG_ 949 VC_BU_VehCfgCSO1_Stat "3h";
BA_ "GenSigSendType" SG_ 949 VC_BU_VehCfgCSO1_Stat 1;
BA_ "FlexKomSigStartValue" SG_ 949 VC_BU_VehCfgCSO1_Stat "0300000000000000h";
BA_ "FlexKomSigStartPos" SG_ 949 VC_BU_VehCfgCSO1_Stat 7;
BA_ "FlexKomSigName" SG_ 949 VC_BU_VehCfgCSO1_Stat "VehCfgCSM1_BuPkt";
BA_ "FlexKomSigLaenge" SG_ 949 VC_BU_VehCfgCSO1_Stat 64;
BA_ "FlexKomSID" SG_ 949 VC_BU_VehCfgCSO1_Stat 2008;
BA_ "FlexKomIsMotorola" SG_ 949 VC_BU_VehCfgCSO1_Stat 1;
BA_ "FlexKomComment" SG_ 949 VC_BU_VehCfgCSO1_Stat "Backup for veh config - customer settings menu 1 P";
BA_ "GenSigSNA" SG_ 949 VC_BU_PRK_AST_CSO "0h";
BA_ "GenSigSendType" SG_ 949 VC_BU_PRK_AST_CSO 1;
BA_ "FlexKomSigStartValue" SG_ 949 VC_BU_PRK_AST_CSO "0300000000000000h";
BA_ "FlexKomSigStartPos" SG_ 949 VC_BU_PRK_AST_CSO 7;
BA_ "FlexKomSigName" SG_ 949 VC_BU_PRK_AST_CSO "VehCfgCSM1_BuPkt";
BA_ "FlexKomSigLaenge" SG_ 949 VC_BU_PRK_AST_CSO 64;
BA_ "FlexKomSID" SG_ 949 VC_BU_PRK_AST_CSO 2008;
BA_ "FlexKomIsMotorola" SG_ 949 VC_BU_PRK_AST_CSO 1;
BA_ "FlexKomComment" SG_ 949 VC_BU_PRK_AST_CSO "Backup for veh config - customer settings menu 1 P";
BA_ "GenSigSNA" SG_ 949 VC_BU_PRK_AST_BRK_CSO "0h";
BA_ "GenSigSendType" SG_ 949 VC_BU_PRK_AST_BRK_CSO 1;
BA_ "FlexKomSigStartValue" SG_ 949 VC_BU_PRK_AST_BRK_CSO "0300000000000000h";
BA_ "FlexKomSigStartPos" SG_ 949 VC_BU_PRK_AST_BRK_CSO 7;
BA_ "FlexKomSigName" SG_ 949 VC_BU_PRK_AST_BRK_CSO "VehCfgCSM1_BuPkt";
BA_ "FlexKomSigLaenge" SG_ 949 VC_BU_PRK_AST_BRK_CSO 64;
BA_ "FlexKomSID" SG_ 949 VC_BU_PRK_AST_BRK_CSO 2008;
BA_ "FlexKomIsMotorola" SG_ 949 VC_BU_PRK_AST_BRK_CSO 1;
BA_ "FlexKomComment" SG_ 949 VC_BU_PRK_AST_BRK_CSO "Backup for veh config - customer settings menu 1 P";
BA_ "GenSigSNA" SG_ 949 VC_BU_PRK_FT_VOL_CSO "0h";
BA_ "GenSigSendType" SG_ 949 VC_BU_PRK_FT_VOL_CSO 1;
BA_ "FlexKomSigStartValue" SG_ 949 VC_BU_PRK_FT_VOL_CSO "0300000000000000h";
BA_ "FlexKomSigStartPos" SG_ 949 VC_BU_PRK_FT_VOL_CSO 7;
BA_ "FlexKomSigName" SG_ 949 VC_BU_PRK_FT_VOL_CSO "VehCfgCSM1_BuPkt";
BA_ "FlexKomSigLaenge" SG_ 949 VC_BU_PRK_FT_VOL_CSO 64;
BA_ "FlexKomSID" SG_ 949 VC_BU_PRK_FT_VOL_CSO 2008;
BA_ "FlexKomIsMotorola" SG_ 949 VC_BU_PRK_FT_VOL_CSO 1;
BA_ "FlexKomComment" SG_ 949 VC_BU_PRK_FT_VOL_CSO "Backup for veh config - customer settings menu 1 P";
BA_ "GenSigSNA" SG_ 949 VC_BU_PRK_RR_VOL_CSO "0h";
BA_ "GenSigSendType" SG_ 949 VC_BU_PRK_RR_VOL_CSO 1;
BA_ "FlexKomSigStartValue" SG_ 949 VC_BU_PRK_RR_VOL_CSO "0300000000000000h";
BA_ "FlexKomSigStartPos" SG_ 949 VC_BU_PRK_RR_VOL_CSO 7;
BA_ "FlexKomSigName" SG_ 949 VC_BU_PRK_RR_VOL_CSO "VehCfgCSM1_BuPkt";
BA_ "FlexKomSigLaenge" SG_ 949 VC_BU_PRK_RR_VOL_CSO 64;
BA_ "FlexKomSID" SG_ 949 VC_BU_PRK_RR_VOL_CSO 2008;
BA_ "FlexKomIsMotorola" SG_ 949 VC_BU_PRK_RR_VOL_CSO 1;
BA_ "FlexKomComment" SG_ 949 VC_BU_PRK_RR_VOL_CSO "Backup for veh config - customer settings menu 1 P";
BA_ "GenSigSNA" SG_ 949 VC_BU_EPS_CSO "0h";
BA_ "GenSigSendType" SG_ 949 VC_BU_EPS_CSO 1;
BA_ "FlexKomSigStartValue" SG_ 949 VC_BU_EPS_CSO "0300000000000000h";
BA_ "FlexKomSigStartPos" SG_ 949 VC_BU_EPS_CSO 7;
BA_ "FlexKomSigName" SG_ 949 VC_BU_EPS_CSO "VehCfgCSM1_BuPkt";
BA_ "FlexKomSigLaenge" SG_ 949 VC_BU_EPS_CSO 64;
BA_ "FlexKomSID" SG_ 949 VC_BU_EPS_CSO 2008;
BA_ "FlexKomIsMotorola" SG_ 949 VC_BU_EPS_CSO 1;
BA_ "FlexKomComment" SG_ 949 VC_BU_EPS_CSO "Backup for veh config - customer settings menu 1 P";
BA_ "GenSigSNA" SG_ 949 VC_BU_FCW_CSO "0h";
BA_ "GenSigSendType" SG_ 949 VC_BU_FCW_CSO 1;
BA_ "FlexKomSigStartValue" SG_ 949 VC_BU_FCW_CSO "0300000000000000h";
BA_ "FlexKomSigStartPos" SG_ 949 VC_BU_FCW_CSO 7;
BA_ "FlexKomSigName" SG_ 949 VC_BU_FCW_CSO "VehCfgCSM1_BuPkt";
BA_ "FlexKomSigLaenge" SG_ 949 VC_BU_FCW_CSO 64;
BA_ "FlexKomSID" SG_ 949 VC_BU_FCW_CSO 2008;
BA_ "FlexKomIsMotorola" SG_ 949 VC_BU_FCW_CSO 1;
BA_ "FlexKomComment" SG_ 949 VC_BU_FCW_CSO "Backup for veh config - customer settings menu 1 P";
BA_ "GenSigSNA" SG_ 949 VC_BU_FCW_BRK_CSO "0h";
BA_ "GenSigSendType" SG_ 949 VC_BU_FCW_BRK_CSO 1;
BA_ "FlexKomSigStartValue" SG_ 949 VC_BU_FCW_BRK_CSO "0300000000000000h";
BA_ "FlexKomSigStartPos" SG_ 949 VC_BU_FCW_BRK_CSO 7;
BA_ "FlexKomSigName" SG_ 949 VC_BU_FCW_BRK_CSO "VehCfgCSM1_BuPkt";
BA_ "FlexKomSigLaenge" SG_ 949 VC_BU_FCW_BRK_CSO 64;
BA_ "FlexKomSID" SG_ 949 VC_BU_FCW_BRK_CSO 2008;
BA_ "FlexKomIsMotorola" SG_ 949 VC_BU_FCW_BRK_CSO 1;
BA_ "FlexKomComment" SG_ 949 VC_BU_FCW_BRK_CSO "Backup for veh config - customer settings menu 1 P";
BA_ "GenSigSNA" SG_ 949 VC_BU_HRN_RMT_LK_CSO "0h";
BA_ "GenSigSendType" SG_ 949 VC_BU_HRN_RMT_LK_CSO 1;
BA_ "FlexKomSigStartValue" SG_ 949 VC_BU_HRN_RMT_LK_CSO "0300000000000000h";
BA_ "FlexKomSigStartPos" SG_ 949 VC_BU_HRN_RMT_LK_CSO 7;
BA_ "FlexKomSigName" SG_ 949 VC_BU_HRN_RMT_LK_CSO "VehCfgCSM1_BuPkt";
BA_ "FlexKomSigLaenge" SG_ 949 VC_BU_HRN_RMT_LK_CSO 64;
BA_ "FlexKomSID" SG_ 949 VC_BU_HRN_RMT_LK_CSO 2008;
BA_ "FlexKomIsMotorola" SG_ 949 VC_BU_HRN_RMT_LK_CSO 1;
BA_ "FlexKomComment" SG_ 949 VC_BU_HRN_RMT_LK_CSO "Backup for veh config - customer settings menu 1 P";
BA_ "GenSigSNA" SG_ 949 VC_BU_HRN_RMT_ST_CSO "0h";
BA_ "GenSigSendType" SG_ 949 VC_BU_HRN_RMT_ST_CSO 1;
BA_ "FlexKomSigStartValue" SG_ 949 VC_BU_HRN_RMT_ST_CSO "0300000000000000h";
BA_ "FlexKomSigStartPos" SG_ 949 VC_BU_HRN_RMT_ST_CSO 7;
BA_ "FlexKomSigName" SG_ 949 VC_BU_HRN_RMT_ST_CSO "VehCfgCSM1_BuPkt";
BA_ "FlexKomSigLaenge" SG_ 949 VC_BU_HRN_RMT_ST_CSO 64;
BA_ "FlexKomSID" SG_ 949 VC_BU_HRN_RMT_ST_CSO 2008;
BA_ "FlexKomIsMotorola" SG_ 949 VC_BU_HRN_RMT_ST_CSO 1;
BA_ "FlexKomComment" SG_ 949 VC_BU_HRN_RMT_ST_CSO "Backup for veh config - customer settings menu 1 P";
BA_ "GenSigSNA" SG_ 949 VC_BU_HRN_RMT_LWR_CSO "0h";
BA_ "GenSigSendType" SG_ 949 VC_BU_HRN_RMT_LWR_CSO 1;
BA_ "FlexKomSigStartValue" SG_ 949 VC_BU_HRN_RMT_LWR_CSO "0300000000000000h";
BA_ "FlexKomSigStartPos" SG_ 949 VC_BU_HRN_RMT_LWR_CSO 7;
BA_ "FlexKomSigName" SG_ 949 VC_BU_HRN_RMT_LWR_CSO "VehCfgCSM1_BuPkt";
BA_ "FlexKomSigLaenge" SG_ 949 VC_BU_HRN_RMT_LWR_CSO 64;
BA_ "FlexKomSID" SG_ 949 VC_BU_HRN_RMT_LWR_CSO 2008;
BA_ "FlexKomIsMotorola" SG_ 949 VC_BU_HRN_RMT_LWR_CSO 1;
BA_ "FlexKomComment" SG_ 949 VC_BU_HRN_RMT_LWR_CSO "Backup for veh config - customer settings menu 1 P";
BA_ "GenSigSNA" SG_ 949 VC_BU_CHMSL_LINE_CSO "0h";
BA_ "GenSigSendType" SG_ 949 VC_BU_CHMSL_LINE_CSO 1;
BA_ "FlexKomSigStartValue" SG_ 949 VC_BU_CHMSL_LINE_CSO "0300000000000000h";
BA_ "FlexKomSigStartPos" SG_ 949 VC_BU_CHMSL_LINE_CSO 7;
BA_ "FlexKomSigName" SG_ 949 VC_BU_CHMSL_LINE_CSO "VehCfgCSM1_BuPkt";
BA_ "FlexKomSigLaenge" SG_ 949 VC_BU_CHMSL_LINE_CSO 64;
BA_ "FlexKomSID" SG_ 949 VC_BU_CHMSL_LINE_CSO 2008;
BA_ "FlexKomIsMotorola" SG_ 949 VC_BU_CHMSL_LINE_CSO 1;
BA_ "FlexKomComment" SG_ 949 VC_BU_CHMSL_LINE_CSO "Backup for veh config - customer settings menu 1 P";
BA_ "GenSigSNA" SG_ 949 VC_BU_DCS_CSO "0h";
BA_ "GenSigSendType" SG_ 949 VC_BU_DCS_CSO 1;
BA_ "FlexKomSigStartValue" SG_ 949 VC_BU_DCS_CSO "0300000000000000h";
BA_ "FlexKomSigStartPos" SG_ 949 VC_BU_DCS_CSO 7;
BA_ "FlexKomSigName" SG_ 949 VC_BU_DCS_CSO "VehCfgCSM1_BuPkt";
BA_ "FlexKomSigLaenge" SG_ 949 VC_BU_DCS_CSO 64;
BA_ "FlexKomSID" SG_ 949 VC_BU_DCS_CSO 2008;
BA_ "FlexKomIsMotorola" SG_ 949 VC_BU_DCS_CSO 1;
BA_ "FlexKomComment" SG_ 949 VC_BU_DCS_CSO "Backup for veh config - customer settings menu 1 P";
BA_ "GenSigSNA" SG_ 949 VC_BU_AUX_SWS_CSO "0h";
BA_ "GenSigSendType" SG_ 949 VC_BU_AUX_SWS_CSO 1;
BA_ "FlexKomSigStartValue" SG_ 949 VC_BU_AUX_SWS_CSO "0300000000000000h";
BA_ "FlexKomSigStartPos" SG_ 949 VC_BU_AUX_SWS_CSO 7;
BA_ "FlexKomSigName" SG_ 949 VC_BU_AUX_SWS_CSO "VehCfgCSM1_BuPkt";
BA_ "FlexKomSigLaenge" SG_ 949 VC_BU_AUX_SWS_CSO 64;
BA_ "FlexKomSID" SG_ 949 VC_BU_AUX_SWS_CSO 2008;
BA_ "FlexKomIsMotorola" SG_ 949 VC_BU_AUX_SWS_CSO 1;
BA_ "FlexKomComment" SG_ 949 VC_BU_AUX_SWS_CSO "Backup for veh config - customer settings menu 1 P";
BA_ "GenSigSNA" SG_ 949 VC_BU_CMRA_GRDLNS_CSO "0h";
BA_ "GenSigSendType" SG_ 949 VC_BU_CMRA_GRDLNS_CSO 1;
BA_ "FlexKomSigStartValue" SG_ 949 VC_BU_CMRA_GRDLNS_CSO "0300000000000000h";
BA_ "FlexKomSigStartPos" SG_ 949 VC_BU_CMRA_GRDLNS_CSO 7;
BA_ "FlexKomSigName" SG_ 949 VC_BU_CMRA_GRDLNS_CSO "VehCfgCSM1_BuPkt";
BA_ "FlexKomSigLaenge" SG_ 949 VC_BU_CMRA_GRDLNS_CSO 64;
BA_ "FlexKomSID" SG_ 949 VC_BU_CMRA_GRDLNS_CSO 2008;
BA_ "FlexKomIsMotorola" SG_ 949 VC_BU_CMRA_GRDLNS_CSO 1;
BA_ "FlexKomComment" SG_ 949 VC_BU_CMRA_GRDLNS_CSO "Backup for veh config - customer settings menu 1 P";
BA_ "GenSigSNA" SG_ 949 VC_BU_UNIT_SET_CSO "0h";
BA_ "GenSigSendType" SG_ 949 VC_BU_UNIT_SET_CSO 1;
BA_ "FlexKomSigStartValue" SG_ 949 VC_BU_UNIT_SET_CSO "0300000000000000h";
BA_ "FlexKomSigStartPos" SG_ 949 VC_BU_UNIT_SET_CSO 7;
BA_ "FlexKomSigName" SG_ 949 VC_BU_UNIT_SET_CSO "VehCfgCSM1_BuPkt";
BA_ "FlexKomSigLaenge" SG_ 949 VC_BU_UNIT_SET_CSO 64;
BA_ "FlexKomSID" SG_ 949 VC_BU_UNIT_SET_CSO 2008;
BA_ "FlexKomIsMotorola" SG_ 949 VC_BU_UNIT_SET_CSO 1;
BA_ "FlexKomComment" SG_ 949 VC_BU_UNIT_SET_CSO "Backup for veh config - customer settings menu 1 P";
BA_ "GenSigSNA" SG_ 949 VC_BU_POLICE_PE_CSO "0h";
BA_ "GenSigSendType" SG_ 949 VC_BU_POLICE_PE_CSO 1;
BA_ "FlexKomSigStartValue" SG_ 949 VC_BU_POLICE_PE_CSO "0300000000000000h";
BA_ "FlexKomSigStartPos" SG_ 949 VC_BU_POLICE_PE_CSO 7;
BA_ "FlexKomSigName" SG_ 949 VC_BU_POLICE_PE_CSO "VehCfgCSM1_BuPkt";
BA_ "FlexKomSigLaenge" SG_ 949 VC_BU_POLICE_PE_CSO 64;
BA_ "FlexKomSID" SG_ 949 VC_BU_POLICE_PE_CSO 2008;
BA_ "FlexKomIsMotorola" SG_ 949 VC_BU_POLICE_PE_CSO 1;
BA_ "FlexKomComment" SG_ 949 VC_BU_POLICE_PE_CSO "Backup for veh config - customer settings menu 1 P";
BA_ "GenSigSNA" SG_ 949 VC_BU_ACC_DLY_CSO "0h";
BA_ "GenSigSendType" SG_ 949 VC_BU_ACC_DLY_CSO 1;
BA_ "FlexKomSigStartValue" SG_ 949 VC_BU_ACC_DLY_CSO "0300000000000000h";
BA_ "FlexKomSigStartPos" SG_ 949 VC_BU_ACC_DLY_CSO 7;
BA_ "FlexKomSigName" SG_ 949 VC_BU_ACC_DLY_CSO "VehCfgCSM1_BuPkt";
BA_ "FlexKomSigLaenge" SG_ 949 VC_BU_ACC_DLY_CSO 64;
BA_ "FlexKomSID" SG_ 949 VC_BU_ACC_DLY_CSO 2008;
BA_ "FlexKomIsMotorola" SG_ 949 VC_BU_ACC_DLY_CSO 1;
BA_ "FlexKomComment" SG_ 949 VC_BU_ACC_DLY_CSO "Backup for veh config - customer settings menu 1 P";
BA_ "GenSigSNA" SG_ 949 VC_BU_AFLS_CSO "0h";
BA_ "GenSigSendType" SG_ 949 VC_BU_AFLS_CSO 1;
BA_ "FlexKomSigStartValue" SG_ 949 VC_BU_AFLS_CSO "0300000000000000h";
BA_ "FlexKomSigStartPos" SG_ 949 VC_BU_AFLS_CSO 7;
BA_ "FlexKomSigName" SG_ 949 VC_BU_AFLS_CSO "VehCfgCSM1_BuPkt";
BA_ "FlexKomSigLaenge" SG_ 949 VC_BU_AFLS_CSO 64;
BA_ "FlexKomSID" SG_ 949 VC_BU_AFLS_CSO 2008;
BA_ "FlexKomIsMotorola" SG_ 949 VC_BU_AFLS_CSO 1;
BA_ "FlexKomComment" SG_ 949 VC_BU_AFLS_CSO "Backup for veh config - customer settings menu 1 P";
BA_ "GenSigSNA" SG_ 949 VC_BU_AMB_DMR_CSO "0h";
BA_ "GenSigSendType" SG_ 949 VC_BU_AMB_DMR_CSO 1;
BA_ "FlexKomSigStartValue" SG_ 949 VC_BU_AMB_DMR_CSO "0300000000000000h";
BA_ "FlexKomSigStartPos" SG_ 949 VC_BU_AMB_DMR_CSO 7;
BA_ "FlexKomSigName" SG_ 949 VC_BU_AMB_DMR_CSO "VehCfgCSM1_BuPkt";
BA_ "FlexKomSigLaenge" SG_ 949 VC_BU_AMB_DMR_CSO 64;
BA_ "FlexKomSID" SG_ 949 VC_BU_AMB_DMR_CSO 2008;
BA_ "FlexKomIsMotorola" SG_ 949 VC_BU_AMB_DMR_CSO 1;
BA_ "FlexKomComment" SG_ 949 VC_BU_AMB_DMR_CSO "Backup for veh config - customer settings menu 1 P";
BA_ "GenSigSNA" SG_ 949 VC_BU_ASCM_TJ_CSO "0h";
BA_ "GenSigSendType" SG_ 949 VC_BU_ASCM_TJ_CSO 1;
BA_ "FlexKomSigStartValue" SG_ 949 VC_BU_ASCM_TJ_CSO "0300000000000000h";
BA_ "FlexKomSigStartPos" SG_ 949 VC_BU_ASCM_TJ_CSO 7;
BA_ "FlexKomSigName" SG_ 949 VC_BU_ASCM_TJ_CSO "VehCfgCSM1_BuPkt";
BA_ "FlexKomSigLaenge" SG_ 949 VC_BU_ASCM_TJ_CSO 64;
BA_ "FlexKomSID" SG_ 949 VC_BU_ASCM_TJ_CSO 2008;
BA_ "FlexKomIsMotorola" SG_ 949 VC_BU_ASCM_TJ_CSO 1;
BA_ "FlexKomComment" SG_ 949 VC_BU_ASCM_TJ_CSO "Backup for veh config - customer settings menu 1 P";
BA_ "GenSigSNA" SG_ 949 VC_BU_ASCM_WRN_CSO "0h";
BA_ "GenSigSendType" SG_ 949 VC_BU_ASCM_WRN_CSO 1;
BA_ "FlexKomSigStartValue" SG_ 949 VC_BU_ASCM_WRN_CSO "0300000000000000h";
BA_ "FlexKomSigStartPos" SG_ 949 VC_BU_ASCM_WRN_CSO 7;
BA_ "FlexKomSigName" SG_ 949 VC_BU_ASCM_WRN_CSO "VehCfgCSM1_BuPkt";
BA_ "FlexKomSigLaenge" SG_ 949 VC_BU_ASCM_WRN_CSO 64;
BA_ "FlexKomSID" SG_ 949 VC_BU_ASCM_WRN_CSO 2008;
BA_ "FlexKomIsMotorola" SG_ 949 VC_BU_ASCM_WRN_CSO 1;
BA_ "FlexKomComment" SG_ 949 VC_BU_ASCM_WRN_CSO "Backup for veh config - customer settings menu 1 P";
BA_ "GenSigSNA" SG_ 949 VC_BU_AUTO_AERO_CSO "0h";
BA_ "GenSigSendType" SG_ 949 VC_BU_AUTO_AERO_CSO 1;
BA_ "FlexKomSigStartValue" SG_ 949 VC_BU_AUTO_AERO_CSO "0300000000000000h";
BA_ "FlexKomSigStartPos" SG_ 949 VC_BU_AUTO_AERO_CSO 7;
BA_ "FlexKomSigName" SG_ 949 VC_BU_AUTO_AERO_CSO "VehCfgCSM1_BuPkt";
BA_ "FlexKomSigLaenge" SG_ 949 VC_BU_AUTO_AERO_CSO 64;
BA_ "FlexKomSID" SG_ 949 VC_BU_AUTO_AERO_CSO 2008;
BA_ "FlexKomIsMotorola" SG_ 949 VC_BU_AUTO_AERO_CSO 1;
BA_ "FlexKomComment" SG_ 949 VC_BU_AUTO_AERO_CSO "Backup for veh config - customer settings menu 1 P";
BA_ "GenSigSNA" SG_ 949 VC_BU_AUTO_HB_CSO "0h";
BA_ "GenSigSendType" SG_ 949 VC_BU_AUTO_HB_CSO 1;
BA_ "FlexKomSigStartValue" SG_ 949 VC_BU_AUTO_HB_CSO "0300000000000000h";
BA_ "FlexKomSigStartPos" SG_ 949 VC_BU_AUTO_HB_CSO 7;
BA_ "FlexKomSigName" SG_ 949 VC_BU_AUTO_HB_CSO "VehCfgCSM1_BuPkt";
BA_ "FlexKomSigLaenge" SG_ 949 VC_BU_AUTO_HB_CSO 64;
BA_ "FlexKomSID" SG_ 949 VC_BU_AUTO_HB_CSO 2008;
BA_ "FlexKomIsMotorola" SG_ 949 VC_BU_AUTO_HB_CSO 1;
BA_ "FlexKomComment" SG_ 949 VC_BU_AUTO_HB_CSO "Backup for veh config - customer settings menu 1 P";
BA_ "GenSigSNA" SG_ 949 VC_BU_AUTO_PRK_CSO "0h";
BA_ "GenSigSendType" SG_ 949 VC_BU_AUTO_PRK_CSO 1;
BA_ "FlexKomSigStartValue" SG_ 949 VC_BU_AUTO_PRK_CSO "0300000000000000h";
BA_ "FlexKomSigStartPos" SG_ 949 VC_BU_AUTO_PRK_CSO 7;
BA_ "FlexKomSigName" SG_ 949 VC_BU_AUTO_PRK_CSO "VehCfgCSM1_BuPkt";
BA_ "FlexKomSigLaenge" SG_ 949 VC_BU_AUTO_PRK_CSO 64;
BA_ "FlexKomSID" SG_ 949 VC_BU_AUTO_PRK_CSO 2008;
BA_ "FlexKomIsMotorola" SG_ 949 VC_BU_AUTO_PRK_CSO 1;
BA_ "FlexKomComment" SG_ 949 VC_BU_AUTO_PRK_CSO "Backup for veh config - customer settings menu 1 P";
BA_ "GenSigSNA" SG_ 949 VC_BU_BLIND_SPOT_CSO "0h";
BA_ "GenSigSendType" SG_ 949 VC_BU_BLIND_SPOT_CSO 1;
BA_ "FlexKomSigStartValue" SG_ 949 VC_BU_BLIND_SPOT_CSO "0300000000000000h";
BA_ "FlexKomSigStartPos" SG_ 949 VC_BU_BLIND_SPOT_CSO 7;
BA_ "FlexKomSigName" SG_ 949 VC_BU_BLIND_SPOT_CSO "VehCfgCSM1_BuPkt";
BA_ "FlexKomSigLaenge" SG_ 949 VC_BU_BLIND_SPOT_CSO 64;
BA_ "FlexKomSID" SG_ 949 VC_BU_BLIND_SPOT_CSO 2008;
BA_ "FlexKomIsMotorola" SG_ 949 VC_BU_BLIND_SPOT_CSO 1;
BA_ "FlexKomComment" SG_ 949 VC_BU_BLIND_SPOT_CSO "Backup for veh config - customer settings menu 1 P";
BA_ "GenSigSNA" SG_ 949 VC_BU_CAPACITY_CSO "0h";
BA_ "GenSigSendType" SG_ 949 VC_BU_CAPACITY_CSO 1;
BA_ "FlexKomSigStartValue" SG_ 949 VC_BU_CAPACITY_CSO "0300000000000000h";
BA_ "FlexKomSigStartPos" SG_ 949 VC_BU_CAPACITY_CSO 7;
BA_ "FlexKomSigName" SG_ 949 VC_BU_CAPACITY_CSO "VehCfgCSM1_BuPkt";
BA_ "FlexKomSigLaenge" SG_ 949 VC_BU_CAPACITY_CSO 64;
BA_ "FlexKomSID" SG_ 949 VC_BU_CAPACITY_CSO 2008;
BA_ "FlexKomIsMotorola" SG_ 949 VC_BU_CAPACITY_CSO 1;
BA_ "FlexKomComment" SG_ 949 VC_BU_CAPACITY_CSO "Backup for veh config - customer settings menu 1 P";
BA_ "GenSigSNA" SG_ 949 VC_BU_CLK_DSP_CSO "0h";
BA_ "GenSigSendType" SG_ 949 VC_BU_CLK_DSP_CSO 1;
BA_ "FlexKomSigStartValue" SG_ 949 VC_BU_CLK_DSP_CSO "0300000000000000h";
BA_ "FlexKomSigStartPos" SG_ 949 VC_BU_CLK_DSP_CSO 7;
BA_ "FlexKomSigName" SG_ 949 VC_BU_CLK_DSP_CSO "VehCfgCSM1_BuPkt";
BA_ "FlexKomSigLaenge" SG_ 949 VC_BU_CLK_DSP_CSO 64;
BA_ "FlexKomSID" SG_ 949 VC_BU_CLK_DSP_CSO 2008;
BA_ "FlexKomIsMotorola" SG_ 949 VC_BU_CLK_DSP_CSO 1;
BA_ "FlexKomComment" SG_ 949 VC_BU_CLK_DSP_CSO "Backup for veh config - customer settings menu 1 P";
BA_ "GenSigSNA" SG_ 949 VC_BU_CMP_CAL_CSO "0h";
BA_ "GenSigSendType" SG_ 949 VC_BU_CMP_CAL_CSO 1;
BA_ "FlexKomSigStartValue" SG_ 949 VC_BU_CMP_CAL_CSO "0300000000000000h";
BA_ "FlexKomSigStartPos" SG_ 949 VC_BU_CMP_CAL_CSO 7;
BA_ "FlexKomSigName" SG_ 949 VC_BU_CMP_CAL_CSO "VehCfgCSM1_BuPkt";
BA_ "FlexKomSigLaenge" SG_ 949 VC_BU_CMP_CAL_CSO 64;
BA_ "FlexKomSID" SG_ 949 VC_BU_CMP_CAL_CSO 2008;
BA_ "FlexKomIsMotorola" SG_ 949 VC_BU_CMP_CAL_CSO 1;
BA_ "FlexKomComment" SG_ 949 VC_BU_CMP_CAL_CSO "Backup for veh config - customer settings menu 1 P";
BA_ "GenSigSNA" SG_ 949 VC_BU_CMP_VAR_CSO "0h";
BA_ "GenSigSendType" SG_ 949 VC_BU_CMP_VAR_CSO 1;
BA_ "FlexKomSigStartValue" SG_ 949 VC_BU_CMP_VAR_CSO "0300000000000000h";
BA_ "FlexKomSigStartPos" SG_ 949 VC_BU_CMP_VAR_CSO 7;
BA_ "FlexKomSigName" SG_ 949 VC_BU_CMP_VAR_CSO "VehCfgCSM1_BuPkt";
BA_ "FlexKomSigLaenge" SG_ 949 VC_BU_CMP_VAR_CSO 64;
BA_ "FlexKomSID" SG_ 949 VC_BU_CMP_VAR_CSO 2008;
BA_ "FlexKomIsMotorola" SG_ 949 VC_BU_CMP_VAR_CSO 1;
BA_ "FlexKomComment" SG_ 949 VC_BU_CMP_VAR_CSO "Backup for veh config - customer settings menu 1 P";
BA_ "GenSigSNA" SG_ 949 VC_BU_CONS_CSO "0h";
BA_ "GenSigSendType" SG_ 949 VC_BU_CONS_CSO 1;
BA_ "FlexKomSigStartValue" SG_ 949 VC_BU_CONS_CSO "0300000000000000h";
BA_ "FlexKomSigStartPos" SG_ 949 VC_BU_CONS_CSO 7;
BA_ "FlexKomSigName" SG_ 949 VC_BU_CONS_CSO "VehCfgCSM1_BuPkt";
BA_ "FlexKomSigLaenge" SG_ 949 VC_BU_CONS_CSO 64;
BA_ "FlexKomSID" SG_ 949 VC_BU_CONS_CSO 2008;
BA_ "FlexKomIsMotorola" SG_ 949 VC_BU_CONS_CSO 1;
BA_ "FlexKomComment" SG_ 949 VC_BU_CONS_CSO "Backup for veh config - customer settings menu 1 P";
BA_ "GenSigSNA" SG_ 949 VC_BU_DISTANCE_CSO "0h";
BA_ "GenSigSendType" SG_ 949 VC_BU_DISTANCE_CSO 1;
BA_ "FlexKomSigStartValue" SG_ 949 VC_BU_DISTANCE_CSO "0300000000000000h";
BA_ "FlexKomSigStartPos" SG_ 949 VC_BU_DISTANCE_CSO 7;
BA_ "FlexKomSigName" SG_ 949 VC_BU_DISTANCE_CSO "VehCfgCSM1_BuPkt";
BA_ "FlexKomSigLaenge" SG_ 949 VC_BU_DISTANCE_CSO 64;
BA_ "FlexKomSID" SG_ 949 VC_BU_DISTANCE_CSO 2008;
BA_ "FlexKomIsMotorola" SG_ 949 VC_BU_DISTANCE_CSO 1;
BA_ "FlexKomComment" SG_ 949 VC_BU_DISTANCE_CSO "Backup for veh config - customer settings menu 1 P";
BA_ "GenSigSNA" SG_ 949 VC_BU_DR_LK_CSO "0h";
BA_ "GenSigSendType" SG_ 949 VC_BU_DR_LK_CSO 1;
BA_ "FlexKomSigStartValue" SG_ 949 VC_BU_DR_LK_CSO "0300000000000000h";
BA_ "FlexKomSigStartPos" SG_ 949 VC_BU_DR_LK_CSO 7;
BA_ "FlexKomSigName" SG_ 949 VC_BU_DR_LK_CSO "VehCfgCSM1_BuPkt";
BA_ "FlexKomSigLaenge" SG_ 949 VC_BU_DR_LK_CSO 64;
BA_ "FlexKomSID" SG_ 949 VC_BU_DR_LK_CSO 2008;
BA_ "FlexKomIsMotorola" SG_ 949 VC_BU_DR_LK_CSO 1;
BA_ "FlexKomComment" SG_ 949 VC_BU_DR_LK_CSO "Backup for veh config - customer settings menu 1 P";
BA_ "GenSigSNA" SG_ 949 VC_BU_DR_UNLK_CSO "0h";
BA_ "GenSigSendType" SG_ 949 VC_BU_DR_UNLK_CSO 1;
BA_ "FlexKomSigStartValue" SG_ 949 VC_BU_DR_UNLK_CSO "0300000000000000h";
BA_ "FlexKomSigStartPos" SG_ 949 VC_BU_DR_UNLK_CSO 7;
BA_ "FlexKomSigName" SG_ 949 VC_BU_DR_UNLK_CSO "VehCfgCSM1_BuPkt";
BA_ "FlexKomSigLaenge" SG_ 949 VC_BU_DR_UNLK_CSO 64;
BA_ "FlexKomSID" SG_ 949 VC_BU_DR_UNLK_CSO 2008;
BA_ "FlexKomIsMotorola" SG_ 949 VC_BU_DR_UNLK_CSO 1;
BA_ "FlexKomComment" SG_ 949 VC_BU_DR_UNLK_CSO "Backup for veh config - customer settings menu 1 P";
BA_ "GenSigSNA" SG_ 949 VC_BU_DRL_CSO "0h";
BA_ "GenSigSendType" SG_ 949 VC_BU_DRL_CSO 1;
BA_ "FlexKomSigStartValue" SG_ 949 VC_BU_DRL_CSO "0300000000000000h";
BA_ "FlexKomSigStartPos" SG_ 949 VC_BU_DRL_CSO 7;
BA_ "FlexKomSigName" SG_ 949 VC_BU_DRL_CSO "VehCfgCSM1_BuPkt";
BA_ "FlexKomSigLaenge" SG_ 949 VC_BU_DRL_CSO 64;
BA_ "FlexKomSID" SG_ 949 VC_BU_DRL_CSO 2008;
BA_ "FlexKomIsMotorola" SG_ 949 VC_BU_DRL_CSO 1;
BA_ "FlexKomComment" SG_ 949 VC_BU_DRL_CSO "Backup for veh config - customer settings menu 1 P";
BA_ "GenSigSNA" SG_ 949 VC_BU_EASY_EXIT_CSO "0h";
BA_ "GenSigSendType" SG_ 949 VC_BU_EASY_EXIT_CSO 1;
BA_ "FlexKomSigStartValue" SG_ 949 VC_BU_EASY_EXIT_CSO "0300000000000000h";
BA_ "FlexKomSigStartPos" SG_ 949 VC_BU_EASY_EXIT_CSO 7;
BA_ "FlexKomSigName" SG_ 949 VC_BU_EASY_EXIT_CSO "VehCfgCSM1_BuPkt";
BA_ "FlexKomSigLaenge" SG_ 949 VC_BU_EASY_EXIT_CSO 64;
BA_ "FlexKomSID" SG_ 949 VC_BU_EASY_EXIT_CSO 2008;
BA_ "FlexKomIsMotorola" SG_ 949 VC_BU_EASY_EXIT_CSO 1;
BA_ "FlexKomComment" SG_ 949 VC_BU_EASY_EXIT_CSO "Backup for veh config - customer settings menu 1 P";
BA_ "GenSigSNA" SG_ 949 VC_BU_ENTRY_EXIT_CSO "0h";
BA_ "GenSigSendType" SG_ 949 VC_BU_ENTRY_EXIT_CSO 1;
BA_ "FlexKomSigStartValue" SG_ 949 VC_BU_ENTRY_EXIT_CSO "0300000000000000h";
BA_ "FlexKomSigStartPos" SG_ 949 VC_BU_ENTRY_EXIT_CSO 7;
BA_ "FlexKomSigName" SG_ 949 VC_BU_ENTRY_EXIT_CSO "VehCfgCSM1_BuPkt";
BA_ "FlexKomSigLaenge" SG_ 949 VC_BU_ENTRY_EXIT_CSO 64;
BA_ "FlexKomSID" SG_ 949 VC_BU_ENTRY_EXIT_CSO 2008;
BA_ "FlexKomIsMotorola" SG_ 949 VC_BU_ENTRY_EXIT_CSO 1;
BA_ "FlexKomComment" SG_ 949 VC_BU_ENTRY_EXIT_CSO "Backup for veh config - customer settings menu 1 P";
BA_ "GenSigSNA" SG_ 949 VC_BU_EPB_SERV_CSO "0h";
BA_ "GenSigSendType" SG_ 949 VC_BU_EPB_SERV_CSO 1;
BA_ "FlexKomSigStartValue" SG_ 949 VC_BU_EPB_SERV_CSO "0300000000000000h";
BA_ "FlexKomSigStartPos" SG_ 949 VC_BU_EPB_SERV_CSO 7;
BA_ "FlexKomSigName" SG_ 949 VC_BU_EPB_SERV_CSO "VehCfgCSM1_BuPkt";
BA_ "FlexKomSigLaenge" SG_ 949 VC_BU_EPB_SERV_CSO 64;
BA_ "FlexKomSID" SG_ 949 VC_BU_EPB_SERV_CSO 2008;
BA_ "FlexKomIsMotorola" SG_ 949 VC_BU_EPB_SERV_CSO 1;
BA_ "FlexKomComment" SG_ 949 VC_BU_EPB_SERV_CSO "Backup for veh config - customer settings menu 1 P";
BA_ "GenSigSNA" SG_ 949 VC_BU_FLSH_LMP_LK_CSO "0h";
BA_ "GenSigSendType" SG_ 949 VC_BU_FLSH_LMP_LK_CSO 1;
BA_ "FlexKomSigStartValue" SG_ 949 VC_BU_FLSH_LMP_LK_CSO "0300000000000000h";
BA_ "FlexKomSigStartPos" SG_ 949 VC_BU_FLSH_LMP_LK_CSO 7;
BA_ "FlexKomSigName" SG_ 949 VC_BU_FLSH_LMP_LK_CSO "VehCfgCSM1_BuPkt";
BA_ "FlexKomSigLaenge" SG_ 949 VC_BU_FLSH_LMP_LK_CSO 64;
BA_ "FlexKomSID" SG_ 949 VC_BU_FLSH_LMP_LK_CSO 2008;
BA_ "FlexKomIsMotorola" SG_ 949 VC_BU_FLSH_LMP_LK_CSO 1;
BA_ "FlexKomComment" SG_ 949 VC_BU_FLSH_LMP_LK_CSO "Backup for veh config - customer settings menu 1 P";
BA_ "GenSigSNA" SG_ 949 VC_BU_HL_DRP_CSO "0h";
BA_ "GenSigSendType" SG_ 949 VC_BU_HL_DRP_CSO 1;
BA_ "FlexKomSigStartValue" SG_ 949 VC_BU_HL_DRP_CSO "0300000000000000h";
BA_ "FlexKomSigStartPos" SG_ 949 VC_BU_HL_DRP_CSO 7;
BA_ "FlexKomSigName" SG_ 949 VC_BU_HL_DRP_CSO "VehCfgCSM1_BuPkt";
BA_ "FlexKomSigLaenge" SG_ 949 VC_BU_HL_DRP_CSO 64;
BA_ "FlexKomSID" SG_ 949 VC_BU_HL_DRP_CSO 2008;
BA_ "FlexKomIsMotorola" SG_ 949 VC_BU_HL_DRP_CSO 1;
BA_ "FlexKomComment" SG_ 949 VC_BU_HL_DRP_CSO "Backup for veh config - customer settings menu 1 P";
BA_ "GenSigSNA" SG_ 949 VC_BU_HL_OFF_DLY_CSO "0h";
BA_ "GenSigSendType" SG_ 949 VC_BU_HL_OFF_DLY_CSO 1;
BA_ "FlexKomSigStartValue" SG_ 949 VC_BU_HL_OFF_DLY_CSO "0300000000000000h";
BA_ "FlexKomSigStartPos" SG_ 949 VC_BU_HL_OFF_DLY_CSO 7;
BA_ "FlexKomSigName" SG_ 949 VC_BU_HL_OFF_DLY_CSO "VehCfgCSM1_BuPkt";
BA_ "FlexKomSigLaenge" SG_ 949 VC_BU_HL_OFF_DLY_CSO 64;
BA_ "FlexKomSID" SG_ 949 VC_BU_HL_OFF_DLY_CSO 2008;
BA_ "FlexKomIsMotorola" SG_ 949 VC_BU_HL_OFF_DLY_CSO 1;
BA_ "FlexKomComment" SG_ 949 VC_BU_HL_OFF_DLY_CSO "Backup for veh config - customer settings menu 1 P";
BA_ "GenSigSNA" SG_ 949 VC_BU_HL_WPR_CSO "0h";
BA_ "GenSigSendType" SG_ 949 VC_BU_HL_WPR_CSO 1;
BA_ "FlexKomSigStartValue" SG_ 949 VC_BU_HL_WPR_CSO "0300000000000000h";
BA_ "FlexKomSigStartPos" SG_ 949 VC_BU_HL_WPR_CSO 7;
BA_ "FlexKomSigName" SG_ 949 VC_BU_HL_WPR_CSO "VehCfgCSM1_BuPkt";
BA_ "FlexKomSigLaenge" SG_ 949 VC_BU_HL_WPR_CSO 64;
BA_ "FlexKomSID" SG_ 949 VC_BU_HL_WPR_CSO 2008;
BA_ "FlexKomIsMotorola" SG_ 949 VC_BU_HL_WPR_CSO 1;
BA_ "FlexKomComment" SG_ 949 VC_BU_HL_WPR_CSO "Backup for veh config - customer settings menu 1 P";
BA_ "GenSigSNA" SG_ 949 VC_BU_HSA_CSO "0h";
BA_ "GenSigSendType" SG_ 949 VC_BU_HSA_CSO 1;
BA_ "FlexKomSigStartValue" SG_ 949 VC_BU_HSA_CSO "0300000000000000h";
BA_ "FlexKomSigStartPos" SG_ 949 VC_BU_HSA_CSO 7;
BA_ "FlexKomSigName" SG_ 949 VC_BU_HSA_CSO "VehCfgCSM1_BuPkt";
BA_ "FlexKomSigLaenge" SG_ 949 VC_BU_HSA_CSO 64;
BA_ "FlexKomSID" SG_ 949 VC_BU_HSA_CSO 2008;
BA_ "FlexKomIsMotorola" SG_ 949 VC_BU_HSA_CSO 1;
BA_ "FlexKomComment" SG_ 949 VC_BU_HSA_CSO "Backup for veh config - customer settings menu 1 P";
BA_ "GenSigSNA" SG_ 949 VC_BU_ILL_APPRCH_CSO "0h";
BA_ "GenSigSendType" SG_ 949 VC_BU_ILL_APPRCH_CSO 1;
BA_ "FlexKomSigStartValue" SG_ 949 VC_BU_ILL_APPRCH_CSO "0300000000000000h";
BA_ "FlexKomSigStartPos" SG_ 949 VC_BU_ILL_APPRCH_CSO 7;
BA_ "FlexKomSigName" SG_ 949 VC_BU_ILL_APPRCH_CSO "VehCfgCSM1_BuPkt";
BA_ "FlexKomSigLaenge" SG_ 949 VC_BU_ILL_APPRCH_CSO 64;
BA_ "FlexKomSID" SG_ 949 VC_BU_ILL_APPRCH_CSO 2008;
BA_ "FlexKomIsMotorola" SG_ 949 VC_BU_ILL_APPRCH_CSO 1;
BA_ "FlexKomComment" SG_ 949 VC_BU_ILL_APPRCH_CSO "Backup for veh config - customer settings menu 1 P";
BA_ "GenSigSNA" SG_ 949 VC_BU_LDW_TRQ_CSO "0h";
BA_ "GenSigSendType" SG_ 949 VC_BU_LDW_TRQ_CSO 1;
BA_ "FlexKomSigStartValue" SG_ 949 VC_BU_LDW_TRQ_CSO "0300000000000000h";
BA_ "FlexKomSigStartPos" SG_ 949 VC_BU_LDW_TRQ_CSO 7;
BA_ "FlexKomSigName" SG_ 949 VC_BU_LDW_TRQ_CSO "VehCfgCSM1_BuPkt";
BA_ "FlexKomSigLaenge" SG_ 949 VC_BU_LDW_TRQ_CSO 64;
BA_ "FlexKomSID" SG_ 949 VC_BU_LDW_TRQ_CSO 2008;
BA_ "FlexKomIsMotorola" SG_ 949 VC_BU_LDW_TRQ_CSO 1;
BA_ "FlexKomComment" SG_ 949 VC_BU_LDW_TRQ_CSO "Backup for veh config - customer settings menu 1 P";
BA_ "GenSigSNA" SG_ 949 VC_BU_LDW_WRN_CSO "0h";
BA_ "GenSigSendType" SG_ 949 VC_BU_LDW_WRN_CSO 1;
BA_ "FlexKomSigStartValue" SG_ 949 VC_BU_LDW_WRN_CSO "0300000000000000h";
BA_ "FlexKomSigStartPos" SG_ 949 VC_BU_LDW_WRN_CSO 7;
BA_ "FlexKomSigName" SG_ 949 VC_BU_LDW_WRN_CSO "VehCfgCSM1_BuPkt";
BA_ "FlexKomSigLaenge" SG_ 949 VC_BU_LDW_WRN_CSO 64;
BA_ "FlexKomSID" SG_ 949 VC_BU_LDW_WRN_CSO 2008;
BA_ "FlexKomIsMotorola" SG_ 949 VC_BU_LDW_WRN_CSO 1;
BA_ "FlexKomComment" SG_ 949 VC_BU_LDW_WRN_CSO "Backup for veh config - customer settings menu 1 P";
BA_ "GenSigSNA" SG_ 949 VC_BU_LGHT_RMT_LWR_CSO "0h";
BA_ "GenSigSendType" SG_ 949 VC_BU_LGHT_RMT_LWR_CSO 1;
BA_ "FlexKomSigStartValue" SG_ 949 VC_BU_LGHT_RMT_LWR_CSO "0300000000000000h";
BA_ "FlexKomSigStartPos" SG_ 949 VC_BU_LGHT_RMT_LWR_CSO 7;
BA_ "FlexKomSigName" SG_ 949 VC_BU_LGHT_RMT_LWR_CSO "VehCfgCSM1_BuPkt";
BA_ "FlexKomSigLaenge" SG_ 949 VC_BU_LGHT_RMT_LWR_CSO 64;
BA_ "FlexKomSID" SG_ 949 VC_BU_LGHT_RMT_LWR_CSO 2008;
BA_ "FlexKomIsMotorola" SG_ 949 VC_BU_LGHT_RMT_LWR_CSO 1;
BA_ "FlexKomComment" SG_ 949 VC_BU_LGHT_RMT_LWR_CSO "Backup for veh config - customer settings menu 1 P";
BA_ "GenSigSNA" SG_ 949 VC_BU_NAV_TRN_CSO "0h";
BA_ "GenSigSendType" SG_ 949 VC_BU_NAV_TRN_CSO 1;
BA_ "FlexKomSigStartValue" SG_ 949 VC_BU_NAV_TRN_CSO "0300000000000000h";
BA_ "FlexKomSigStartPos" SG_ 949 VC_BU_NAV_TRN_CSO 7;
BA_ "FlexKomSigName" SG_ 949 VC_BU_NAV_TRN_CSO "VehCfgCSM1_BuPkt";
BA_ "FlexKomSigLaenge" SG_ 949 VC_BU_NAV_TRN_CSO 64;
BA_ "FlexKomSID" SG_ 949 VC_BU_NAV_TRN_CSO 2008;
BA_ "FlexKomIsMotorola" SG_ 949 VC_BU_NAV_TRN_CSO 1;
BA_ "FlexKomComment" SG_ 949 VC_BU_NAV_TRN_CSO "Backup for veh config - customer settings menu 1 P";
BA_ "GenSigSNA" SG_ 949 VC_BU_PE_CSO "0h";
BA_ "GenSigSendType" SG_ 949 VC_BU_PE_CSO 1;
BA_ "FlexKomSigStartValue" SG_ 949 VC_BU_PE_CSO "0300000000000000h";
BA_ "FlexKomSigStartPos" SG_ 949 VC_BU_PE_CSO 7;
BA_ "FlexKomSigName" SG_ 949 VC_BU_PE_CSO "VehCfgCSM1_BuPkt";
BA_ "FlexKomSigLaenge" SG_ 949 VC_BU_PE_CSO 64;
BA_ "FlexKomSID" SG_ 949 VC_BU_PE_CSO 2008;
BA_ "FlexKomIsMotorola" SG_ 949 VC_BU_PE_CSO 1;
BA_ "FlexKomComment" SG_ 949 VC_BU_PE_CSO "Backup for veh config - customer settings menu 1 P";
BA_ "GenSigSNA" SG_ 949 VC_BU_PER_SHFT_ENBL_CSO "0h";
BA_ "GenSigSendType" SG_ 949 VC_BU_PER_SHFT_ENBL_CSO 1;
BA_ "FlexKomSigStartValue" SG_ 949 VC_BU_PER_SHFT_ENBL_CSO "0300000000000000h";
BA_ "FlexKomSigStartPos" SG_ 949 VC_BU_PER_SHFT_ENBL_CSO 7;
BA_ "FlexKomSigName" SG_ 949 VC_BU_PER_SHFT_ENBL_CSO "VehCfgCSM1_BuPkt";
BA_ "FlexKomSigLaenge" SG_ 949 VC_BU_PER_SHFT_ENBL_CSO 64;
BA_ "FlexKomSID" SG_ 949 VC_BU_PER_SHFT_ENBL_CSO 2008;
BA_ "FlexKomIsMotorola" SG_ 949 VC_BU_PER_SHFT_ENBL_CSO 1;
BA_ "FlexKomComment" SG_ 949 VC_BU_PER_SHFT_ENBL_CSO "Backup for veh config - customer settings menu 1 P";
BA_ "GenSigSNA" SG_ 949 VC_BU_PER_SHFT_RPM_CSO "0h";
BA_ "GenSigSendType" SG_ 949 VC_BU_PER_SHFT_RPM_CSO 1;
BA_ "FlexKomSigStartValue" SG_ 949 VC_BU_PER_SHFT_RPM_CSO "0300000000000000h";
BA_ "FlexKomSigStartPos" SG_ 949 VC_BU_PER_SHFT_RPM_CSO 7;
BA_ "FlexKomSigName" SG_ 949 VC_BU_PER_SHFT_RPM_CSO "VehCfgCSM1_BuPkt";
BA_ "FlexKomSigLaenge" SG_ 949 VC_BU_PER_SHFT_RPM_CSO 64;
BA_ "FlexKomSID" SG_ 949 VC_BU_PER_SHFT_RPM_CSO 2008;
BA_ "FlexKomIsMotorola" SG_ 949 VC_BU_PER_SHFT_RPM_CSO 1;
BA_ "FlexKomComment" SG_ 949 VC_BU_PER_SHFT_RPM_CSO "Backup for veh config - customer settings menu 1 P";
BA_ "GenSigSNA" SG_ 949 VC_BU_PLG_CHM_CSO "0h";
BA_ "GenSigSendType" SG_ 949 VC_BU_PLG_CHM_CSO 1;
BA_ "FlexKomSigStartValue" SG_ 949 VC_BU_PLG_CHM_CSO "0300000000000000h";
BA_ "FlexKomSigStartPos" SG_ 949 VC_BU_PLG_CHM_CSO 7;
BA_ "FlexKomSigName" SG_ 949 VC_BU_PLG_CHM_CSO "VehCfgCSM1_BuPkt";
BA_ "FlexKomSigLaenge" SG_ 949 VC_BU_PLG_CHM_CSO 64;
BA_ "FlexKomSID" SG_ 949 VC_BU_PLG_CHM_CSO 2008;
BA_ "FlexKomIsMotorola" SG_ 949 VC_BU_PLG_CHM_CSO 1;
BA_ "FlexKomComment" SG_ 949 VC_BU_PLG_CHM_CSO "Backup for veh config - customer settings menu 1 P";
BA_ "GenSigSNA" SG_ 949 VC_BU_POWER_CSO "0h";
BA_ "GenSigSendType" SG_ 949 VC_BU_POWER_CSO 1;
BA_ "FlexKomSigStartValue" SG_ 949 VC_BU_POWER_CSO "0300000000000000h";
BA_ "FlexKomSigStartPos" SG_ 949 VC_BU_POWER_CSO 7;
BA_ "FlexKomSigName" SG_ 949 VC_BU_POWER_CSO "VehCfgCSM1_BuPkt";
BA_ "FlexKomSigLaenge" SG_ 949 VC_BU_POWER_CSO 64;
BA_ "FlexKomSID" SG_ 949 VC_BU_POWER_CSO 2008;
BA_ "FlexKomIsMotorola" SG_ 949 VC_BU_POWER_CSO 1;
BA_ "FlexKomComment" SG_ 949 VC_BU_POWER_CSO "Backup for veh config - customer settings menu 1 P";
BA_ "GenSigSNA" SG_ 949 VC_BU_PRESSURE_CSO "0h";
BA_ "GenSigSendType" SG_ 949 VC_BU_PRESSURE_CSO 1;
BA_ "FlexKomSigStartValue" SG_ 949 VC_BU_PRESSURE_CSO "0300000000000000h";
BA_ "FlexKomSigStartPos" SG_ 949 VC_BU_PRESSURE_CSO 7;
BA_ "FlexKomSigName" SG_ 949 VC_BU_PRESSURE_CSO "VehCfgCSM1_BuPkt";
BA_ "FlexKomSigLaenge" SG_ 949 VC_BU_PRESSURE_CSO 64;
BA_ "FlexKomSID" SG_ 949 VC_BU_PRESSURE_CSO 2008;
BA_ "FlexKomIsMotorola" SG_ 949 VC_BU_PRESSURE_CSO 1;
BA_ "FlexKomComment" SG_ 949 VC_BU_PRESSURE_CSO "Backup for veh config - customer settings menu 1 P";
BA_ "GenSigSNA" SG_ 949 VC_BU_PTO_CSO "0h";
BA_ "GenSigSendType" SG_ 949 VC_BU_PTO_CSO 1;
BA_ "FlexKomSigStartValue" SG_ 949 VC_BU_PTO_CSO "0300000000000000h";
BA_ "FlexKomSigStartPos" SG_ 949 VC_BU_PTO_CSO 7;
BA_ "FlexKomSigName" SG_ 949 VC_BU_PTO_CSO "VehCfgCSM1_BuPkt";
BA_ "FlexKomSigLaenge" SG_ 949 VC_BU_PTO_CSO 64;
BA_ "FlexKomSID" SG_ 949 VC_BU_PTO_CSO 2008;
BA_ "FlexKomIsMotorola" SG_ 949 VC_BU_PTO_CSO 1;
BA_ "FlexKomComment" SG_ 949 VC_BU_PTO_CSO "Backup for veh config - customer settings menu 1 P";
BA_ "GenSigSNA" SG_ 949 VC_BU_RAIN_WPR_CSO "0h";
BA_ "GenSigSendType" SG_ 949 VC_BU_RAIN_WPR_CSO 1;
BA_ "FlexKomSigStartValue" SG_ 949 VC_BU_RAIN_WPR_CSO "0300000000000000h";
BA_ "FlexKomSigStartPos" SG_ 949 VC_BU_RAIN_WPR_CSO 7;
BA_ "FlexKomSigName" SG_ 949 VC_BU_RAIN_WPR_CSO "VehCfgCSM1_BuPkt";
BA_ "FlexKomSigLaenge" SG_ 949 VC_BU_RAIN_WPR_CSO 64;
BA_ "FlexKomSID" SG_ 949 VC_BU_RAIN_WPR_CSO 2008;
BA_ "FlexKomIsMotorola" SG_ 949 VC_BU_RAIN_WPR_CSO 1;
BA_ "FlexKomComment" SG_ 949 VC_BU_RAIN_WPR_CSO "Backup for veh config - customer settings menu 1 P";
BA_ "GenSigSNA" SG_ 949 VC_BU_REAR_CMRA_CSO "0h";
BA_ "GenSigSendType" SG_ 949 VC_BU_REAR_CMRA_CSO 1;
BA_ "FlexKomSigStartValue" SG_ 949 VC_BU_REAR_CMRA_CSO "0300000000000000h";
BA_ "FlexKomSigStartPos" SG_ 949 VC_BU_REAR_CMRA_CSO 7;
BA_ "FlexKomSigName" SG_ 949 VC_BU_REAR_CMRA_CSO "VehCfgCSM1_BuPkt";
BA_ "FlexKomSigLaenge" SG_ 949 VC_BU_REAR_CMRA_CSO 64;
BA_ "FlexKomSID" SG_ 949 VC_BU_REAR_CMRA_CSO 2008;
BA_ "FlexKomIsMotorola" SG_ 949 VC_BU_REAR_CMRA_CSO 1;
BA_ "FlexKomComment" SG_ 949 VC_BU_REAR_CMRA_CSO "Backup for veh config - customer settings menu 1 P";
BA_ "GenSigSNA" SG_ 950 VC_BU_HOLD_N_GO_CSO "0h";
BA_ "GenSigSendType" SG_ 950 VC_BU_HOLD_N_GO_CSO 1;
BA_ "FlexKomSigStartValue" SG_ 950 VC_BU_HOLD_N_GO_CSO "0300000000000000h";
BA_ "FlexKomSigStartPos" SG_ 950 VC_BU_HOLD_N_GO_CSO 7;
BA_ "FlexKomSigName" SG_ 950 VC_BU_HOLD_N_GO_CSO "VehCfgCSM2_BuPkt";
BA_ "FlexKomSigLaenge" SG_ 950 VC_BU_HOLD_N_GO_CSO 64;
BA_ "FlexKomSID" SG_ 950 VC_BU_HOLD_N_GO_CSO 2009;
BA_ "FlexKomIsMotorola" SG_ 950 VC_BU_HOLD_N_GO_CSO 1;
BA_ "FlexKomComment" SG_ 950 VC_BU_HOLD_N_GO_CSO "Backup for veh config - customer settings menu 2 p";
BA_ "GenSigSNA" SG_ 950 VC_BU_PADDLE_SHIFT_CSO "0h";
BA_ "GenSigSendType" SG_ 950 VC_BU_PADDLE_SHIFT_CSO 1;
BA_ "FlexKomSigStartValue" SG_ 950 VC_BU_PADDLE_SHIFT_CSO "0300000000000000h";
BA_ "FlexKomSigStartPos" SG_ 950 VC_BU_PADDLE_SHIFT_CSO 7;
BA_ "FlexKomSigName" SG_ 950 VC_BU_PADDLE_SHIFT_CSO "VehCfgCSM2_BuPkt";
BA_ "FlexKomSigLaenge" SG_ 950 VC_BU_PADDLE_SHIFT_CSO 64;
BA_ "FlexKomSID" SG_ 950 VC_BU_PADDLE_SHIFT_CSO 2009;
BA_ "FlexKomIsMotorola" SG_ 950 VC_BU_PADDLE_SHIFT_CSO 1;
BA_ "FlexKomComment" SG_ 950 VC_BU_PADDLE_SHIFT_CSO "Backup for veh config - customer settings menu 2 p";
BA_ "GenSigSNA" SG_ 950 VC_BU_FLSH_LMP_SLDR_CSO "0h";
BA_ "GenSigSendType" SG_ 950 VC_BU_FLSH_LMP_SLDR_CSO 1;
BA_ "FlexKomSigStartValue" SG_ 950 VC_BU_FLSH_LMP_SLDR_CSO "0300000000000000h";
BA_ "FlexKomSigStartPos" SG_ 950 VC_BU_FLSH_LMP_SLDR_CSO 7;
BA_ "FlexKomSigName" SG_ 950 VC_BU_FLSH_LMP_SLDR_CSO "VehCfgCSM2_BuPkt";
BA_ "FlexKomSigLaenge" SG_ 950 VC_BU_FLSH_LMP_SLDR_CSO 64;
BA_ "FlexKomSID" SG_ 950 VC_BU_FLSH_LMP_SLDR_CSO 2009;
BA_ "FlexKomIsMotorola" SG_ 950 VC_BU_FLSH_LMP_SLDR_CSO 1;
BA_ "FlexKomComment" SG_ 950 VC_BU_FLSH_LMP_SLDR_CSO "Backup for veh config - customer settings menu 2 p";
BA_ "GenSigSNA" SG_ 950 VC_BU_SPEED_WARNING_CSO "0h";
BA_ "GenSigSendType" SG_ 950 VC_BU_SPEED_WARNING_CSO 1;
BA_ "FlexKomSigStartValue" SG_ 950 VC_BU_SPEED_WARNING_CSO "0300000000000000h";
BA_ "FlexKomSigStartPos" SG_ 950 VC_BU_SPEED_WARNING_CSO 7;
BA_ "FlexKomSigName" SG_ 950 VC_BU_SPEED_WARNING_CSO "VehCfgCSM2_BuPkt";
BA_ "FlexKomSigLaenge" SG_ 950 VC_BU_SPEED_WARNING_CSO 64;
BA_ "FlexKomSID" SG_ 950 VC_BU_SPEED_WARNING_CSO 2009;
BA_ "FlexKomIsMotorola" SG_ 950 VC_BU_SPEED_WARNING_CSO 1;
BA_ "FlexKomComment" SG_ 950 VC_BU_SPEED_WARNING_CSO "Backup for veh config - customer settings menu 2 p";
BA_ "GenSigSNA" SG_ 950 VC_BU_LDW_ON_CSO "0h";
BA_ "GenSigSendType" SG_ 950 VC_BU_LDW_ON_CSO 1;
BA_ "FlexKomSigStartValue" SG_ 950 VC_BU_LDW_ON_CSO "0300000000000000h";
BA_ "FlexKomSigStartPos" SG_ 950 VC_BU_LDW_ON_CSO 7;
BA_ "FlexKomSigName" SG_ 950 VC_BU_LDW_ON_CSO "VehCfgCSM2_BuPkt";
BA_ "FlexKomSigLaenge" SG_ 950 VC_BU_LDW_ON_CSO 64;
BA_ "FlexKomSID" SG_ 950 VC_BU_LDW_ON_CSO 2009;
BA_ "FlexKomIsMotorola" SG_ 950 VC_BU_LDW_ON_CSO 1;
BA_ "FlexKomComment" SG_ 950 VC_BU_LDW_ON_CSO "Backup for veh config - customer settings menu 2 p";
BA_ "GenSigSNA" SG_ 950 VC_BU_PRK_ASST_TYPE_CSO "0h";
BA_ "GenSigSendType" SG_ 950 VC_BU_PRK_ASST_TYPE_CSO 1;
BA_ "FlexKomSigStartValue" SG_ 950 VC_BU_PRK_ASST_TYPE_CSO "0300000000000000h";
BA_ "FlexKomSigStartPos" SG_ 950 VC_BU_PRK_ASST_TYPE_CSO 7;
BA_ "FlexKomSigName" SG_ 950 VC_BU_PRK_ASST_TYPE_CSO "VehCfgCSM2_BuPkt";
BA_ "FlexKomSigLaenge" SG_ 950 VC_BU_PRK_ASST_TYPE_CSO 64;
BA_ "FlexKomSID" SG_ 950 VC_BU_PRK_ASST_TYPE_CSO 2009;
BA_ "FlexKomIsMotorola" SG_ 950 VC_BU_PRK_ASST_TYPE_CSO 1;
BA_ "FlexKomComment" SG_ 950 VC_BU_PRK_ASST_TYPE_CSO "Backup for veh config - customer settings menu 2 p";
BA_ "GenSigSNA" SG_ 950 VC_BU_EPB_ON_CSO "0h";
BA_ "GenSigSendType" SG_ 950 VC_BU_EPB_ON_CSO 1;
BA_ "FlexKomSigStartValue" SG_ 950 VC_BU_EPB_ON_CSO "0300000000000000h";
BA_ "FlexKomSigStartPos" SG_ 950 VC_BU_EPB_ON_CSO 7;
BA_ "FlexKomSigName" SG_ 950 VC_BU_EPB_ON_CSO "VehCfgCSM2_BuPkt";
BA_ "FlexKomSigLaenge" SG_ 950 VC_BU_EPB_ON_CSO 64;
BA_ "FlexKomSID" SG_ 950 VC_BU_EPB_ON_CSO 2009;
BA_ "FlexKomIsMotorola" SG_ 950 VC_BU_EPB_ON_CSO 1;
BA_ "FlexKomComment" SG_ 950 VC_BU_EPB_ON_CSO "Backup for veh config - customer settings menu 2 p";
BA_ "GenSigSNA" SG_ 950 VC_BU_AIRBAG_ON_CSO "0h";
BA_ "GenSigSendType" SG_ 950 VC_BU_AIRBAG_ON_CSO 1;
BA_ "FlexKomSigStartValue" SG_ 950 VC_BU_AIRBAG_ON_CSO "0300000000000000h";
BA_ "FlexKomSigStartPos" SG_ 950 VC_BU_AIRBAG_ON_CSO 7;
BA_ "FlexKomSigName" SG_ 950 VC_BU_AIRBAG_ON_CSO "VehCfgCSM2_BuPkt";
BA_ "FlexKomSigLaenge" SG_ 950 VC_BU_AIRBAG_ON_CSO 64;
BA_ "FlexKomSID" SG_ 950 VC_BU_AIRBAG_ON_CSO 2009;
BA_ "FlexKomIsMotorola" SG_ 950 VC_BU_AIRBAG_ON_CSO 1;
BA_ "FlexKomComment" SG_ 950 VC_BU_AIRBAG_ON_CSO "Backup for veh config - customer settings menu 2 p";
BA_ "GenSigSNA" SG_ 950 VC_BU_FCW_SW_CSO "0h";
BA_ "GenSigSendType" SG_ 950 VC_BU_FCW_SW_CSO 1;
BA_ "FlexKomSigStartValue" SG_ 950 VC_BU_FCW_SW_CSO "0300000000000000h";
BA_ "FlexKomSigStartPos" SG_ 950 VC_BU_FCW_SW_CSO 7;
BA_ "FlexKomSigName" SG_ 950 VC_BU_FCW_SW_CSO "VehCfgCSM2_BuPkt";
BA_ "FlexKomSigLaenge" SG_ 950 VC_BU_FCW_SW_CSO 64;
BA_ "FlexKomSID" SG_ 950 VC_BU_FCW_SW_CSO 2009;
BA_ "FlexKomIsMotorola" SG_ 950 VC_BU_FCW_SW_CSO 1;
BA_ "FlexKomComment" SG_ 950 VC_BU_FCW_SW_CSO "Backup for veh config - customer settings menu 2 p";
BA_ "GenSigSNA" SG_ 950 VC_BU_FCW_WARN_BRK_CSO "0h";
BA_ "GenSigSendType" SG_ 950 VC_BU_FCW_WARN_BRK_CSO 1;
BA_ "FlexKomSigStartValue" SG_ 950 VC_BU_FCW_WARN_BRK_CSO "0300000000000000h";
BA_ "FlexKomSigStartPos" SG_ 950 VC_BU_FCW_WARN_BRK_CSO 7;
BA_ "FlexKomSigName" SG_ 950 VC_BU_FCW_WARN_BRK_CSO "VehCfgCSM2_BuPkt";
BA_ "FlexKomSigLaenge" SG_ 950 VC_BU_FCW_WARN_BRK_CSO 64;
BA_ "FlexKomSID" SG_ 950 VC_BU_FCW_WARN_BRK_CSO 2009;
BA_ "FlexKomIsMotorola" SG_ 950 VC_BU_FCW_WARN_BRK_CSO 1;
BA_ "FlexKomComment" SG_ 950 VC_BU_FCW_WARN_BRK_CSO "Backup for veh config - customer settings menu 2 p";
BA_ "GenSigSNA" SG_ 950 VC_BU_DOORS_OFF_ACC_DLY_CSO "0h";
BA_ "GenSigSendType" SG_ 950 VC_BU_DOORS_OFF_ACC_DLY_CSO 1;
BA_ "FlexKomSigStartValue" SG_ 950 VC_BU_DOORS_OFF_ACC_DLY_CSO "0300000000000000h";
BA_ "FlexKomSigStartPos" SG_ 950 VC_BU_DOORS_OFF_ACC_DLY_CSO 7;
BA_ "FlexKomSigName" SG_ 950 VC_BU_DOORS_OFF_ACC_DLY_CSO "VehCfgCSM2_BuPkt";
BA_ "FlexKomSigLaenge" SG_ 950 VC_BU_DOORS_OFF_ACC_DLY_CSO 64;
BA_ "FlexKomSID" SG_ 950 VC_BU_DOORS_OFF_ACC_DLY_CSO 2009;
BA_ "FlexKomIsMotorola" SG_ 950 VC_BU_DOORS_OFF_ACC_DLY_CSO 1;
BA_ "FlexKomComment" SG_ 950 VC_BU_DOORS_OFF_ACC_DLY_CSO "Backup for veh config - customer settings menu 2 p";
BA_ "GenSigSNA" SG_ 950 VC_BU_TEEN_PRK_ASST_BRK_CSO "0h";
BA_ "GenSigSendType" SG_ 950 VC_BU_TEEN_PRK_ASST_BRK_CSO 1;
BA_ "FlexKomSigStartValue" SG_ 950 VC_BU_TEEN_PRK_ASST_BRK_CSO "0300000000000000h";
BA_ "FlexKomSigStartPos" SG_ 950 VC_BU_TEEN_PRK_ASST_BRK_CSO 7;
BA_ "FlexKomSigName" SG_ 950 VC_BU_TEEN_PRK_ASST_BRK_CSO "VehCfgCSM2_BuPkt";
BA_ "FlexKomSigLaenge" SG_ 950 VC_BU_TEEN_PRK_ASST_BRK_CSO 64;
BA_ "FlexKomSID" SG_ 950 VC_BU_TEEN_PRK_ASST_BRK_CSO 2009;
BA_ "FlexKomIsMotorola" SG_ 950 VC_BU_TEEN_PRK_ASST_BRK_CSO 1;
BA_ "FlexKomComment" SG_ 950 VC_BU_TEEN_PRK_ASST_BRK_CSO "Backup for veh config - customer settings menu 2 p";
BA_ "GenSigSNA" SG_ 950 VC_BU_PWR_FLD_MRR_CSO "0h";
BA_ "GenSigSendType" SG_ 950 VC_BU_PWR_FLD_MRR_CSO 1;
BA_ "FlexKomSigStartValue" SG_ 950 VC_BU_PWR_FLD_MRR_CSO "0300000000000000h";
BA_ "FlexKomSigStartPos" SG_ 950 VC_BU_PWR_FLD_MRR_CSO 7;
BA_ "FlexKomSigName" SG_ 950 VC_BU_PWR_FLD_MRR_CSO "VehCfgCSM2_BuPkt";
BA_ "FlexKomSigLaenge" SG_ 950 VC_BU_PWR_FLD_MRR_CSO 64;
BA_ "FlexKomSID" SG_ 950 VC_BU_PWR_FLD_MRR_CSO 2009;
BA_ "FlexKomIsMotorola" SG_ 950 VC_BU_PWR_FLD_MRR_CSO 1;
BA_ "FlexKomComment" SG_ 950 VC_BU_PWR_FLD_MRR_CSO "Backup for veh config - customer settings menu 2 p";
BA_ "GenSigSNA" SG_ 950 VC_BU_HANDS_FREE_LFT_CSO "0h";
BA_ "GenSigSendType" SG_ 950 VC_BU_HANDS_FREE_LFT_CSO 1;
BA_ "FlexKomSigStartValue" SG_ 950 VC_BU_HANDS_FREE_LFT_CSO "0300000000000000h";
BA_ "FlexKomSigStartPos" SG_ 950 VC_BU_HANDS_FREE_LFT_CSO 7;
BA_ "FlexKomSigName" SG_ 950 VC_BU_HANDS_FREE_LFT_CSO "VehCfgCSM2_BuPkt";
BA_ "FlexKomSigLaenge" SG_ 950 VC_BU_HANDS_FREE_LFT_CSO 64;
BA_ "FlexKomSID" SG_ 950 VC_BU_HANDS_FREE_LFT_CSO 2009;
BA_ "FlexKomIsMotorola" SG_ 950 VC_BU_HANDS_FREE_LFT_CSO 1;
BA_ "FlexKomComment" SG_ 950 VC_BU_HANDS_FREE_LFT_CSO "Backup for veh config - customer settings menu 2 p";
BA_ "GenSigSNA" SG_ 950 VC_BU_HANDS_FREE_SLDR_CSO "0h";
BA_ "GenSigSendType" SG_ 950 VC_BU_HANDS_FREE_SLDR_CSO 1;
BA_ "FlexKomSigStartValue" SG_ 950 VC_BU_HANDS_FREE_SLDR_CSO "0300000000000000h";
BA_ "FlexKomSigStartPos" SG_ 950 VC_BU_HANDS_FREE_SLDR_CSO 7;
BA_ "FlexKomSigName" SG_ 950 VC_BU_HANDS_FREE_SLDR_CSO "VehCfgCSM2_BuPkt";
BA_ "FlexKomSigLaenge" SG_ 950 VC_BU_HANDS_FREE_SLDR_CSO 64;
BA_ "FlexKomSID" SG_ 950 VC_BU_HANDS_FREE_SLDR_CSO 2009;
BA_ "FlexKomIsMotorola" SG_ 950 VC_BU_HANDS_FREE_SLDR_CSO 1;
BA_ "FlexKomComment" SG_ 950 VC_BU_HANDS_FREE_SLDR_CSO "Backup for veh config - customer settings menu 2 p";
BA_ "GenSigSNA" SG_ 950 VC_BU_SVC_GRIDLINES_CSO "0h";
BA_ "GenSigSendType" SG_ 950 VC_BU_SVC_GRIDLINES_CSO 1;
BA_ "FlexKomSigStartValue" SG_ 950 VC_BU_SVC_GRIDLINES_CSO "0300000000000000h";
BA_ "FlexKomSigStartPos" SG_ 950 VC_BU_SVC_GRIDLINES_CSO 7;
BA_ "FlexKomSigName" SG_ 950 VC_BU_SVC_GRIDLINES_CSO "VehCfgCSM2_BuPkt";
BA_ "FlexKomSigLaenge" SG_ 950 VC_BU_SVC_GRIDLINES_CSO 64;
BA_ "FlexKomSID" SG_ 950 VC_BU_SVC_GRIDLINES_CSO 2009;
BA_ "FlexKomIsMotorola" SG_ 950 VC_BU_SVC_GRIDLINES_CSO 1;
BA_ "FlexKomComment" SG_ 950 VC_BU_SVC_GRIDLINES_CSO "Backup for veh config - customer settings menu 2 p";
BA_ "GenSigSNA" SG_ 950 VC_BU_SVC_DELAY_CSO "0h";
BA_ "GenSigSendType" SG_ 950 VC_BU_SVC_DELAY_CSO 1;
BA_ "FlexKomSigStartValue" SG_ 950 VC_BU_SVC_DELAY_CSO "0300000000000000h";
BA_ "FlexKomSigStartPos" SG_ 950 VC_BU_SVC_DELAY_CSO 7;
BA_ "FlexKomSigName" SG_ 950 VC_BU_SVC_DELAY_CSO "VehCfgCSM2_BuPkt";
BA_ "FlexKomSigLaenge" SG_ 950 VC_BU_SVC_DELAY_CSO 64;
BA_ "FlexKomSID" SG_ 950 VC_BU_SVC_DELAY_CSO 2009;
BA_ "FlexKomIsMotorola" SG_ 950 VC_BU_SVC_DELAY_CSO 1;
BA_ "FlexKomComment" SG_ 950 VC_BU_SVC_DELAY_CSO "Backup for veh config - customer settings menu 2 p";
BA_ "GenSigSNA" SG_ 950 VC_BU_SLD_DR_ALRT_CSO "0h";
BA_ "GenSigSendType" SG_ 950 VC_BU_SLD_DR_ALRT_CSO 1;
BA_ "FlexKomSigStartValue" SG_ 950 VC_BU_SLD_DR_ALRT_CSO "0300000000000000h";
BA_ "FlexKomSigStartPos" SG_ 950 VC_BU_SLD_DR_ALRT_CSO 7;
BA_ "FlexKomSigName" SG_ 950 VC_BU_SLD_DR_ALRT_CSO "VehCfgCSM2_BuPkt";
BA_ "FlexKomSigLaenge" SG_ 950 VC_BU_SLD_DR_ALRT_CSO 64;
BA_ "FlexKomSID" SG_ 950 VC_BU_SLD_DR_ALRT_CSO 2009;
BA_ "FlexKomIsMotorola" SG_ 950 VC_BU_SLD_DR_ALRT_CSO 1;
BA_ "FlexKomComment" SG_ 950 VC_BU_SLD_DR_ALRT_CSO "Backup for veh config - customer settings menu 2 p";
BA_ "GenSigSNA" SG_ 950 VC_BU_TEEN_FCW_SENS_CSO "0h";
BA_ "GenSigSendType" SG_ 950 VC_BU_TEEN_FCW_SENS_CSO 1;
BA_ "FlexKomSigStartValue" SG_ 950 VC_BU_TEEN_FCW_SENS_CSO "0300000000000000h";
BA_ "FlexKomSigStartPos" SG_ 950 VC_BU_TEEN_FCW_SENS_CSO 7;
BA_ "FlexKomSigName" SG_ 950 VC_BU_TEEN_FCW_SENS_CSO "VehCfgCSM2_BuPkt";
BA_ "FlexKomSigLaenge" SG_ 950 VC_BU_TEEN_FCW_SENS_CSO 64;
BA_ "FlexKomSID" SG_ 950 VC_BU_TEEN_FCW_SENS_CSO 2009;
BA_ "FlexKomIsMotorola" SG_ 950 VC_BU_TEEN_FCW_SENS_CSO 1;
BA_ "FlexKomComment" SG_ 950 VC_BU_TEEN_FCW_SENS_CSO "Backup for veh config - customer settings menu 2 p";
BA_ "GenSigSNA" SG_ 950 VC_BU_TEEN_FCW_BRK_CSO "0h";
BA_ "GenSigSendType" SG_ 950 VC_BU_TEEN_FCW_BRK_CSO 1;
BA_ "FlexKomSigStartValue" SG_ 950 VC_BU_TEEN_FCW_BRK_CSO "0300000000000000h";
BA_ "FlexKomSigStartPos" SG_ 950 VC_BU_TEEN_FCW_BRK_CSO 7;
BA_ "FlexKomSigName" SG_ 950 VC_BU_TEEN_FCW_BRK_CSO "VehCfgCSM2_BuPkt";
BA_ "FlexKomSigLaenge" SG_ 950 VC_BU_TEEN_FCW_BRK_CSO 64;
BA_ "FlexKomSID" SG_ 950 VC_BU_TEEN_FCW_BRK_CSO 2009;
BA_ "FlexKomIsMotorola" SG_ 950 VC_BU_TEEN_FCW_BRK_CSO 1;
BA_ "FlexKomComment" SG_ 950 VC_BU_TEEN_FCW_BRK_CSO "Backup for veh config - customer settings menu 2 p";
BA_ "GenSigSNA" SG_ 950 VC_BU_TEEN_PRK_ASST_CSO "0h";
BA_ "GenSigSendType" SG_ 950 VC_BU_TEEN_PRK_ASST_CSO 1;
BA_ "FlexKomSigStartValue" SG_ 950 VC_BU_TEEN_PRK_ASST_CSO "0300000000000000h";
BA_ "FlexKomSigStartPos" SG_ 950 VC_BU_TEEN_PRK_ASST_CSO 7;
BA_ "FlexKomSigName" SG_ 950 VC_BU_TEEN_PRK_ASST_CSO "VehCfgCSM2_BuPkt";
BA_ "FlexKomSigLaenge" SG_ 950 VC_BU_TEEN_PRK_ASST_CSO 64;
BA_ "FlexKomSID" SG_ 950 VC_BU_TEEN_PRK_ASST_CSO 2009;
BA_ "FlexKomIsMotorola" SG_ 950 VC_BU_TEEN_PRK_ASST_CSO 1;
BA_ "FlexKomComment" SG_ 950 VC_BU_TEEN_PRK_ASST_CSO "Backup for veh config - customer settings menu 2 p";
BA_ "GenSigSNA" SG_ 950 VC_BU_TEEN_FT_PRK_VOL_CSO "0h";
BA_ "GenSigSendType" SG_ 950 VC_BU_TEEN_FT_PRK_VOL_CSO 1;
BA_ "FlexKomSigStartValue" SG_ 950 VC_BU_TEEN_FT_PRK_VOL_CSO "0300000000000000h";
BA_ "FlexKomSigStartPos" SG_ 950 VC_BU_TEEN_FT_PRK_VOL_CSO 7;
BA_ "FlexKomSigName" SG_ 950 VC_BU_TEEN_FT_PRK_VOL_CSO "VehCfgCSM2_BuPkt";
BA_ "FlexKomSigLaenge" SG_ 950 VC_BU_TEEN_FT_PRK_VOL_CSO 64;
BA_ "FlexKomSID" SG_ 950 VC_BU_TEEN_FT_PRK_VOL_CSO 2009;
BA_ "FlexKomIsMotorola" SG_ 950 VC_BU_TEEN_FT_PRK_VOL_CSO 1;
BA_ "FlexKomComment" SG_ 950 VC_BU_TEEN_FT_PRK_VOL_CSO "Backup for veh config - customer settings menu 2 p";
BA_ "GenSigSNA" SG_ 950 VC_BU_TEEN_RR_PRK_VOL_CSO "0h";
BA_ "GenSigSendType" SG_ 950 VC_BU_TEEN_RR_PRK_VOL_CSO 1;
BA_ "FlexKomSigStartValue" SG_ 950 VC_BU_TEEN_RR_PRK_VOL_CSO "0300000000000000h";
BA_ "FlexKomSigStartPos" SG_ 950 VC_BU_TEEN_RR_PRK_VOL_CSO 7;
BA_ "FlexKomSigName" SG_ 950 VC_BU_TEEN_RR_PRK_VOL_CSO "VehCfgCSM2_BuPkt";
BA_ "FlexKomSigLaenge" SG_ 950 VC_BU_TEEN_RR_PRK_VOL_CSO 64;
BA_ "FlexKomSID" SG_ 950 VC_BU_TEEN_RR_PRK_VOL_CSO 2009;
BA_ "FlexKomIsMotorola" SG_ 950 VC_BU_TEEN_RR_PRK_VOL_CSO 1;
BA_ "FlexKomComment" SG_ 950 VC_BU_TEEN_RR_PRK_VOL_CSO "Backup for veh config - customer settings menu 2 p";
BA_ "GenSigSNA" SG_ 950 VC_BU_TEEN_MAX_SPEED_CSO "0h";
BA_ "GenSigSendType" SG_ 950 VC_BU_TEEN_MAX_SPEED_CSO 1;
BA_ "FlexKomSigStartValue" SG_ 950 VC_BU_TEEN_MAX_SPEED_CSO "0300000000000000h";
BA_ "FlexKomSigStartPos" SG_ 950 VC_BU_TEEN_MAX_SPEED_CSO 7;
BA_ "FlexKomSigName" SG_ 950 VC_BU_TEEN_MAX_SPEED_CSO "VehCfgCSM2_BuPkt";
BA_ "FlexKomSigLaenge" SG_ 950 VC_BU_TEEN_MAX_SPEED_CSO 64;
BA_ "FlexKomSID" SG_ 950 VC_BU_TEEN_MAX_SPEED_CSO 2009;
BA_ "FlexKomIsMotorola" SG_ 950 VC_BU_TEEN_MAX_SPEED_CSO 1;
BA_ "FlexKomComment" SG_ 950 VC_BU_TEEN_MAX_SPEED_CSO "Backup for veh config - customer settings menu 2 p";
BA_ "GenSigSNA" SG_ 950 VC_BU_TEEN_FUEL_WRN_CSO "0h";
BA_ "GenSigSendType" SG_ 950 VC_BU_TEEN_FUEL_WRN_CSO 1;
BA_ "FlexKomSigStartValue" SG_ 950 VC_BU_TEEN_FUEL_WRN_CSO "0300000000000000h";
BA_ "FlexKomSigStartPos" SG_ 950 VC_BU_TEEN_FUEL_WRN_CSO 7;
BA_ "FlexKomSigName" SG_ 950 VC_BU_TEEN_FUEL_WRN_CSO "VehCfgCSM2_BuPkt";
BA_ "FlexKomSigLaenge" SG_ 950 VC_BU_TEEN_FUEL_WRN_CSO 64;
BA_ "FlexKomSID" SG_ 950 VC_BU_TEEN_FUEL_WRN_CSO 2009;
BA_ "FlexKomIsMotorola" SG_ 950 VC_BU_TEEN_FUEL_WRN_CSO 1;
BA_ "FlexKomComment" SG_ 950 VC_BU_TEEN_FUEL_WRN_CSO "Backup for veh config - customer settings menu 2 p";
BA_ "GenSigSNA" SG_ 950 VC_BU_TEEN_FUEL_POPUP_CSO "0h";
BA_ "GenSigSendType" SG_ 950 VC_BU_TEEN_FUEL_POPUP_CSO 1;
BA_ "FlexKomSigStartValue" SG_ 950 VC_BU_TEEN_FUEL_POPUP_CSO "0300000000000000h";
BA_ "FlexKomSigStartPos" SG_ 950 VC_BU_TEEN_FUEL_POPUP_CSO 7;
BA_ "FlexKomSigName" SG_ 950 VC_BU_TEEN_FUEL_POPUP_CSO "VehCfgCSM2_BuPkt";
BA_ "FlexKomSigLaenge" SG_ 950 VC_BU_TEEN_FUEL_POPUP_CSO 64;
BA_ "FlexKomSID" SG_ 950 VC_BU_TEEN_FUEL_POPUP_CSO 2009;
BA_ "FlexKomIsMotorola" SG_ 950 VC_BU_TEEN_FUEL_POPUP_CSO 1;
BA_ "FlexKomComment" SG_ 950 VC_BU_TEEN_FUEL_POPUP_CSO "Backup for veh config - customer settings menu 2 p";
BA_ "GenSigSNA" SG_ 950 VC_BU_TEEN_BLIND_SPOT_CSO "0h";
BA_ "GenSigSendType" SG_ 950 VC_BU_TEEN_BLIND_SPOT_CSO 1;
BA_ "FlexKomSigStartValue" SG_ 950 VC_BU_TEEN_BLIND_SPOT_CSO "0300000000000000h";
BA_ "FlexKomSigStartPos" SG_ 950 VC_BU_TEEN_BLIND_SPOT_CSO 7;
BA_ "FlexKomSigName" SG_ 950 VC_BU_TEEN_BLIND_SPOT_CSO "VehCfgCSM2_BuPkt";
BA_ "FlexKomSigLaenge" SG_ 950 VC_BU_TEEN_BLIND_SPOT_CSO 64;
BA_ "FlexKomSID" SG_ 950 VC_BU_TEEN_BLIND_SPOT_CSO 2009;
BA_ "FlexKomIsMotorola" SG_ 950 VC_BU_TEEN_BLIND_SPOT_CSO 1;
BA_ "FlexKomComment" SG_ 950 VC_BU_TEEN_BLIND_SPOT_CSO "Backup for veh config - customer settings menu 2 p";
BA_ "GenSigSNA" SG_ 950 VC_BU_TEEN_RAIN_WPR_CSO "0h";
BA_ "GenSigSendType" SG_ 950 VC_BU_TEEN_RAIN_WPR_CSO 1;
BA_ "FlexKomSigStartValue" SG_ 950 VC_BU_TEEN_RAIN_WPR_CSO "0300000000000000h";
BA_ "FlexKomSigStartPos" SG_ 950 VC_BU_TEEN_RAIN_WPR_CSO 7;
BA_ "FlexKomSigName" SG_ 950 VC_BU_TEEN_RAIN_WPR_CSO "VehCfgCSM2_BuPkt";
BA_ "FlexKomSigLaenge" SG_ 950 VC_BU_TEEN_RAIN_WPR_CSO 64;
BA_ "FlexKomSID" SG_ 950 VC_BU_TEEN_RAIN_WPR_CSO 2009;
BA_ "FlexKomIsMotorola" SG_ 950 VC_BU_TEEN_RAIN_WPR_CSO 1;
BA_ "FlexKomComment" SG_ 950 VC_BU_TEEN_RAIN_WPR_CSO "Backup for veh config - customer settings menu 2 p";
BA_ "GenSigSNA" SG_ 950 VC_BU_TEEN_AUTO_HB_CSO "0h";
BA_ "GenSigSendType" SG_ 950 VC_BU_TEEN_AUTO_HB_CSO 1;
BA_ "FlexKomSigStartValue" SG_ 950 VC_BU_TEEN_AUTO_HB_CSO "0300000000000000h";
BA_ "FlexKomSigStartPos" SG_ 950 VC_BU_TEEN_AUTO_HB_CSO 7;
BA_ "FlexKomSigName" SG_ 950 VC_BU_TEEN_AUTO_HB_CSO "VehCfgCSM2_BuPkt";
BA_ "FlexKomSigLaenge" SG_ 950 VC_BU_TEEN_AUTO_HB_CSO 64;
BA_ "FlexKomSID" SG_ 950 VC_BU_TEEN_AUTO_HB_CSO 2009;
BA_ "FlexKomIsMotorola" SG_ 950 VC_BU_TEEN_AUTO_HB_CSO 1;
BA_ "FlexKomComment" SG_ 950 VC_BU_TEEN_AUTO_HB_CSO "Backup for veh config - customer settings menu 2 p";
BA_ "GenSigSNA" SG_ 950 VC_BU_TEEN_LGHT_WPR_CSO "0h";
BA_ "GenSigSendType" SG_ 950 VC_BU_TEEN_LGHT_WPR_CSO 1;
BA_ "FlexKomSigStartValue" SG_ 950 VC_BU_TEEN_LGHT_WPR_CSO "0300000000000000h";
BA_ "FlexKomSigStartPos" SG_ 950 VC_BU_TEEN_LGHT_WPR_CSO 7;
BA_ "FlexKomSigName" SG_ 950 VC_BU_TEEN_LGHT_WPR_CSO "VehCfgCSM2_BuPkt";
BA_ "FlexKomSigLaenge" SG_ 950 VC_BU_TEEN_LGHT_WPR_CSO 64;
BA_ "FlexKomSID" SG_ 950 VC_BU_TEEN_LGHT_WPR_CSO 2009;
BA_ "FlexKomIsMotorola" SG_ 950 VC_BU_TEEN_LGHT_WPR_CSO 1;
BA_ "FlexKomComment" SG_ 950 VC_BU_TEEN_LGHT_WPR_CSO "Backup for veh config - customer settings menu 2 p";
BA_ "GenSigSNA" SG_ 950 VC_BU_TEEN_SLD_DR_ALRT_CSO "0h";
BA_ "GenSigSendType" SG_ 950 VC_BU_TEEN_SLD_DR_ALRT_CSO 1;
BA_ "FlexKomSigStartValue" SG_ 950 VC_BU_TEEN_SLD_DR_ALRT_CSO "0300000000000000h";
BA_ "FlexKomSigStartPos" SG_ 950 VC_BU_TEEN_SLD_DR_ALRT_CSO 7;
BA_ "FlexKomSigName" SG_ 950 VC_BU_TEEN_SLD_DR_ALRT_CSO "VehCfgCSM2_BuPkt";
BA_ "FlexKomSigLaenge" SG_ 950 VC_BU_TEEN_SLD_DR_ALRT_CSO 64;
BA_ "FlexKomSID" SG_ 950 VC_BU_TEEN_SLD_DR_ALRT_CSO 2009;
BA_ "FlexKomIsMotorola" SG_ 950 VC_BU_TEEN_SLD_DR_ALRT_CSO 1;
BA_ "FlexKomComment" SG_ 950 VC_BU_TEEN_SLD_DR_ALRT_CSO "Backup for veh config - customer settings menu 2 p";
BA_ "GenSigSNA" SG_ 950 VC_BU_TEEN_PLG_CHIME_CSO "0h";
BA_ "GenSigSendType" SG_ 950 VC_BU_TEEN_PLG_CHIME_CSO 1;
BA_ "FlexKomSigStartValue" SG_ 950 VC_BU_TEEN_PLG_CHIME_CSO "0300000000000000h";
BA_ "FlexKomSigStartPos" SG_ 950 VC_BU_TEEN_PLG_CHIME_CSO 7;
BA_ "FlexKomSigName" SG_ 950 VC_BU_TEEN_PLG_CHIME_CSO "VehCfgCSM2_BuPkt";
BA_ "FlexKomSigLaenge" SG_ 950 VC_BU_TEEN_PLG_CHIME_CSO 64;
BA_ "FlexKomSID" SG_ 950 VC_BU_TEEN_PLG_CHIME_CSO 2009;
BA_ "FlexKomIsMotorola" SG_ 950 VC_BU_TEEN_PLG_CHIME_CSO 1;
BA_ "FlexKomComment" SG_ 950 VC_BU_TEEN_PLG_CHIME_CSO "Backup for veh config - customer settings menu 2 p";
BA_ "GenSigSNA" SG_ 950 VC_BU_SLD_DR_CHM_CSO "0h";
BA_ "GenSigSendType" SG_ 950 VC_BU_SLD_DR_CHM_CSO 1;
BA_ "FlexKomSigStartValue" SG_ 950 VC_BU_SLD_DR_CHM_CSO "0300000000000000h";
BA_ "FlexKomSigStartPos" SG_ 950 VC_BU_SLD_DR_CHM_CSO 7;
BA_ "FlexKomSigName" SG_ 950 VC_BU_SLD_DR_CHM_CSO "VehCfgCSM2_BuPkt";
BA_ "FlexKomSigLaenge" SG_ 950 VC_BU_SLD_DR_CHM_CSO 64;
BA_ "FlexKomSID" SG_ 950 VC_BU_SLD_DR_CHM_CSO 2009;
BA_ "FlexKomIsMotorola" SG_ 950 VC_BU_SLD_DR_CHM_CSO 1;
BA_ "FlexKomComment" SG_ 950 VC_BU_SLD_DR_CHM_CSO "Backup for veh config - customer settings menu 2 p";
BA_ "GenSigSNA" SG_ 950 VC_BU_TEEN_SLD_DR_CHM_CSO "0h";
BA_ "GenSigSendType" SG_ 950 VC_BU_TEEN_SLD_DR_CHM_CSO 1;
BA_ "FlexKomSigStartValue" SG_ 950 VC_BU_TEEN_SLD_DR_CHM_CSO "0300000000000000h";
BA_ "FlexKomSigStartPos" SG_ 950 VC_BU_TEEN_SLD_DR_CHM_CSO 7;
BA_ "FlexKomSigName" SG_ 950 VC_BU_TEEN_SLD_DR_CHM_CSO "VehCfgCSM2_BuPkt";
BA_ "FlexKomSigLaenge" SG_ 950 VC_BU_TEEN_SLD_DR_CHM_CSO 64;
BA_ "FlexKomSID" SG_ 950 VC_BU_TEEN_SLD_DR_CHM_CSO 2009;
BA_ "FlexKomIsMotorola" SG_ 950 VC_BU_TEEN_SLD_DR_CHM_CSO 1;
BA_ "FlexKomComment" SG_ 950 VC_BU_TEEN_SLD_DR_CHM_CSO "Backup for veh config - customer settings menu 2 p";
BA_ "GenSigSNA" SG_ 950 VC_BU_PCS_CSO "0h";
BA_ "GenSigSendType" SG_ 950 VC_BU_PCS_CSO 1;
BA_ "FlexKomSigStartValue" SG_ 950 VC_BU_PCS_CSO "0300000000000000h";
BA_ "FlexKomSigStartPos" SG_ 950 VC_BU_PCS_CSO 7;
BA_ "FlexKomSigName" SG_ 950 VC_BU_PCS_CSO "VehCfgCSM2_BuPkt";
BA_ "FlexKomSigLaenge" SG_ 950 VC_BU_PCS_CSO 64;
BA_ "FlexKomSID" SG_ 950 VC_BU_PCS_CSO 2009;
BA_ "FlexKomIsMotorola" SG_ 950 VC_BU_PCS_CSO 1;
BA_ "FlexKomComment" SG_ 950 VC_BU_PCS_CSO "Backup for veh config - customer settings menu 2 p";
BA_ "GenSigSNA" SG_ 950 VC_BU_BSM_TRLR_CSO "0h";
BA_ "GenSigSendType" SG_ 950 VC_BU_BSM_TRLR_CSO 1;
BA_ "FlexKomSigStartValue" SG_ 950 VC_BU_BSM_TRLR_CSO "0300000000000000h";
BA_ "FlexKomSigStartPos" SG_ 950 VC_BU_BSM_TRLR_CSO 7;
BA_ "FlexKomSigName" SG_ 950 VC_BU_BSM_TRLR_CSO "VehCfgCSM2_BuPkt";
BA_ "FlexKomSigLaenge" SG_ 950 VC_BU_BSM_TRLR_CSO 64;
BA_ "FlexKomSID" SG_ 950 VC_BU_BSM_TRLR_CSO 2009;
BA_ "FlexKomIsMotorola" SG_ 950 VC_BU_BSM_TRLR_CSO 1;
BA_ "FlexKomComment" SG_ 950 VC_BU_BSM_TRLR_CSO "Backup for veh config - customer settings menu 2 p";
BA_ "GenSigSNA" SG_ 950 VC_BU_AUTO_SS_CSO "0h";
BA_ "GenSigSendType" SG_ 950 VC_BU_AUTO_SS_CSO 1;
BA_ "FlexKomSigStartValue" SG_ 950 VC_BU_AUTO_SS_CSO "0300000000000000h";
BA_ "FlexKomSigStartPos" SG_ 950 VC_BU_AUTO_SS_CSO 7;
BA_ "FlexKomSigName" SG_ 950 VC_BU_AUTO_SS_CSO "VehCfgCSM2_BuPkt";
BA_ "FlexKomSigLaenge" SG_ 950 VC_BU_AUTO_SS_CSO 64;
BA_ "FlexKomSID" SG_ 950 VC_BU_AUTO_SS_CSO 2009;
BA_ "FlexKomIsMotorola" SG_ 950 VC_BU_AUTO_SS_CSO 1;
BA_ "FlexKomComment" SG_ 950 VC_BU_AUTO_SS_CSO "Backup for veh config - customer settings menu 2 p";
BA_ "GenSigSNA" SG_ 950 VC_BU_RDY_DRV_CSO "0h";
BA_ "GenSigSendType" SG_ 950 VC_BU_RDY_DRV_CSO 1;
BA_ "FlexKomSigStartValue" SG_ 950 VC_BU_RDY_DRV_CSO "0300000000000000h";
BA_ "FlexKomSigStartPos" SG_ 950 VC_BU_RDY_DRV_CSO 7;
BA_ "FlexKomSigName" SG_ 950 VC_BU_RDY_DRV_CSO "VehCfgCSM2_BuPkt";
BA_ "FlexKomSigLaenge" SG_ 950 VC_BU_RDY_DRV_CSO 64;
BA_ "FlexKomSID" SG_ 950 VC_BU_RDY_DRV_CSO 2009;
BA_ "FlexKomIsMotorola" SG_ 950 VC_BU_RDY_DRV_CSO 1;
BA_ "FlexKomComment" SG_ 950 VC_BU_RDY_DRV_CSO "Backup for veh config - customer settings menu 2 p";
BA_ "GenSigStartValue" SG_ 950 VC_BU_VehCfgCSO2_Stat 3;
BA_ "GenSigSNA" SG_ 950 VC_BU_VehCfgCSO2_Stat "3h";
BA_ "GenSigSendType" SG_ 950 VC_BU_VehCfgCSO2_Stat 1;
BA_ "FlexKomSigStartValue" SG_ 950 VC_BU_VehCfgCSO2_Stat "0300000000000000h";
BA_ "FlexKomSigStartPos" SG_ 950 VC_BU_VehCfgCSO2_Stat 7;
BA_ "FlexKomSigName" SG_ 950 VC_BU_VehCfgCSO2_Stat "VehCfgCSM2_BuPkt";
BA_ "FlexKomSigLaenge" SG_ 950 VC_BU_VehCfgCSO2_Stat 64;
BA_ "FlexKomSID" SG_ 950 VC_BU_VehCfgCSO2_Stat 2009;
BA_ "FlexKomIsMotorola" SG_ 950 VC_BU_VehCfgCSO2_Stat 1;
BA_ "FlexKomComment" SG_ 950 VC_BU_VehCfgCSO2_Stat "Backup for veh config - customer settings menu 2 p";
BA_ "GenSigSNA" SG_ 950 VC_BU_REAR_CMRA_DLY_CSO "0h";
BA_ "GenSigSendType" SG_ 950 VC_BU_REAR_CMRA_DLY_CSO 1;
BA_ "FlexKomSigStartValue" SG_ 950 VC_BU_REAR_CMRA_DLY_CSO "0300000000000000h";
BA_ "FlexKomSigStartPos" SG_ 950 VC_BU_REAR_CMRA_DLY_CSO 7;
BA_ "FlexKomSigName" SG_ 950 VC_BU_REAR_CMRA_DLY_CSO "VehCfgCSM2_BuPkt";
BA_ "FlexKomSigLaenge" SG_ 950 VC_BU_REAR_CMRA_DLY_CSO 64;
BA_ "FlexKomSID" SG_ 950 VC_BU_REAR_CMRA_DLY_CSO 2009;
BA_ "FlexKomIsMotorola" SG_ 950 VC_BU_REAR_CMRA_DLY_CSO 1;
BA_ "FlexKomComment" SG_ 950 VC_BU_REAR_CMRA_DLY_CSO "Backup for veh config - customer settings menu 2 p";
BA_ "GenSigSNA" SG_ 950 VC_BU_RKE_MEM_CSO "0h";
BA_ "GenSigSendType" SG_ 950 VC_BU_RKE_MEM_CSO 1;
BA_ "FlexKomSigStartValue" SG_ 950 VC_BU_RKE_MEM_CSO "0300000000000000h";
BA_ "FlexKomSigStartPos" SG_ 950 VC_BU_RKE_MEM_CSO 7;
BA_ "FlexKomSigName" SG_ 950 VC_BU_RKE_MEM_CSO "VehCfgCSM2_BuPkt";
BA_ "FlexKomSigLaenge" SG_ 950 VC_BU_RKE_MEM_CSO 64;
BA_ "FlexKomSID" SG_ 950 VC_BU_RKE_MEM_CSO 2009;
BA_ "FlexKomIsMotorola" SG_ 950 VC_BU_RKE_MEM_CSO 1;
BA_ "FlexKomComment" SG_ 950 VC_BU_RKE_MEM_CSO "Backup for veh config - customer settings menu 2 p";
BA_ "GenSigSNA" SG_ 950 VC_BU_RKE_UNLK_CSO "0h";
BA_ "GenSigSendType" SG_ 950 VC_BU_RKE_UNLK_CSO 1;
BA_ "FlexKomSigStartValue" SG_ 950 VC_BU_RKE_UNLK_CSO "0300000000000000h";
BA_ "FlexKomSigStartPos" SG_ 950 VC_BU_RKE_UNLK_CSO 7;
BA_ "FlexKomSigName" SG_ 950 VC_BU_RKE_UNLK_CSO "VehCfgCSM2_BuPkt";
BA_ "FlexKomSigLaenge" SG_ 950 VC_BU_RKE_UNLK_CSO 64;
BA_ "FlexKomSID" SG_ 950 VC_BU_RKE_UNLK_CSO 2009;
BA_ "FlexKomIsMotorola" SG_ 950 VC_BU_RKE_UNLK_CSO 1;
BA_ "FlexKomComment" SG_ 950 VC_BU_RKE_UNLK_CSO "Backup for veh config - customer settings menu 2 p";
BA_ "GenSigSNA" SG_ 950 VC_BU_SPEED_CSO "0h";
BA_ "GenSigSendType" SG_ 950 VC_BU_SPEED_CSO 1;
BA_ "FlexKomSigStartValue" SG_ 950 VC_BU_SPEED_CSO "0300000000000000h";
BA_ "FlexKomSigStartPos" SG_ 950 VC_BU_SPEED_CSO 7;
BA_ "FlexKomSigName" SG_ 950 VC_BU_SPEED_CSO "VehCfgCSM2_BuPkt";
BA_ "FlexKomSigLaenge" SG_ 950 VC_BU_SPEED_CSO 64;
BA_ "FlexKomSID" SG_ 950 VC_BU_SPEED_CSO 2009;
BA_ "FlexKomIsMotorola" SG_ 950 VC_BU_SPEED_CSO 1;
BA_ "FlexKomComment" SG_ 950 VC_BU_SPEED_CSO "Backup for veh config - customer settings menu 2 p";
BA_ "GenSigSNA" SG_ 950 VC_BU_TLT_MRR_CSO "0h";
BA_ "GenSigSendType" SG_ 950 VC_BU_TLT_MRR_CSO 1;
BA_ "FlexKomSigStartValue" SG_ 950 VC_BU_TLT_MRR_CSO "0300000000000000h";
BA_ "FlexKomSigStartPos" SG_ 950 VC_BU_TLT_MRR_CSO 7;
BA_ "FlexKomSigName" SG_ 950 VC_BU_TLT_MRR_CSO "VehCfgCSM2_BuPkt";
BA_ "FlexKomSigLaenge" SG_ 950 VC_BU_TLT_MRR_CSO 64;
BA_ "FlexKomSID" SG_ 950 VC_BU_TLT_MRR_CSO 2009;
BA_ "FlexKomIsMotorola" SG_ 950 VC_BU_TLT_MRR_CSO 1;
BA_ "FlexKomComment" SG_ 950 VC_BU_TLT_MRR_CSO "Backup for veh config - customer settings menu 2 p";
BA_ "GenSigSNA" SG_ 950 VC_BU_TORQUE_CSO "0h";
BA_ "GenSigSendType" SG_ 950 VC_BU_TORQUE_CSO 1;
BA_ "FlexKomSigStartValue" SG_ 950 VC_BU_TORQUE_CSO "0300000000000000h";
BA_ "FlexKomSigStartPos" SG_ 950 VC_BU_TORQUE_CSO 7;
BA_ "FlexKomSigName" SG_ 950 VC_BU_TORQUE_CSO "VehCfgCSM2_BuPkt";
BA_ "FlexKomSigLaenge" SG_ 950 VC_BU_TORQUE_CSO 64;
BA_ "FlexKomSID" SG_ 950 VC_BU_TORQUE_CSO 2009;
BA_ "FlexKomIsMotorola" SG_ 950 VC_BU_TORQUE_CSO 1;
BA_ "FlexKomComment" SG_ 950 VC_BU_TORQUE_CSO "Backup for veh config - customer settings menu 2 p";
BA_ "GenSigSNA" SG_ 950 VC_BU_TRLR_CSO "0h";
BA_ "GenSigSendType" SG_ 950 VC_BU_TRLR_CSO 1;
BA_ "FlexKomSigStartValue" SG_ 950 VC_BU_TRLR_CSO "0300000000000000h";
BA_ "FlexKomSigStartPos" SG_ 950 VC_BU_TRLR_CSO 7;
BA_ "FlexKomSigName" SG_ 950 VC_BU_TRLR_CSO "VehCfgCSM2_BuPkt";
BA_ "FlexKomSigLaenge" SG_ 950 VC_BU_TRLR_CSO 64;
BA_ "FlexKomSID" SG_ 950 VC_BU_TRLR_CSO 2009;
BA_ "FlexKomIsMotorola" SG_ 950 VC_BU_TRLR_CSO 1;
BA_ "FlexKomComment" SG_ 950 VC_BU_TRLR_CSO "Backup for veh config - customer settings menu 2 p";
BA_ "GenSigSNA" SG_ 950 VC_BU_TRLR_NAME_CSO "0h";
BA_ "GenSigSendType" SG_ 950 VC_BU_TRLR_NAME_CSO 1;
BA_ "FlexKomSigStartValue" SG_ 950 VC_BU_TRLR_NAME_CSO "0300000000000000h";
BA_ "FlexKomSigStartPos" SG_ 950 VC_BU_TRLR_NAME_CSO 7;
BA_ "FlexKomSigName" SG_ 950 VC_BU_TRLR_NAME_CSO "VehCfgCSM2_BuPkt";
BA_ "FlexKomSigLaenge" SG_ 950 VC_BU_TRLR_NAME_CSO 64;
BA_ "FlexKomSID" SG_ 950 VC_BU_TRLR_NAME_CSO 2009;
BA_ "FlexKomIsMotorola" SG_ 950 VC_BU_TRLR_NAME_CSO 1;
BA_ "FlexKomComment" SG_ 950 VC_BU_TRLR_NAME_CSO "Backup for veh config - customer settings menu 2 p";
BA_ "GenSigSNA" SG_ 950 VC_BU_TRLR_TYPE_CSO "0h";
BA_ "GenSigSendType" SG_ 950 VC_BU_TRLR_TYPE_CSO 1;
BA_ "FlexKomSigStartValue" SG_ 950 VC_BU_TRLR_TYPE_CSO "0300000000000000h";
BA_ "FlexKomSigStartPos" SG_ 950 VC_BU_TRLR_TYPE_CSO 7;
BA_ "FlexKomSigName" SG_ 950 VC_BU_TRLR_TYPE_CSO "VehCfgCSM2_BuPkt";
BA_ "FlexKomSigLaenge" SG_ 950 VC_BU_TRLR_TYPE_CSO 64;
BA_ "FlexKomSID" SG_ 950 VC_BU_TRLR_TYPE_CSO 2009;
BA_ "FlexKomIsMotorola" SG_ 950 VC_BU_TRLR_TYPE_CSO 1;
BA_ "FlexKomComment" SG_ 950 VC_BU_TRLR_TYPE_CSO "Backup for veh config - customer settings menu 2 p";
BA_ "GenSigSNA" SG_ 950 VC_BU_TRNS_MD_CSO "0h";
BA_ "GenSigSendType" SG_ 950 VC_BU_TRNS_MD_CSO 1;
BA_ "FlexKomSigStartValue" SG_ 950 VC_BU_TRNS_MD_CSO "0300000000000000h";
BA_ "FlexKomSigStartPos" SG_ 950 VC_BU_TRNS_MD_CSO 7;
BA_ "FlexKomSigName" SG_ 950 VC_BU_TRNS_MD_CSO "VehCfgCSM2_BuPkt";
BA_ "FlexKomSigLaenge" SG_ 950 VC_BU_TRNS_MD_CSO 64;
BA_ "FlexKomSID" SG_ 950 VC_BU_TRNS_MD_CSO 2009;
BA_ "FlexKomIsMotorola" SG_ 950 VC_BU_TRNS_MD_CSO 1;
BA_ "FlexKomComment" SG_ 950 VC_BU_TRNS_MD_CSO "Backup for veh config - customer settings menu 2 p";
BA_ "GenSigSNA" SG_ 950 VC_BU_US_METRIC_CSO "0h";
BA_ "GenSigSendType" SG_ 950 VC_BU_US_METRIC_CSO 1;
BA_ "FlexKomSigStartValue" SG_ 950 VC_BU_US_METRIC_CSO "0300000000000000h";
BA_ "FlexKomSigStartPos" SG_ 950 VC_BU_US_METRIC_CSO 7;
BA_ "FlexKomSigName" SG_ 950 VC_BU_US_METRIC_CSO "VehCfgCSM2_BuPkt";
BA_ "FlexKomSigLaenge" SG_ 950 VC_BU_US_METRIC_CSO 64;
BA_ "FlexKomSID" SG_ 950 VC_BU_US_METRIC_CSO 2009;
BA_ "FlexKomIsMotorola" SG_ 950 VC_BU_US_METRIC_CSO 1;
BA_ "FlexKomComment" SG_ 950 VC_BU_US_METRIC_CSO "Backup for veh config - customer settings menu 2 p";
BA_ "GenSigSNA" SG_ 950 VC_BU_WHL_ALGN_CSO "0h";
BA_ "GenSigSendType" SG_ 950 VC_BU_WHL_ALGN_CSO 1;
BA_ "FlexKomSigStartValue" SG_ 950 VC_BU_WHL_ALGN_CSO "0300000000000000h";
BA_ "FlexKomSigStartPos" SG_ 950 VC_BU_WHL_ALGN_CSO 7;
BA_ "FlexKomSigName" SG_ 950 VC_BU_WHL_ALGN_CSO "VehCfgCSM2_BuPkt";
BA_ "FlexKomSigLaenge" SG_ 950 VC_BU_WHL_ALGN_CSO 64;
BA_ "FlexKomSID" SG_ 950 VC_BU_WHL_ALGN_CSO 2009;
BA_ "FlexKomIsMotorola" SG_ 950 VC_BU_WHL_ALGN_CSO 1;
BA_ "FlexKomComment" SG_ 950 VC_BU_WHL_ALGN_CSO "Backup for veh config - customer settings menu 2 p";
BA_ "GenSigSNA" SG_ 950 VC_BU_FUEL_SAV_CSO "0h";
BA_ "GenSigSendType" SG_ 950 VC_BU_FUEL_SAV_CSO 1;
BA_ "FlexKomSigStartValue" SG_ 950 VC_BU_FUEL_SAV_CSO "0300000000000000h";
BA_ "FlexKomSigStartPos" SG_ 950 VC_BU_FUEL_SAV_CSO 7;
BA_ "FlexKomSigName" SG_ 950 VC_BU_FUEL_SAV_CSO "VehCfgCSM2_BuPkt";
BA_ "FlexKomSigLaenge" SG_ 950 VC_BU_FUEL_SAV_CSO 64;
BA_ "FlexKomSID" SG_ 950 VC_BU_FUEL_SAV_CSO 2009;
BA_ "FlexKomIsMotorola" SG_ 950 VC_BU_FUEL_SAV_CSO 1;
BA_ "FlexKomComment" SG_ 950 VC_BU_FUEL_SAV_CSO "Backup for veh config - customer settings menu 2 p";
BA_ "GenSigSNA" SG_ 950 VC_BU_TEMP_CSO "0h";
BA_ "GenSigSendType" SG_ 950 VC_BU_TEMP_CSO 1;
BA_ "FlexKomSigStartValue" SG_ 950 VC_BU_TEMP_CSO "0300000000000000h";
BA_ "FlexKomSigStartPos" SG_ 950 VC_BU_TEMP_CSO 7;
BA_ "FlexKomSigName" SG_ 950 VC_BU_TEMP_CSO "VehCfgCSM2_BuPkt";
BA_ "FlexKomSigLaenge" SG_ 950 VC_BU_TEMP_CSO 64;
BA_ "FlexKomSID" SG_ 950 VC_BU_TEMP_CSO 2009;
BA_ "FlexKomIsMotorola" SG_ 950 VC_BU_TEMP_CSO 1;
BA_ "FlexKomComment" SG_ 950 VC_BU_TEMP_CSO "Backup for veh config - customer settings menu 2 p";
VAL_ 941 B_MPG 1023 "SNA" ;
VAL_ 941 B_EV_Miles 16777215 "SNA" ;
VAL_ 941 B_EV_Kilometers 16777215 "SNA" ;
VAL_ 942 B_KMpL 1023 "SNA" ;
VAL_ 942 B_Hybrid_Miles 16777215 "SNA" ;
VAL_ 942 B_Hybrid_Kilometers 16777215 "SNA" ;
VAL_ 943 B_Total_Dist_Miles 16777215 "SNA" ;
VAL_ 943 B_Total_Dist_Kilometers 16777215 "SNA" ;
VAL_ 947 VC_PRK_AST_CSO 0 "Absent" 1 "Option_1_2" 2 "Option_2_3" ;
VAL_ 947 VC_FCW_CSO 0 "Absent" 1 "Option_1_2" 2 "Option_2_3" ;
VAL_ 947 VC_HRN_RMT_LK_CSO 0 "Absent" 1 "Option_1_2" 2 "Option_2_3" ;
VAL_ 947 VC_DCS_CSO 0 "Absent" 1 "Option_1_2" 2 "Option_2_3" ;
VAL_ 947 VC_AUX_SWS_CSO 0 "Absent" 1 "SWITCH_1_4" 2 "SWITCH_2_5" 3 "SWITCH_3_6" ;
VAL_ 947 VC_CMRA_GRDLNS_CSO 0 "Absent" 1 "STATIC" 2 "DYNAMIC" 3 "STATIC_DYNAMIC" ;
VAL_ 947 VC_VehCfgCSO1_Stat 0 "NA" 1 "PROGAMMED" 2 "REQUEST_DATA" 3 "SNA" ;
VAL_ 948 VC_SPEED_WARNING_CSO 0 "ABSENT" 1 "ONE" 2 "FIVE" ;
VAL_ 948 VC_VehCfgCSO2_Stat 0 "NA" 1 "PROGAMMED" 2 "REQUEST_DATA" 3 "SNA" ;
VAL_ 949 VC_BU_VehCfgCSO1_Stat 0 "NA" 1 "PROGAMMED" 2 "REQUEST_DATA" 3 "SNA" ;
VAL_ 949 VC_BU_PRK_AST_CSO 0 "Absent" 1 "Option_1_2" 2 "Option_2_3" ;
VAL_ 949 VC_BU_FCW_CSO 0 "Absent" 1 "Option_1_2" 2 "Option_2_3" ;
VAL_ 949 VC_BU_HRN_RMT_LK_CSO 0 "Absent" 1 "Option_1_2" 2 "Option_2_3" ;
VAL_ 949 VC_BU_DCS_CSO 0 "Absent" 1 "Option_1_2" 2 "Option_2_3" ;
VAL_ 949 VC_BU_AUX_SWS_CSO 0 "Absent" 1 "SWITCH_1_4" 2 "SWITCH_2_5" 3 "SWITCH_3_6" ;
VAL_ 949 VC_BU_CMRA_GRDLNS_CSO 0 "Absent" 1 "STATIC" 2 "DYNAMIC" 3 "STATIC_DYNAMIC" ;
VAL_ 950 VC_BU_SPEED_WARNING_CSO 0 "ABSENT" 1 "ONE" 2 "FIVE" ;
VAL_ 950 VC_BU_VehCfgCSO2_Stat 0 "NA" 1 "PROGAMMED" 2 "REQUEST_DATA" 3 "SNA" ;
